[part 1 of 3: packages /MICROSAR/Dem_swc/DataTypes to /MICROSAR/Dem_swc/ComponentTypes]
AUTOSAR XML (schema 00050)
package /MICROSAR/Dem_swc/DataTypes
  28 x impl type:
    Dem_EventIdType: range raw 1..65535, implementation-data-type=uint16
    Dem_RatioIdType: range raw 1..65535, implementation-data-type=uint16
    Dem_DTCStatusMaskType: range raw 0..255, implementation-data-type=uint8
    Dem_OperationCycleIdType: range raw 0..255, implementation-data-type=uint8
    Dem_DTCGroupType: range raw 0..16777215, implementation-data-type=uint32
    Dem_EventStatusType:
      compu {0=DEM_EVENT_STATUS_PASSED, 1=DEM_EVENT_STATUS_FAILED, 2=DEM_EVENT_STATUS_PREPASSED, 3=DEM_EVENT_STATUS_PREFAILED, 4=DEM_EVENT_STATUS_FDC_THRESHOLD_REACHED, 5=DEM_EVENT_STATUS_PASSED_CONDITIONS_NOT_FULFILLED, 6=DEM_EVENT_STATUS_FAILED_CONDITIONS_NOT_FULFILLED, 7=DEM_EVENT_STATUS_PREPASSED_CONDITIONS_NOT_FULFILLED, 8=DEM_EVENT_STATUS_PREFAILED_CONDITIONS_NOT_FULFILLED}
      range raw 0..255
      implementation-data-type=uint8
    Dem_InitMonitorReasonType: compu {1=DEM_INIT_MONITOR_CLEAR, 2=DEM_INIT_MONITOR_RESTART, 3=DEM_INIT_MONITOR_REENABLED, 4=DEM_INIT_MONITOR_STORAGE_REENABLED}, range raw 1..4, implementation-data-type=uint8
    Dem_DTCOriginType: compu {1=DEM_DTC_ORIGIN_PRIMARY_MEMORY, 2=DEM_DTC_ORIGIN_MIRROR_MEMORY, 3=DEM_DTC_ORIGIN_PERMANENT_MEMORY, 4=DEM_DTC_ORIGIN_OBD_RELEVANT_MEMORY, 256=DEM_DTC_ORIGIN_SECONDARY_MEMORY}, range raw 1..511, implementation-data-type=uint16
    Dem_DTCFormatType: compu {0=DEM_DTC_FORMAT_OBD, 1=DEM_DTC_FORMAT_UDS, 2=DEM_DTC_FORMAT_J1939}, range raw 0..2, implementation-data-type=uint8
    Dem_OperationCycleStateType: compu {0=DEM_CYCLE_STATE_START, 1=DEM_CYCLE_STATE_END}, range raw 0..1, implementation-data-type=uint8
    Dem_IndicatorStatusType: compu {0=DEM_INDICATOR_OFF, 1=DEM_INDICATOR_CONTINUOUS, 2=DEM_INDICATOR_BLINKING, 3=DEM_INDICATOR_BLINK_CONT, 4=DEM_INDICATOR_SLOW_FLASH, 5=DEM_INDICATOR_FAST_FLASH, 6=DEM_INDICATOR_ON_DEMAND, 7=DEM_INDICATOR_SHORT}, range raw 0..7, implementation-data-type=uint8
    Dem_DTCKindType: compu {1=DEM_DTC_KIND_ALL_DTCS, 2=DEM_DTC_KIND_EMISSION_REL_DTCS}, range raw 0..255, implementation-data-type=uint8
    Dem_IumprDenomCondIdType: compu {1=DEM_IUMPR_GENERAL_DENOMINATOR, 2=DEM_IUMPR_DEN_COND_COLDSTART, 3=DEM_IUMPR_DEN_COND_EVAP, 4=DEM_IUMPR_DEN_COND_500MI, 5=DEM_IUMPR_GENERAL_INDIVIDUAL_DENOMINATOR, 6=DEM_IUMPR_GENERAL_OBDCOND, 7=DEM_IUMPR_DEN_COND_INDEPENDENT}, range raw 0..255, implementation-data-type=uint8
    Dem_IumprDenomCondStatusType: compu {0=DEM_IUMPR_DEN_STATUS_NOT_REACHED, 1=DEM_IUMPR_DEN_STATUS_REACHED, 2=DEM_IUMPR_DEN_STATUS_INHIBITED}, range raw 0..255, implementation-data-type=uint8
    Dem_DebounceResetStatusType: compu {0=DEM_DEBOUNCE_STATUS_FREEZE, 1=DEM_DEBOUNCE_STATUS_RESET}, range raw 0..255, implementation-data-type=uint8
    Dem_IumprReadinessGroupType:
      compu {0=DEM_IUMPR_BOOSTPRS, 1=DEM_IUMPR_CAT1, 2=DEM_IUMPR_CAT2, 3=DEM_IUMPR_EGR, 4=DEM_IUMPR_EGSENSOR, 5=DEM_IUMPR_EVAP, 6=DEM_IUMPR_NMHCCAT, 7=DEM_IUMPR_NOXADSORB, 8=DEM_IUMPR_NOXCAT, 9=DEM_IUMPR_OXS1, 10=DEM_IUMPR_OXS2, 11=DEM_IUMPR_PMFILTER, 12=DEM_IUMPR_PRIVATE, 13=DEM_IUMPR_SAIR, 14=DEM_IUMPR_SECOXS1, 15=DEM_IUMPR_SECOXS2, 16=DEM_IUMPR_FLSYS, 17=DEM_IUMPR_AFRI1, 18=DEM_IUMPR_AFRI2, 19=DEM_IUMPR_PF1, 20=DEM_IUMPR_PF2, 255=DEM_IUMPR_ALLGROUPS}
      range raw 0..255
      implementation-data-type=uint8
    Dem_DTRControlType: compu {0=DEM_DTR_CTL_NORMAL, 1=DEM_DTR_CTL_NO_MAX, 2=DEM_DTR_CTL_NO_MIN, 3=DEM_DTR_CTL_RESET, 4=DEM_DTR_CTL_INVISIBLE}, range raw 0..255, implementation-data-type=uint8
    Dem_DebouncingStateType:
      compu {mask 1: 1=DEM_TEMPORARILY_DEFECTIVE (Bit 0: Temporarily Defective (corresponds to 0 < FDC < 127)), mask 2: 2=DEM_FINALLY_DEFECTIVE (Bit 1: Finally Defective (corresponds to FDC = 127)), mask 4: 4=DEM_TEMPORARILY_HEALED (Bit 2: Temporarily healed (corresponds to -128 < FDC < 0)), mask 8: 8=DEM_TEST_COMPLETE (Bit 3: Test complete (corresponds to FDC = -128 or FDC = 127)), mask 16: 16=DEM_DTR_UPDATE (Bit 4: DTR Update (= Test complete && Debouncing complete && enable conditions / storage conditions fulfilled))}
      range raw 0..255
      implementation-data-type=uint8
    Dem_DTCSeverityType:
      compu {mask 255: 0=DEM_SEVERITY_NO_SEVERITY (DTC_NO_SEVERITY) (No severity information available), mask 31: 1=DEM_SEVERITY_WWHOBD_CLASS_NO_CLASS (DTC_CLASS) (No class information), mask 31: 2=DEM_SEVERITY_WWHOBD_CLASS_A (DTC_CLASS) (WWH-OBD Class A), mask 31: 4=DEM_SEVERITY_WWHOBD_CLASS_B1 (DTC_CLASS) (WWH-OBD Class B1), mask 31: 8=DEM_SEVERITY_WWHOBD_CLASS_B2 (DTC_CLASS) (WWH-OBD Class B2), mask 31: 16=DEM_SEVERITY_WWHOBD_CLASS_C (DTC_CLASS) (WWH-OBD Class C), mask 224: 32=DEM_SEVERITY_MAINTENANCE_ONLY (DTC_SEVERITY) (Maintenance required), mask 224: 64=DEM_SEVERITY_CHECK_AT_NEXT_HALT (DTC_SEVERITY) (Check at next halt), mask 224: 128=DEM_SEVERITY_CHECK_IMMEDIATELY (DTC_SEVERITY) (Check immediately)}
      range raw 0..255
      implementation-data-type=uint8
    Dem_UdsStatusByteType:
      compu {mask 1: 1=DEM_UDS_STATUS_TF (bit 0: TestFailed), mask 2: 2=DEM_UDS_STATUS_TFTOC (bit 1: TestFailedThisOperationCycle), mask 4: 4=DEM_UDS_STATUS_PDTC (bit 2: PendingDTC), mask 8: 8=DEM_UDS_STATUS_CDTC (bit 3: ConfirmedDTC), mask 16: 16=DEM_UDS_STATUS_TNCSLC (bit 4: TestNotCompletedSinceLastClear), mask 32: 32=DEM_UDS_STATUS_TFSLC (bit 5: TestFailedSinceLastClear), mask 64: 64=DEM_UDS_STATUS_TNCTOC (bit 6: TestNotCompletedThisOperationCycle), mask 128: 128=DEM_UDS_STATUS_WIR (bit 7: WarningIndicatorRequested)}
      range raw 0..255
      implementation-data-type=uint8
    Dem_MonitorStatusType: compu {mask 1: 1=DEM_MONITOR_STATUS_TF (bit 0: TestFailed), mask 2: 2=DEM_MONITOR_STATUS_TNCTOC (bit 1: TestNotCompletedThisOperationCycle)}, range raw 0..255, implementation-data-type=uint8
    DataArrayType_uint8_1: category=ARRAY, sw-calibration-access=READ-ONLY
      element DataArrayType_uint8_1Element: array-size=1, array-size-semantics=FIXED-SIZE, implementation-data-type=uint8
    DataArrayType_uint8_3: category=ARRAY, sw-calibration-access=READ-ONLY
      element DataArrayType_uint8_3Element: array-size=3, array-size-semantics=FIXED-SIZE, implementation-data-type=uint8
    DataArrayType_uint8_2: category=ARRAY, sw-calibration-access=READ-ONLY
      element DataArrayType_uint8_2Element: array-size=2, array-size-semantics=FIXED-SIZE, implementation-data-type=uint8
    DataPrimitiveType_uint16: implementation-data-type=uint16
    DataArrayType_uint8_9: category=ARRAY, sw-calibration-access=READ-ONLY
      element DataArrayType_uint8_9Element: array-size=9, array-size-semantics=FIXED-SIZE, implementation-data-type=uint8
    DataPrimitiveType_uint8: implementation-data-type=uint8
    Dem_MaxDataValueType: category=ARRAY, sw-calibration-access=READ-ONLY
      element Dem_MaxDataValueTypeElement: array-size=51, array-size-semantics=FIXED-SIZE, implementation-data-type=uint8
package /MICROSAR/Dem_swc/Interfaces
  46 x client server interface, all with is-service=true, service-kind=DIAGNOSTIC-EVENT-MANAGER:
    DemServices
      operation GetPostRunRequested: possible-error=DemServices/E_NOT_OK
        arg IsRequested: type=boolean, direction=OUT
      operation GetDTCStatusAvailabilityMask: possible-error=DemServices/E_NOT_OK
        arg ClientId: type=uint8, direction=IN
        arg DTCStatusMask: type=uint8, direction=OUT
      error E_NOT_OK: error-code=1
    ClearDTC
      operation ClearDTC: possible-error=[ClearDTC/E_NOT_OK, DEM_CLEAR_FAILED, DEM_PENDING, DEM_CLEAR_BUSY, DEM_CLEAR_MEMORY_ERROR, DEM_WRONG_DTC, DEM_WRONG_DTCORIGIN]
      operation SelectDTC: possible-error=[ClearDTC/E_OK, ClearDTC/E_NOT_OK]
        arg DTC: type=uint32, direction=IN
        arg DTCFormat: type=Dem_DTCFormatType, direction=IN
        arg DTCOrigin: type=Dem_DTCOriginType, direction=IN
      8 x error:
        E_OK: error-code=0
        E_NOT_OK: error-code=1
        DEM_CLEAR_FAILED: error-code=7
        DEM_PENDING: error-code=4
        DEM_CLEAR_BUSY: error-code=5
        DEM_CLEAR_MEMORY_ERROR: error-code=6
        DEM_WRONG_DTC: error-code=8
        DEM_WRONG_DTCORIGIN: error-code=9
    EnableCondition
      operation SetEnableCondition: possible-error=EnableCondition/E_NOT_OK
        arg ConditionFulfilled: type=boolean, direction=IN
      error E_NOT_OK: error-code=1
    EvMemOverflowIndication
      operation GetEventMemoryOverflow: possible-error=EvMemOverflowIndication/E_NOT_OK
        arg OverflowIndication: type=boolean, direction=OUT
      operation GetNumberOfEventMemoryEntries: possible-error=EvMemOverflowIndication/E_NOT_OK
        arg NumberOfEventMemoryEntries: type=uint8, direction=OUT
      error E_NOT_OK: error-code=1
    GeneralDiagnosticInfo
      11 x operation:
        GetEventUdsStatus: possible-error=GeneralDiagnosticInfo/E_NOT_OK
          arg EventId: type=Dem_EventIdType, direction=IN
          arg UDSStatusByte: type=Dem_UdsStatusByteType, direction=OUT
        GetEventStatus: possible-error=GeneralDiagnosticInfo/E_NOT_OK
          arg EventId: type=Dem_EventIdType, direction=IN
          arg UDSStatusByte: type=Dem_UdsStatusByteType, direction=OUT
        GetEventFailed: possible-error=GeneralDiagnosticInfo/E_NOT_OK
          arg EventId: type=Dem_EventIdType, direction=IN
          arg EventFailed: type=boolean, direction=OUT
        GetEventTested: possible-error=GeneralDiagnosticInfo/E_NOT_OK
          arg EventId: type=Dem_EventIdType, direction=IN
          arg EventTested: type=boolean, direction=OUT
        GetDTCOfEvent: possible-error=[GeneralDiagnosticInfo/E_NOT_OK, GeneralDiagnosticInfo/DEM_E_NO_DTC_AVAILABLE]
          arg EventId: type=Dem_EventIdType, direction=IN
          arg DTCFormat: type=Dem_DTCFormatType, direction=IN
          arg DTCOfEvent: type=uint32, direction=OUT
        GetFaultDetectionCounter: possible-error=[GeneralDiagnosticInfo/E_NOT_OK, GeneralDiagnosticInfo/DEM_E_NO_FDC_AVAILABLE]
          arg EventId: type=Dem_EventIdType, direction=IN
          arg FaultDetectionCounter: type=sint8, direction=OUT
        GetEventFreezeFrameDataEx: possible-error=[GeneralDiagnosticInfo/E_NOT_OK, GeneralDiagnosticInfo/DEM_BUFFER_TOO_SMALL, GeneralDiagnosticInfo/DEM_NO_SUCH_ELEMENT]
          5 x arg:
            EventId: type=Dem_EventIdType, direction=IN
            RecordNumber: type=uint8, direction=IN
            DataId: type=uint16, direction=IN
            DestBuffer: type=Dem_MaxDataValueType, direction=OUT
            BufSize: type=uint16, direction=INOUT
        GetEventExtendedDataRecordEx: possible-error=[GeneralDiagnosticInfo/E_NOT_OK, GeneralDiagnosticInfo/DEM_BUFFER_TOO_SMALL, GeneralDiagnosticInfo/DEM_NO_SUCH_ELEMENT]
          4 x arg:
            EventId: type=Dem_EventIdType, direction=IN
            RecordNumber: type=uint8, direction=IN
            DestBuffer: type=Dem_MaxDataValueType, direction=OUT
            BufSize: type=uint16, direction=INOUT
        GetEventEnableCondition: possible-error=GeneralDiagnosticInfo/E_NOT_OK
          arg EventId: type=Dem_EventIdType, direction=IN
          arg ConditionFullfilled: type=boolean, direction=OUT
        GetDebouncingOfEvent: possible-error=GeneralDiagnosticInfo/E_NOT_OK
          arg EventId: type=Dem_EventIdType, direction=IN
          arg DebouncingState: type=Dem_DebouncingStateType, direction=OUT
        GetMonitorStatus: possible-error=GeneralDiagnosticInfo/E_NOT_OK
          arg EventId: type=Dem_EventIdType, direction=IN
          arg MonitorStatus: type=Dem_MonitorStatusType, direction=OUT
      5 x error:
        E_NOT_OK: error-code=1
        DEM_E_NO_DTC_AVAILABLE: error-code=10
        DEM_E_NO_FDC_AVAILABLE: error-code=14
        DEM_BUFFER_TOO_SMALL: error-code=21
        DEM_NO_SUCH_ELEMENT: error-code=48
    OperationCycle
      operation GetOperationCycleState: possible-error=[OperationCycle/E_OK, OperationCycle/E_NOT_OK]
        arg CycleState: type=Dem_OperationCycleStateType, direction=OUT
      operation SetOperationCycleState: possible-error=[OperationCycle/E_OK, OperationCycle/E_NOT_OK]
        arg CycleState: type=Dem_OperationCycleStateType, direction=IN
      error E_OK: error-code=0
      error E_NOT_OK: error-code=1
    CSDataServices_Data_DID_0x1004_Battery_Voltage_24
      operation ReadData: possible-error=CSDataServices_Data_DID_0x1004_Battery_Voltage_24/E_NOT_OK
        arg Data: type=DataArrayType_uint8_1, direction=OUT
      error E_NOT_OK: error-code=1
    CSDataServices_Data_DID_0x1008_ECU_Life_Time_24
      operation ReadData: possible-error=CSDataServices_Data_DID_0x1008_ECU_Life_Time_24/E_NOT_OK
        arg Data: type=DataArrayType_uint8_3, direction=OUT
      error E_NOT_OK: error-code=1
    CSDataServices_Data_DID_0x1009_ECU_Time_Since_Ignition_ON
      operation ReadData: possible-error=CSDataServices_Data_DID_0x1009_ECU_Time_Since_Ignition_ON/E_NOT_OK
        arg Data: type=DataArrayType_uint8_2, direction=OUT
      error E_NOT_OK: error-code=1
    CSDataServices_Data_OccurrenceCounter_Aging_Counter_ID
      operation ReadData: possible-error=CSDataServices_Data_OccurrenceCounter_Aging_Counter_ID/E_NOT_OK
        arg Data: type=DataPrimitiveType_uint16, direction=OUT
      error E_NOT_OK: error-code=1
    CSDataServices_Data_OccurrenceCounter_Frequency_Counter_ID
      operation ReadData: possible-error=CSDataServices_Data_OccurrenceCounter_Frequency_Counter_ID/E_NOT_OK
        arg Data: type=DataPrimitiveType_uint16, direction=OUT
      error E_NOT_OK: error-code=1
    CSDataServices_Data_DID_0x200a_Ignition_ON_Counter_24
      operation ReadData: possible-error=CSDataServices_Data_DID_0x200a_Ignition_ON_Counter_24/E_NOT_OK
        arg Data: type=DataArrayType_uint8_2, direction=OUT
      error E_NOT_OK: error-code=1
    CSDataServices_Data_DID_0x1002_Vehicle_Speed_24
      operation ReadData: possible-error=CSDataServices_Data_DID_0x1002_Vehicle_Speed_24/E_NOT_OK
        arg Data: type=DataArrayType_uint8_2, direction=OUT
      error E_NOT_OK: error-code=1
    CSDataServices_Data_DID_0x2001_Odometer_24
      operation ReadData: possible-error=CSDataServices_Data_DID_0x2001_Odometer_24/E_NOT_OK
        arg Data: type=DataArrayType_uint8_2, direction=OUT
      error E_NOT_OK: error-code=1
    CSDataServices_Data_OccurrenceCounter_Touch_Screen_Y_Coordinate
      operation ReadData: possible-error=CSDataServices_Data_OccurrenceCounter_Touch_Screen_Y_Coordinate/E_NOT_OK
        arg Data: type=DataPrimitiveType_uint16, direction=OUT
      error E_NOT_OK: error-code=1
    CSDataServices_Data_OccurrenceCounter_Odometer_Value
      operation ReadData: possible-error=CSDataServices_Data_OccurrenceCounter_Odometer_Value/E_NOT_OK
        arg Data: type=DataArrayType_uint8_3, direction=OUT
      error E_NOT_OK: error-code=1
    CSDataServices_Data_OccurrenceCounter_Camera_Occlusion
      operation ReadData: possible-error=CSDataServices_Data_OccurrenceCounter_Camera_Occlusion/E_NOT_OK
        arg Data: type=DataPrimitiveType_uint8, direction=OUT
      error E_NOT_OK: error-code=1
    CSDataServices_Data_OccurrenceCounter_THA_state
      operation ReadData: possible-error=CSDataServices_Data_OccurrenceCounter_THA_state/E_NOT_OK
        arg Data: type=DataPrimitiveType_uint8, direction=OUT
      error E_NOT_OK: error-code=1
    CSDataServices_Data_OccurrenceCounter_Supplier_Internal_Code
      operation ReadData: possible-error=CSDataServices_Data_OccurrenceCounter_Supplier_Internal_Code/E_NOT_OK
        arg EventId: type=Dem_EventIdType, direction=IN
        arg Data: type=DataArrayType_uint8_9, direction=OUT
      error E_NOT_OK: error-code=1
    CSDataServices_Data_OccurrenceCounter_Current_Gear
      operation ReadData: possible-error=CSDataServices_Data_OccurrenceCounter_Current_Gear/E_NOT_OK
        arg Data: type=DataPrimitiveType_uint8, direction=OUT
      error E_NOT_OK: error-code=1
    CSDataServices_Data_OccurrenceCounter_Vehicle_Speed
      operation ReadData: possible-error=CSDataServices_Data_OccurrenceCounter_Vehicle_Speed/E_NOT_OK
        arg Data: type=DataPrimitiveType_uint16, direction=OUT
      error E_NOT_OK: error-code=1
    CSDataServices_Data_OccurrenceCounter_DisplayStatus
      operation ReadData: possible-error=CSDataServices_Data_OccurrenceCounter_DisplayStatus/E_NOT_OK
        arg Data: type=DataPrimitiveType_uint8, direction=OUT
      error E_NOT_OK: error-code=1
    CSDataServices_Data_OccurrenceCounter_TRSC_Stat
      operation ReadData: possible-error=CSDataServices_Data_OccurrenceCounter_TRSC_Stat/E_NOT_OK
        arg Data: type=DataPrimitiveType_uint8, direction=OUT
      error E_NOT_OK: error-code=1
    CSDataServices_Data_OccurrenceCounter_ECU_Voltage
      operation ReadData: possible-error=CSDataServices_Data_OccurrenceCounter_ECU_Voltage/E_NOT_OK
        arg Data: type=DataPrimitiveType_uint8, direction=OUT
      error E_NOT_OK: error-code=1
    CSDataServices_Data_OccurrenceCounter_Touch_Screen_X_Coordinate
      operation ReadData: possible-error=CSDataServices_Data_OccurrenceCounter_Touch_Screen_X_Coordinate/E_NOT_OK
        arg Data: type=DataPrimitiveType_uint16, direction=OUT
      error E_NOT_OK: error-code=1
    CSDataServices_Data_OccurrenceCounter_Touch_Screen_Status
      operation ReadData: possible-error=CSDataServices_Data_OccurrenceCounter_Touch_Screen_Status/E_NOT_OK
        arg Data: type=DataPrimitiveType_uint8, direction=OUT
      error E_NOT_OK: error-code=1
    CSDataServices_Data_OccurrenceCounter_External_Temperature
      operation ReadData: possible-error=CSDataServices_Data_OccurrenceCounter_External_Temperature/E_NOT_OK
        arg Data: type=DataPrimitiveType_uint16, direction=OUT
      error E_NOT_OK: error-code=1
    CSDataServices_Data_OccurrenceCounter_TireLines
      operation ReadData: possible-error=CSDataServices_Data_OccurrenceCounter_TireLines/E_NOT_OK
        arg Data: type=DataPrimitiveType_uint8, direction=OUT
      error E_NOT_OK: error-code=1
    CSDataServices_Data_OccurrenceCounter_Door_Status
      operation ReadData: possible-error=CSDataServices_Data_OccurrenceCounter_Door_Status/E_NOT_OK
        arg Data: type=DataPrimitiveType_uint8, direction=OUT
      error E_NOT_OK: error-code=1
    CSDataServices_Data_OccurrenceCounter_Radio_Display_Status
      operation ReadData: possible-error=CSDataServices_Data_OccurrenceCounter_Radio_Display_Status/E_NOT_OK
        arg Data: type=DataPrimitiveType_uint8, direction=OUT
      error E_NOT_OK: error-code=1
    CSDataServices_Data_OccurrenceCounter_TRSKM_and_USS_status
      operation ReadData: possible-error=CSDataServices_Data_OccurrenceCounter_TRSKM_and_USS_status/E_NOT_OK
        arg Data: type=DataPrimitiveType_uint8, direction=OUT
      error E_NOT_OK: error-code=1
    CSDataServices_Data_OccurrenceCounter_LiftgateAjar
      operation ReadData: possible-error=CSDataServices_Data_OccurrenceCounter_LiftgateAjar/E_NOT_OK
        arg Data: type=DataPrimitiveType_uint8, direction=OUT
      error E_NOT_OK: error-code=1
    CSDataServices_Data_OccurrenceCounter_Cycles_to_Switch_off_the_Warning_Indication_ID
      operation ReadData: possible-error=CSDataServices_Data_OccurrenceCounter_Cycles_to_Switch_off_the_Warning_Indication_ID/E_NOT_OK
        arg Data: type=DataPrimitiveType_uint16, direction=OUT
      error E_NOT_OK: error-code=1
    CSDataServices_Data_OccurrenceCounter_Steering_Wheel_Angle
      operation ReadData: possible-error=CSDataServices_Data_OccurrenceCounter_Steering_Wheel_Angle/E_NOT_OK
        arg Data: type=DataPrimitiveType_uint16, direction=OUT
      error E_NOT_OK: error-code=1
    CSDataServices_Data_OccurrenceCounter_Reserved
      operation ReadData: possible-error=CSDataServices_Data_OccurrenceCounter_Reserved/E_NOT_OK
        arg Data: type=DataPrimitiveType_uint8, direction=OUT
      error E_NOT_OK: error-code=1
    CSDataServices_Data_OccurrenceCounter_Reserved_1
      operation ReadData: possible-error=CSDataServices_Data_OccurrenceCounter_Reserved_1/E_NOT_OK
        arg Data: type=DataPrimitiveType_uint8, direction=OUT
      error E_NOT_OK: error-code=1
    CSDataServices_Data_OccurrenceCounter_Calibration_Aborted_Failed
      operation ReadData: possible-error=CSDataServices_Data_OccurrenceCounter_Calibration_Aborted_Failed/E_NOT_OK
        arg Data: type=DataPrimitiveType_uint8, direction=OUT
      error E_NOT_OK: error-code=1
    CSDataServices_Data_OccurrenceCounter_Calibration_Pending
      operation ReadData: possible-error=CSDataServices_Data_OccurrenceCounter_Calibration_Pending/E_NOT_OK
        arg Data: type=DataPrimitiveType_uint8, direction=OUT
      error E_NOT_OK: error-code=1
    CSDataServices_Data_OccurrenceCounter_Calibration_Running
      operation ReadData: possible-error=CSDataServices_Data_OccurrenceCounter_Calibration_Running/E_NOT_OK
        arg Data: type=DataPrimitiveType_uint8, direction=OUT
      error E_NOT_OK: error-code=1
    CSDataServices_Data_OccurrenceCounter_New_Bit_Field
      operation ReadData: possible-error=CSDataServices_Data_OccurrenceCounter_New_Bit_Field/E_NOT_OK
        arg Data: type=DataPrimitiveType_uint8, direction=OUT
      error E_NOT_OK: error-code=1
    CSDataServices_Data_OccurrenceCounter_Calibration_Not_Started
      operation ReadData: possible-error=CSDataServices_Data_OccurrenceCounter_Calibration_Not_Started/E_NOT_OK
        arg Data: type=DataPrimitiveType_uint8, direction=OUT
      error E_NOT_OK: error-code=1
    CSDataServices_Data_OccurrenceCounter_Calibrated_Successfully
      operation ReadData: possible-error=CSDataServices_Data_OccurrenceCounter_Calibrated_Successfully/E_NOT_OK
        arg Data: type=DataPrimitiveType_uint8, direction=OUT
      error E_NOT_OK: error-code=1
    CSDataServices_Data_OccurrenceCounter_Reserved_2
      operation ReadData: possible-error=CSDataServices_Data_OccurrenceCounter_Reserved_2/E_NOT_OK
        arg Data: type=DataPrimitiveType_uint8, direction=OUT
      error E_NOT_OK: error-code=1
    DiagnosticInfo
      11 x operation:
        GetEventUdsStatus: possible-error=DiagnosticInfo/E_NOT_OK
          arg UDSStatusByte: type=Dem_UdsStatusByteType, direction=OUT
        GetEventStatus: possible-error=DiagnosticInfo/E_NOT_OK
          arg UDSStatusByte: type=Dem_UdsStatusByteType, direction=OUT
        GetEventFailed: possible-error=DiagnosticInfo/E_NOT_OK
          arg EventFailed: type=boolean, direction=OUT
        GetEventTested: possible-error=DiagnosticInfo/E_NOT_OK
          arg EventTested: type=boolean, direction=OUT
        GetDTCOfEvent: possible-error=[DiagnosticInfo/E_NOT_OK, DiagnosticInfo/DEM_E_NO_DTC_AVAILABLE]
          arg DTCFormat: type=Dem_DTCFormatType, direction=IN
          arg DTCOfEvent: type=uint32, direction=OUT
        GetFaultDetectionCounter: possible-error=[DiagnosticInfo/E_NOT_OK, DiagnosticInfo/DEM_E_NO_FDC_AVAILABLE]
          arg FaultDetectionCounter: type=sint8, direction=OUT
        GetEventFreezeFrameDataEx: possible-error=[DiagnosticInfo/E_NOT_OK, DiagnosticInfo/DEM_BUFFER_TOO_SMALL, DiagnosticInfo/DEM_NO_SUCH_ELEMENT]
          4 x arg:
            RecordNumber: type=uint8, direction=IN
            DataId: type=uint16, direction=IN
            DestBuffer: type=Dem_MaxDataValueType, direction=OUT
            BufSize: type=uint16, direction=INOUT
        GetEventExtendedDataRecordEx: possible-error=[DiagnosticInfo/E_NOT_OK, DiagnosticInfo/DEM_BUFFER_TOO_SMALL, DiagnosticInfo/DEM_NO_SUCH_ELEMENT]
          arg RecordNumber: type=uint8, direction=IN
          arg DestBuffer: type=Dem_MaxDataValueType, direction=OUT
          arg BufSize: type=uint16, direction=INOUT
        GetEventEnableCondition: possible-error=DiagnosticInfo/E_NOT_OK
          arg ConditionFullfilled: type=boolean, direction=OUT
        GetDebouncingOfEvent: possible-error=DiagnosticInfo/E_NOT_OK
          arg DebouncingState: type=Dem_DebouncingStateType, direction=OUT
        GetMonitorStatus: possible-error=DiagnosticInfo/E_NOT_OK
          arg MonitorStatus: type=Dem_MonitorStatusType, direction=OUT
      5 x error:
        E_NOT_OK: error-code=1
        DEM_E_NO_DTC_AVAILABLE: error-code=10
        DEM_E_NO_FDC_AVAILABLE: error-code=14
        DEM_BUFFER_TOO_SMALL: error-code=21
        DEM_NO_SUCH_ELEMENT: error-code=48
    DiagnosticMonitor
      11 x operation:
        SetEventStatus: possible-error=DiagnosticMonitor/E_NOT_OK
          arg EventStatus: type=Dem_EventStatusType, direction=IN
        ResetEventStatus: possible-error=DiagnosticMonitor/E_NOT_OK
        ResetEventDebounceStatus: possible-error=DiagnosticMonitor/E_NOT_OK
          arg DebounceResetStatus: type=Dem_DebounceResetStatusType, direction=IN
        GetEventUdsStatus: possible-error=DiagnosticMonitor/E_NOT_OK
          arg UDSStatusByte: type=Dem_UdsStatusByteType, direction=OUT
        GetEventStatus: possible-error=DiagnosticMonitor/E_NOT_OK
          arg UDSStatusByte: type=Dem_UdsStatusByteType, direction=OUT
        GetEventFailed: possible-error=DiagnosticMonitor/E_NOT_OK
          arg EventFailed: type=boolean, direction=OUT
        GetEventTested: possible-error=DiagnosticMonitor/E_NOT_OK
          arg EventTested: type=boolean, direction=OUT
        GetDTCOfEvent: possible-error=[DiagnosticMonitor/E_NOT_OK, DiagnosticMonitor/DEM_E_NO_DTC_AVAILABLE]
          arg DTCFormat: type=Dem_DTCFormatType, direction=IN
          arg DTCOfEvent: type=uint32, direction=OUT
        GetFaultDetectionCounter: possible-error=[DiagnosticMonitor/E_NOT_OK, DiagnosticMonitor/DEM_E_NO_FDC_AVAILABLE]
          arg FaultDetectionCounter: type=sint8, direction=OUT
        GetEventFreezeFrameDataEx: possible-error=[DiagnosticMonitor/E_NOT_OK, DiagnosticMonitor/DEM_BUFFER_TOO_SMALL, DiagnosticMonitor/DEM_NO_SUCH_ELEMENT]
          4 x arg:
            RecordNumber: type=uint8, direction=IN
            DataId: type=uint16, direction=IN
            DestBuffer: type=Dem_MaxDataValueType, direction=OUT
            BufSize: type=uint16, direction=INOUT
        GetEventExtendedDataRecordEx: possible-error=[DiagnosticMonitor/E_NOT_OK, DiagnosticMonitor/DEM_BUFFER_TOO_SMALL, DiagnosticMonitor/DEM_NO_SUCH_ELEMENT]
          arg RecordNumber: type=uint8, direction=IN
          arg DestBuffer: type=Dem_MaxDataValueType, direction=OUT
          arg BufSize: type=uint16, direction=INOUT
      5 x error:
        E_NOT_OK: error-code=1
        DEM_E_NO_DTC_AVAILABLE: error-code=10
        DEM_E_NO_FDC_AVAILABLE: error-code=14
        DEM_BUFFER_TOO_SMALL: error-code=21
        DEM_NO_SUCH_ELEMENT: error-code=48
    CSDataServices_Data_DID_0x1921_CombinedSignal
      operation ReadData: possible-error=CSDataServices_Data_DID_0x1921_CombinedSignal/E_NOT_OK
        arg Data: type=DataArrayType_uint8_9, direction=OUT
      error E_NOT_OK: error-code=1
package /MICROSAR/Dem_swc/ComponentTypes
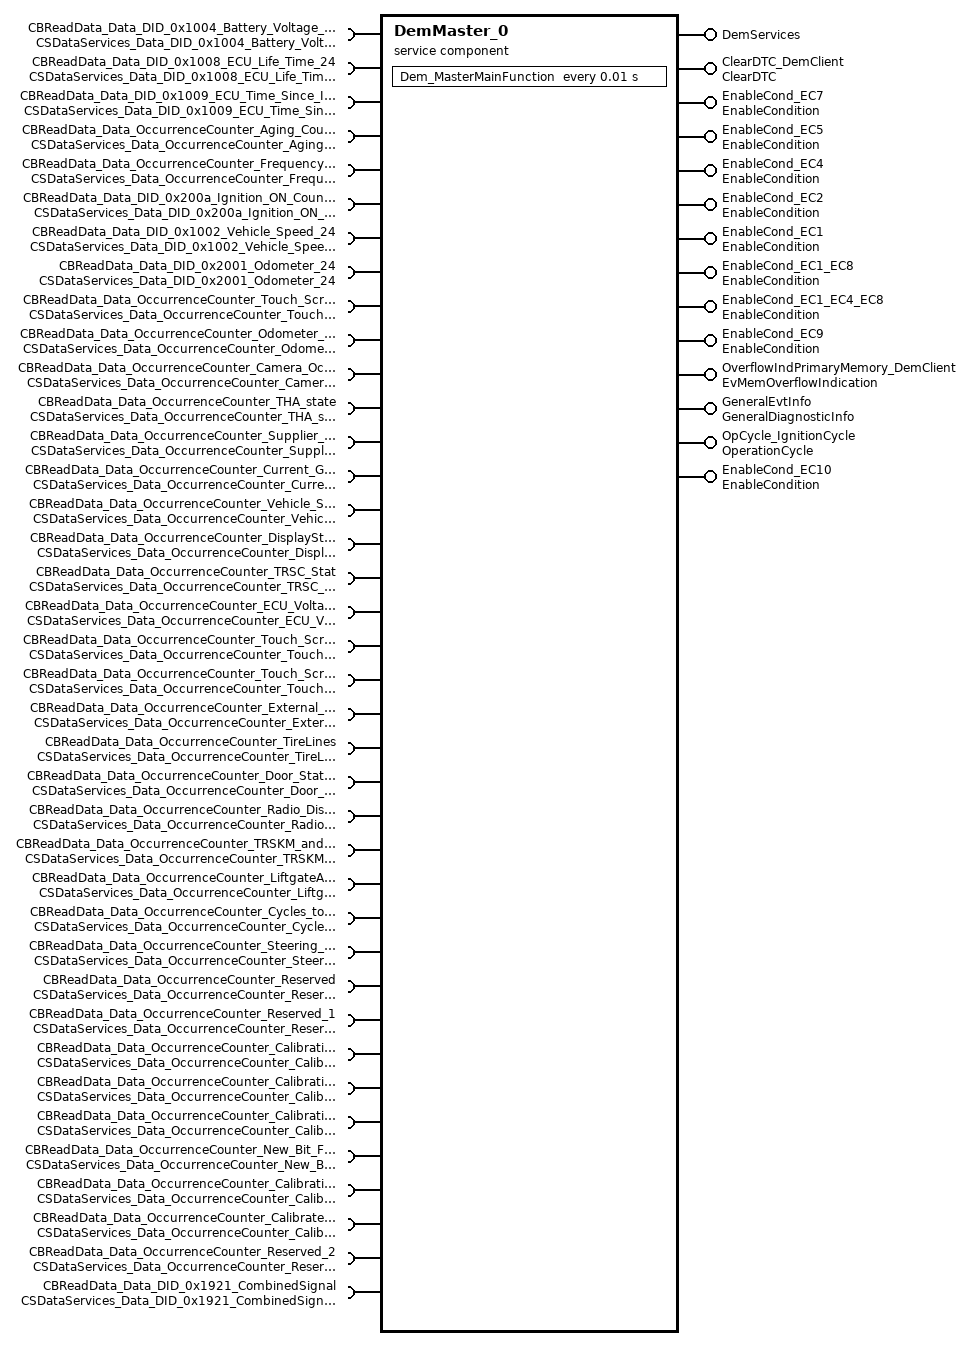
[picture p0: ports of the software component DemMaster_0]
  service sw component type DemMaster_0: category=SERVICE_COMPONENT
    13 x provide port:
      DemServices: provided-interface=DemServices
      ClearDTC_DemClient: provided-interface=ClearDTC
      EnableCond_EC7: provided-interface=EnableCondition
      EnableCond_EC5: provided-interface=EnableCondition
      EnableCond_EC4: provided-interface=EnableCondition
      EnableCond_EC2: provided-interface=EnableCondition
      EnableCond_EC1: provided-interface=EnableCondition
      EnableCond_EC1_EC8: provided-interface=EnableCondition
      EnableCond_EC1_EC4_EC8: provided-interface=EnableCondition
      EnableCond_EC9: provided-interface=EnableCondition
      OverflowIndPrimaryMemory_DemClient: provided-interface=EvMemOverflowIndication
      GeneralEvtInfo: provided-interface=GeneralDiagnosticInfo
      OpCycle_IgnitionCycle: provided-interface=OperationCycle
    38 x require port:
      CBReadData_Data_DID_0x1004_Battery_Voltage_24: required-interface=CSDataServices_Data_DID_0x1004_Battery_Voltage_24
      CBReadData_Data_DID_0x1008_ECU_Life_Time_24: required-interface=CSDataServices_Data_DID_0x1008_ECU_Life_Time_24
      CBReadData_Data_DID_0x1009_ECU_Time_Since_Ignition_ON: required-interface=CSDataServices_Data_DID_0x1009_ECU_Time_Since_Ignition_ON
      CBReadData_Data_OccurrenceCounter_Aging_Counter_ID: required-interface=CSDataServices_Data_OccurrenceCounter_Aging_Counter_ID
      CBReadData_Data_OccurrenceCounter_Frequency_Counter_ID: required-interface=CSDataServices_Data_OccurrenceCounter_Frequency_Counter_ID
      CBReadData_Data_DID_0x200a_Ignition_ON_Counter_24: required-interface=CSDataServices_Data_DID_0x200a_Ignition_ON_Counter_24
      CBReadData_Data_DID_0x1002_Vehicle_Speed_24: required-interface=CSDataServices_Data_DID_0x1002_Vehicle_Speed_24
      CBReadData_Data_DID_0x2001_Odometer_24: required-interface=CSDataServices_Data_DID_0x2001_Odometer_24
      CBReadData_Data_OccurrenceCounter_Touch_Screen_Y_Coordinate: required-interface=CSDataServices_Data_OccurrenceCounter_Touch_Screen_Y_Coordinate
      CBReadData_Data_OccurrenceCounter_Odometer_Value: required-interface=CSDataServices_Data_OccurrenceCounter_Odometer_Value
      CBReadData_Data_OccurrenceCounter_Camera_Occlusion: required-interface=CSDataServices_Data_OccurrenceCounter_Camera_Occlusion
      CBReadData_Data_OccurrenceCounter_THA_state: required-interface=CSDataServices_Data_OccurrenceCounter_THA_state
      CBReadData_Data_OccurrenceCounter_Supplier_Internal_Code: required-interface=CSDataServices_Data_OccurrenceCounter_Supplier_Internal_Code
      CBReadData_Data_OccurrenceCounter_Current_Gear: required-interface=CSDataServices_Data_OccurrenceCounter_Current_Gear
      CBReadData_Data_OccurrenceCounter_Vehicle_Speed: required-interface=CSDataServices_Data_OccurrenceCounter_Vehicle_Speed
      CBReadData_Data_OccurrenceCounter_DisplayStatus: required-interface=CSDataServices_Data_OccurrenceCounter_DisplayStatus
      CBReadData_Data_OccurrenceCounter_TRSC_Stat: required-interface=CSDataServices_Data_OccurrenceCounter_TRSC_Stat
      CBReadData_Data_OccurrenceCounter_ECU_Voltage: required-interface=CSDataServices_Data_OccurrenceCounter_ECU_Voltage
      CBReadData_Data_OccurrenceCounter_Touch_Screen_X_Coordinate: required-interface=CSDataServices_Data_OccurrenceCounter_Touch_Screen_X_Coordinate
      CBReadData_Data_OccurrenceCounter_Touch_Screen_Status: required-interface=CSDataServices_Data_OccurrenceCounter_Touch_Screen_Status
      CBReadData_Data_OccurrenceCounter_External_Temperature: required-interface=CSDataServices_Data_OccurrenceCounter_External_Temperature
      CBReadData_Data_OccurrenceCounter_TireLines: required-interface=CSDataServices_Data_OccurrenceCounter_TireLines
      CBReadData_Data_OccurrenceCounter_Door_Status: required-interface=CSDataServices_Data_OccurrenceCounter_Door_Status
      CBReadData_Data_OccurrenceCounter_Radio_Display_Status: required-interface=CSDataServices_Data_OccurrenceCounter_Radio_Display_Status
      CBReadData_Data_OccurrenceCounter_TRSKM_and_USS_status: required-interface=CSDataServices_Data_OccurrenceCounter_TRSKM_and_USS_status
      CBReadData_Data_OccurrenceCounter_LiftgateAjar: required-interface=CSDataServices_Data_OccurrenceCounter_LiftgateAjar
      CBReadData_Data_OccurrenceCounter_Cycles_to_Switch_off_the_Warning_Indication_ID: required-interface=CSDataServices_Data_OccurrenceCounter_Cycles_to_Switch_off_the_Warning_Indication_ID
      CBReadData_Data_OccurrenceCounter_Steering_Wheel_Angle: required-interface=CSDataServices_Data_OccurrenceCounter_Steering_Wheel_Angle
      CBReadData_Data_OccurrenceCounter_Reserved: required-interface=CSDataServices_Data_OccurrenceCounter_Reserved
      CBReadData_Data_OccurrenceCounter_Reserved_1: required-interface=CSDataServices_Data_OccurrenceCounter_Reserved_1
      CBReadData_Data_OccurrenceCounter_Calibration_Aborted_Failed: required-interface=CSDataServices_Data_OccurrenceCounter_Calibration_Aborted_Failed
      CBReadData_Data_OccurrenceCounter_Calibration_Pending: required-interface=CSDataServices_Data_OccurrenceCounter_Calibration_Pending
      CBReadData_Data_OccurrenceCounter_Calibration_Running: required-interface=CSDataServices_Data_OccurrenceCounter_Calibration_Running
      CBReadData_Data_OccurrenceCounter_New_Bit_Field: required-interface=CSDataServices_Data_OccurrenceCounter_New_Bit_Field
      CBReadData_Data_OccurrenceCounter_Calibration_Not_Started: required-interface=CSDataServices_Data_OccurrenceCounter_Calibration_Not_Started
      CBReadData_Data_OccurrenceCounter_Calibrated_Successfully: required-interface=CSDataServices_Data_OccurrenceCounter_Calibrated_Successfully
      CBReadData_Data_OccurrenceCounter_Reserved_2: required-interface=CSDataServices_Data_OccurrenceCounter_Reserved_2
      CBReadData_Data_DID_0x1921_CombinedSignal: required-interface=CSDataServices_Data_DID_0x1921_CombinedSignal
    provide port EnableCond_EC10: provided-interface=EnableCondition
    behavior DemMaster_0InternalBehavior: handle-termination-and-restart=NO-SUPPORT, included-data-type-set=data-type=[Dem_EventIdType, Dem_RatioIdType, Dem_EventStatusType, Dem_UdsStatusByteType, Dem_DTCFormatType, Dem_InitMonitorReasonType, Dem_OperationCycleStateType, Dem_DTCStatusMaskType, Dem_IndicatorStatusType, Dem_MaxDataValueType, Dem_DTCKindType, Dem_DTCGroupType, Dem_IumprDenomCondIdType, Dem_IumprDenomCondStatusType, Dem_DebounceResetStatusType, Dem_DebouncingStateType, Dem_IumprReadinessGroupType, Dem_DTRControlType, Dem_DTCSeverityType, Dem_MonitorStatusType]
      timing event Timer_Dem_MasterMainFunction: start-on-event=Dem_MasterMainFunction, period=0.01
      28 x operation invoked event:
        OpEventPostRunRequested_GetPostRunRequested_DemServices: start-on-event=PostRunRequested, operation=DemServices.GetPostRunRequested
        OpEventGetDTCStatusAvailabilityMask_GetDTCStatusAvailabilityMask_DemServices: start-on-event=GetDTCStatusAvailabilityMask, operation=DemServices.GetDTCStatusAvailabilityMask
        OpEventClearDTC_ClearDTC_ClearDTC_DemClient: start-on-event=ClearDTC, operation=ClearDTC_DemClient.ClearDTC
        OpEventSelectDTC_SelectDTC_ClearDTC_DemClient: start-on-event=SelectDTC, operation=ClearDTC_DemClient.SelectDTC
        OpEventSetEnableCondition_SetEnableCondition_EnableCond_EC7: start-on-event=SetEnableCondition, operation=EnableCond_EC7.SetEnableCondition
        OpEventSetEnableCondition_SetEnableCondition_EnableCond_EC5: start-on-event=SetEnableCondition, operation=EnableCond_EC5.SetEnableCondition
        OpEventSetEnableCondition_SetEnableCondition_EnableCond_EC4: start-on-event=SetEnableCondition, operation=EnableCond_EC4.SetEnableCondition
        OpEventSetEnableCondition_SetEnableCondition_EnableCond_EC2: start-on-event=SetEnableCondition, operation=EnableCond_EC2.SetEnableCondition
        OpEventSetEnableCondition_SetEnableCondition_EnableCond_EC1: start-on-event=SetEnableCondition, operation=EnableCond_EC1.SetEnableCondition
        OpEventSetEnableCondition_SetEnableCondition_EnableCond_EC1_EC8: start-on-event=SetEnableCondition, operation=EnableCond_EC1_EC8.SetEnableCondition
        OpEventSetEnableCondition_SetEnableCondition_EnableCond_EC1_EC4_EC8: start-on-event=SetEnableCondition, operation=EnableCond_EC1_EC4_EC8.SetEnableCondition
        OpEventSetEnableCondition_SetEnableCondition_EnableCond_EC9: start-on-event=SetEnableCondition, operation=EnableCond_EC9.SetEnableCondition
        OpEventGetEventMemoryOverflow_GetEventMemoryOverflow_OverflowIndPrimaryMemory_DemClient: start-on-event=GetEventMemoryOverflow, operation=OverflowIndPrimaryMemory_DemClient.GetEventMemoryOverflow
        OpEventGetNumberOfEventMemoryEntries_GetNumberOfEventMemoryEntries_OverflowIndPrimaryMemory_DemClient: start-on-event=GetNumberOfEventMemoryEntries, operation=OverflowIndPrimaryMemory_DemClient.GetNumberOfEventMemoryEntries
        OpEventGetEventUdsStatus_GetEventUdsStatus_GeneralEvtInfo: start-on-event=DemMaster_0InternalBehavior/GetEventUdsStatus, operation=GeneralEvtInfo.GetEventUdsStatus
        OpEventGetEventStatus_GetEventStatus_GeneralEvtInfo: start-on-event=DemMaster_0InternalBehavior/GetEventStatus, operation=GeneralEvtInfo.GetEventStatus
        OpEventGetEventFailed_GetEventFailed_GeneralEvtInfo: start-on-event=DemMaster_0InternalBehavior/GetEventFailed, operation=GeneralEvtInfo.GetEventFailed
        OpEventGetEventTested_GetEventTested_GeneralEvtInfo: start-on-event=DemMaster_0InternalBehavior/GetEventTested, operation=GeneralEvtInfo.GetEventTested
        OpEventGetDTCOfEvent_GetDTCOfEvent_GeneralEvtInfo: start-on-event=DemMaster_0InternalBehavior/GetDTCOfEvent, operation=GeneralEvtInfo.GetDTCOfEvent
        OpEventGetFaultDetectionCounter_GetFaultDetectionCounter_GeneralEvtInfo: start-on-event=DemMaster_0InternalBehavior/GetFaultDetectionCounter, operation=GeneralEvtInfo.GetFaultDetectionCounter
        OpEventGetEventFreezeFrameDataEx_GetEventFreezeFrameDataEx_GeneralEvtInfo: start-on-event=DemMaster_0InternalBehavior/GetEventFreezeFrameDataEx, operation=GeneralEvtInfo.GetEventFreezeFrameDataEx
        OpEventGetEventExtendedDataRecordEx_GetEventExtendedDataRecordEx_GeneralEvtInfo: start-on-event=DemMaster_0InternalBehavior/GetEventExtendedDataRecordEx, operation=GeneralEvtInfo.GetEventExtendedDataRecordEx
        OpEventGetEventEnableCondition_GetEventEnableCondition_GeneralEvtInfo: start-on-event=DemMaster_0InternalBehavior/GetEventEnableCondition, operation=GeneralEvtInfo.GetEventEnableCondition
        OpEventGetDebouncingOfEvent_GetDebouncingOfEvent_GeneralEvtInfo: start-on-event=DemMaster_0InternalBehavior/GetDebouncingOfEvent, operation=GeneralEvtInfo.GetDebouncingOfEvent
        OpEventGetMonitorStatus_GetMonitorStatus_GeneralEvtInfo: start-on-event=DemMaster_0InternalBehavior/GetMonitorStatus, operation=GeneralEvtInfo.GetMonitorStatus
        OpEventGetOperationCycleState_GetOperationCycleState_OpCycle_IgnitionCycle: start-on-event=GetOperationCycleState, operation=OpCycle_IgnitionCycle.GetOperationCycleState
        OpEventSetOperationCycleState_SetOperationCycleState_OpCycle_IgnitionCycle: start-on-event=SetOperationCycleState, operation=OpCycle_IgnitionCycle.SetOperationCycleState
        OpEventSetEnableCondition_SetEnableCondition_EnableCond_EC10: start-on-event=SetEnableCondition, operation=EnableCond_EC10.SetEnableCondition
      port-api-options:
        enable-take-address=true, indirect-api=false, port=DemServices
        {enable-take-address=true, indirect-api=false, port-defined-argument-value{value=0, value-type=uint8}, port=ClearDTC_DemClient}
        {enable-take-address=true, indirect-api=false, port-defined-argument-value{value=7, value-type=uint8}, port=EnableCond_EC7}
        {enable-take-address=true, indirect-api=false, port-defined-argument-value{value=6, value-type=uint8}, port=EnableCond_EC5}
        {enable-take-address=true, indirect-api=false, port-defined-argument-value{value=5, value-type=uint8}, port=EnableCond_EC4}
        {enable-take-address=true, indirect-api=false, port-defined-argument-value{value=4, value-type=uint8}, port=EnableCond_EC2}
        {enable-take-address=true, indirect-api=false, port-defined-argument-value{value=1, value-type=uint8}, port=EnableCond_EC1}
        {enable-take-address=true, indirect-api=false, port-defined-argument-value{value=3, value-type=uint8}, port=EnableCond_EC1_EC8}
        {enable-take-address=true, indirect-api=false, port-defined-argument-value{value=2, value-type=uint8}, port=EnableCond_EC1_EC4_EC8}
        {enable-take-address=true, indirect-api=false, port-arg-values=[{value=0, value-type=uint8}, {value=1, value-type=Dem_DTCOriginType}], port=OverflowIndPrimaryMemory_DemClient}
        enable-take-address=true, indirect-api=false, port=DemMaster_0/GeneralEvtInfo
        {enable-take-address=true, indirect-api=false, port-defined-argument-value{value=0, value-type=uint8}, port=OpCycle_IgnitionCycle}
        enable-take-address=true, indirect-api=false, port=DemMaster_0/CBReadData_Data_DID_0x1004_Battery_Voltage_24
        enable-take-address=true, indirect-api=false, port=DemMaster_0/CBReadData_Data_DID_0x1008_ECU_Life_Time_24
        enable-take-address=true, indirect-api=false, port=DemMaster_0/CBReadData_Data_DID_0x1009_ECU_Time_Since_Ignition_ON
        enable-take-address=true, indirect-api=false, port=DemMaster_0/CBReadData_Data_OccurrenceCounter_Aging_Counter_ID
        enable-take-address=true, indirect-api=false, port=DemMaster_0/CBReadData_Data_OccurrenceCounter_Frequency_Counter_ID
        enable-take-address=true, indirect-api=false, port=DemMaster_0/CBReadData_Data_DID_0x200a_Ignition_ON_Counter_24
        enable-take-address=true, indirect-api=false, port=DemMaster_0/CBReadData_Data_DID_0x1002_Vehicle_Speed_24
        enable-take-address=true, indirect-api=false, port=DemMaster_0/CBReadData_Data_DID_0x2001_Odometer_24
        enable-take-address=true, indirect-api=false, port=DemMaster_0/CBReadData_Data_OccurrenceCounter_Touch_Screen_Y_Coordinate
        enable-take-address=true, indirect-api=false, port=DemMaster_0/CBReadData_Data_OccurrenceCounter_Odometer_Value
        enable-take-address=true, indirect-api=false, port=DemMaster_0/CBReadData_Data_OccurrenceCounter_Camera_Occlusion
        enable-take-address=true, indirect-api=false, port=DemMaster_0/CBReadData_Data_OccurrenceCounter_THA_state
        enable-take-address=true, indirect-api=false, port=DemMaster_0/CBReadData_Data_OccurrenceCounter_Supplier_Internal_Code
        enable-take-address=true, indirect-api=false, port=DemMaster_0/CBReadData_Data_OccurrenceCounter_Current_Gear
        enable-take-address=true, indirect-api=false, port=DemMaster_0/CBReadData_Data_OccurrenceCounter_Vehicle_Speed
        enable-take-address=true, indirect-api=false, port=DemMaster_0/CBReadData_Data_OccurrenceCounter_DisplayStatus
        enable-take-address=true, indirect-api=false, port=DemMaster_0/CBReadData_Data_OccurrenceCounter_TRSC_Stat
        enable-take-address=true, indirect-api=false, port=DemMaster_0/CBReadData_Data_OccurrenceCounter_ECU_Voltage
        enable-take-address=true, indirect-api=false, port=DemMaster_0/CBReadData_Data_OccurrenceCounter_Touch_Screen_X_Coordinate
        enable-take-address=true, indirect-api=false, port=DemMaster_0/CBReadData_Data_OccurrenceCounter_Touch_Screen_Status
        enable-take-address=true, indirect-api=false, port=DemMaster_0/CBReadData_Data_OccurrenceCounter_External_Temperature
        enable-take-address=true, indirect-api=false, port=DemMaster_0/CBReadData_Data_OccurrenceCounter_TireLines
        enable-take-address=true, indirect-api=false, port=DemMaster_0/CBReadData_Data_OccurrenceCounter_Door_Status
        enable-take-address=true, indirect-api=false, port=DemMaster_0/CBReadData_Data_OccurrenceCounter_Radio_Display_Status
        enable-take-address=true, indirect-api=false, port=DemMaster_0/CBReadData_Data_OccurrenceCounter_TRSKM_and_USS_status
        enable-take-address=true, indirect-api=false, port=DemMaster_0/CBReadData_Data_OccurrenceCounter_LiftgateAjar
        enable-take-address=true, indirect-api=false, port=DemMaster_0/CBReadData_Data_OccurrenceCounter_Cycles_to_Switch_off_the_Warning_Indication_ID
        enable-take-address=true, indirect-api=false, port=DemMaster_0/CBReadData_Data_OccurrenceCounter_Steering_Wheel_Angle
        enable-take-address=true, indirect-api=false, port=DemMaster_0/CBReadData_Data_OccurrenceCounter_Reserved
        enable-take-address=true, indirect-api=false, port=DemMaster_0/CBReadData_Data_OccurrenceCounter_Reserved_1
        enable-take-address=true, indirect-api=false, port=DemMaster_0/CBReadData_Data_OccurrenceCounter_Calibration_Aborted_Failed
        enable-take-address=true, indirect-api=false, port=DemMaster_0/CBReadData_Data_OccurrenceCounter_Calibration_Pending
        enable-take-address=true, indirect-api=false, port=DemMaster_0/CBReadData_Data_OccurrenceCounter_Calibration_Running
        enable-take-address=true, indirect-api=false, port=DemMaster_0/CBReadData_Data_OccurrenceCounter_New_Bit_Field
        enable-take-address=true, indirect-api=false, port=DemMaster_0/CBReadData_Data_OccurrenceCounter_Calibration_Not_Started
        enable-take-address=true, indirect-api=false, port=DemMaster_0/CBReadData_Data_OccurrenceCounter_Calibrated_Successfully
        enable-take-address=true, indirect-api=false, port=DemMaster_0/CBReadData_Data_OccurrenceCounter_Reserved_2
        enable-take-address=true, indirect-api=false, port=DemMaster_0/CBReadData_Data_DID_0x1921_CombinedSignal
        {enable-take-address=true, indirect-api=false, port-defined-argument-value{value=8, value-type=uint8}, port=EnableCond_EC9}
        {enable-take-address=true, indirect-api=false, port-defined-argument-value{value=9, value-type=uint8}, port=EnableCond_EC10}
      21 x runnable:
        Dem_MasterMainFunction
          38 x sync call, all with timeout=0:
            OpServerCallDem_MasterMainFunction_ReadData_CBReadData_Data_DID_0x1004_Battery_Voltage_24: operation=CBReadData_Data_DID_0x1004_Battery_Voltage_24.ReadData
            OpServerCallDem_MasterMainFunction_ReadData_CBReadData_Data_DID_0x1008_ECU_Life_Time_24: operation=CBReadData_Data_DID_0x1008_ECU_Life_Time_24.ReadData
            OpServerCallDem_MasterMainFunction_ReadData_CBReadData_Data_DID_0x1009_ECU_Time_Since_Ignition_ON: operation=CBReadData_Data_DID_0x1009_ECU_Time_Since_Ignition_ON.ReadData
            OpServerCallDem_MasterMainFunction_ReadData_CBReadData_Data_OccurrenceCounter_Aging_Counter_ID: operation=CBReadData_Data_OccurrenceCounter_Aging_Counter_ID.ReadData
            OpServerCallDem_MasterMainFunction_ReadData_CBReadData_Data_OccurrenceCounter_Frequency_Counter_ID: operation=CBReadData_Data_OccurrenceCounter_Frequency_Counter_ID.ReadData
            OpServerCallDem_MasterMainFunction_ReadData_CBReadData_Data_DID_0x200a_Ignition_ON_Counter_24: operation=CBReadData_Data_DID_0x200a_Ignition_ON_Counter_24.ReadData
            OpServerCallDem_MasterMainFunction_ReadData_CBReadData_Data_DID_0x1002_Vehicle_Speed_24: operation=CBReadData_Data_DID_0x1002_Vehicle_Speed_24.ReadData
            OpServerCallDem_MasterMainFunction_ReadData_CBReadData_Data_DID_0x2001_Odometer_24: operation=CBReadData_Data_DID_0x2001_Odometer_24.ReadData
            OpServerCallDem_MasterMainFunction_ReadData_CBReadData_Data_OccurrenceCounter_Touch_Screen_Y_Coordinate: operation=CBReadData_Data_OccurrenceCounter_Touch_Screen_Y_Coordinate.ReadData
            OpServerCallDem_MasterMainFunction_ReadData_CBReadData_Data_OccurrenceCounter_Odometer_Value: operation=CBReadData_Data_OccurrenceCounter_Odometer_Value.ReadData
            OpServerCallDem_MasterMainFunction_ReadData_CBReadData_Data_OccurrenceCounter_Camera_Occlusion: operation=CBReadData_Data_OccurrenceCounter_Camera_Occlusion.ReadData
            OpServerCallDem_MasterMainFunction_ReadData_CBReadData_Data_OccurrenceCounter_THA_state: operation=CBReadData_Data_OccurrenceCounter_THA_state.ReadData
            OpServerCallDem_MasterMainFunction_ReadData_CBReadData_Data_OccurrenceCounter_Supplier_Internal_Code: operation=CBReadData_Data_OccurrenceCounter_Supplier_Internal_Code.ReadData
            OpServerCallDem_MasterMainFunction_ReadData_CBReadData_Data_OccurrenceCounter_Current_Gear: operation=CBReadData_Data_OccurrenceCounter_Current_Gear.ReadData
            OpServerCallDem_MasterMainFunction_ReadData_CBReadData_Data_OccurrenceCounter_Vehicle_Speed: operation=CBReadData_Data_OccurrenceCounter_Vehicle_Speed.ReadData
            OpServerCallDem_MasterMainFunction_ReadData_CBReadData_Data_OccurrenceCounter_DisplayStatus: operation=CBReadData_Data_OccurrenceCounter_DisplayStatus.ReadData
            OpServerCallDem_MasterMainFunction_ReadData_CBReadData_Data_OccurrenceCounter_TRSC_Stat: operation=CBReadData_Data_OccurrenceCounter_TRSC_Stat.ReadData
            OpServerCallDem_MasterMainFunction_ReadData_CBReadData_Data_OccurrenceCounter_ECU_Voltage: operation=CBReadData_Data_OccurrenceCounter_ECU_Voltage.ReadData
            OpServerCallDem_MasterMainFunction_ReadData_CBReadData_Data_OccurrenceCounter_Touch_Screen_X_Coordinate: operation=CBReadData_Data_OccurrenceCounter_Touch_Screen_X_Coordinate.ReadData
            OpServerCallDem_MasterMainFunction_ReadData_CBReadData_Data_OccurrenceCounter_Touch_Screen_Status: operation=CBReadData_Data_OccurrenceCounter_Touch_Screen_Status.ReadData
            OpServerCallDem_MasterMainFunction_ReadData_CBReadData_Data_OccurrenceCounter_External_Temperature: operation=CBReadData_Data_OccurrenceCounter_External_Temperature.ReadData
            OpServerCallDem_MasterMainFunction_ReadData_CBReadData_Data_OccurrenceCounter_TireLines: operation=CBReadData_Data_OccurrenceCounter_TireLines.ReadData
            OpServerCallDem_MasterMainFunction_ReadData_CBReadData_Data_OccurrenceCounter_Door_Status: operation=CBReadData_Data_OccurrenceCounter_Door_Status.ReadData
            OpServerCallDem_MasterMainFunction_ReadData_CBReadData_Data_OccurrenceCounter_Radio_Display_Status: operation=CBReadData_Data_OccurrenceCounter_Radio_Display_Status.ReadData
            OpServerCallDem_MasterMainFunction_ReadData_CBReadData_Data_OccurrenceCounter_TRSKM_and_USS_status: operation=CBReadData_Data_OccurrenceCounter_TRSKM_and_USS_status.ReadData
            OpServerCallDem_MasterMainFunction_ReadData_CBReadData_Data_OccurrenceCounter_LiftgateAjar: operation=CBReadData_Data_OccurrenceCounter_LiftgateAjar.ReadData
            OpServerCallDem_MasterMainFunction_ReadData_CBReadData_Data_OccurrenceCounter_Cycles_to_Switch_off_the_Warning_Indication_ID: operation=CBReadData_Data_OccurrenceCounter_Cycles_to_Switch_off_the_Warning_Indication_ID.ReadData
            OpServerCallDem_MasterMainFunction_ReadData_CBReadData_Data_OccurrenceCounter_Steering_Wheel_Angle: operation=CBReadData_Data_OccurrenceCounter_Steering_Wheel_Angle.ReadData
            OpServerCallDem_MasterMainFunction_ReadData_CBReadData_Data_OccurrenceCounter_Reserved: operation=CBReadData_Data_OccurrenceCounter_Reserved.ReadData
            OpServerCallDem_MasterMainFunction_ReadData_CBReadData_Data_OccurrenceCounter_Reserved_1: operation=CBReadData_Data_OccurrenceCounter_Reserved_1.ReadData
            OpServerCallDem_MasterMainFunction_ReadData_CBReadData_Data_OccurrenceCounter_Calibration_Aborted_Failed: operation=CBReadData_Data_OccurrenceCounter_Calibration_Aborted_Failed.ReadData
            OpServerCallDem_MasterMainFunction_ReadData_CBReadData_Data_OccurrenceCounter_Calibration_Pending: operation=CBReadData_Data_OccurrenceCounter_Calibration_Pending.ReadData
            OpServerCallDem_MasterMainFunction_ReadData_CBReadData_Data_OccurrenceCounter_Calibration_Running: operation=CBReadData_Data_OccurrenceCounter_Calibration_Running.ReadData
            OpServerCallDem_MasterMainFunction_ReadData_CBReadData_Data_OccurrenceCounter_New_Bit_Field: operation=CBReadData_Data_OccurrenceCounter_New_Bit_Field.ReadData
            OpServerCallDem_MasterMainFunction_ReadData_CBReadData_Data_OccurrenceCounter_Calibration_Not_Started: operation=CBReadData_Data_OccurrenceCounter_Calibration_Not_Started.ReadData
            OpServerCallDem_MasterMainFunction_ReadData_CBReadData_Data_OccurrenceCounter_Calibrated_Successfully: operation=CBReadData_Data_OccurrenceCounter_Calibrated_Successfully.ReadData
            OpServerCallDem_MasterMainFunction_ReadData_CBReadData_Data_OccurrenceCounter_Reserved_2: operation=CBReadData_Data_OccurrenceCounter_Reserved_2.ReadData
            OpServerCallDem_MasterMainFunction_ReadData_CBReadData_Data_DID_0x1921_CombinedSignal: operation=CBReadData_Data_DID_0x1921_CombinedSignal.ReadData
        PostRunRequested: can-be-invoked-concurrently=true, symbol=Dem_PostRunRequested
        GetDTCStatusAvailabilityMask: can-be-invoked-concurrently=true, symbol=Dem_GetDTCStatusAvailabilityMask
        ClearDTC: can-be-invoked-concurrently=true, symbol=Dem_ClearDTC
        SelectDTC: can-be-invoked-concurrently=true, symbol=Dem_SelectDTC
        SetEnableCondition: can-be-invoked-concurrently=true, symbol=Dem_SetEnableCondition
        GetEventMemoryOverflow: can-be-invoked-concurrently=true, symbol=Dem_GetEventMemoryOverflow
        GetNumberOfEventMemoryEntries: can-be-invoked-concurrently=true, symbol=Dem_GetNumberOfEventMemoryEntries
        GetEventUdsStatus: can-be-invoked-concurrently=true, symbol=Dem_GetEventUdsStatus
        GetEventStatus: can-be-invoked-concurrently=true, symbol=Dem_GetEventUdsStatus
        GetEventFailed: can-be-invoked-concurrently=true, symbol=Dem_GetEventFailed
        GetEventTested: can-be-invoked-concurrently=true, symbol=Dem_GetEventTested
        GetDTCOfEvent: can-be-invoked-concurrently=true, symbol=Dem_GetDTCOfEvent
        GetFaultDetectionCounter: can-be-invoked-concurrently=true, symbol=Dem_GetFaultDetectionCounter
        GetEventFreezeFrameDataEx: can-be-invoked-concurrently=true, symbol=Dem_GetEventFreezeFrameDataEx
        GetEventExtendedDataRecordEx: can-be-invoked-concurrently=true, symbol=Dem_GetEventExtendedDataRecordEx
        GetEventEnableCondition: can-be-invoked-concurrently=true, symbol=Dem_GetEventEnableCondition
        GetDebouncingOfEvent: can-be-invoked-concurrently=true, symbol=Dem_GetDebouncingOfEvent
        GetMonitorStatus: can-be-invoked-concurrently=true, symbol=Dem_GetMonitorStatus
        GetOperationCycleState: can-be-invoked-concurrently=true, symbol=Dem_GetOperationCycleState
        SetOperationCycleState: can-be-invoked-concurrently=true, symbol=Dem_SetOperationCycleState
  swc implementation DemMaster_0Implementation: programming-language=C, behavior=DemMaster_0InternalBehavior
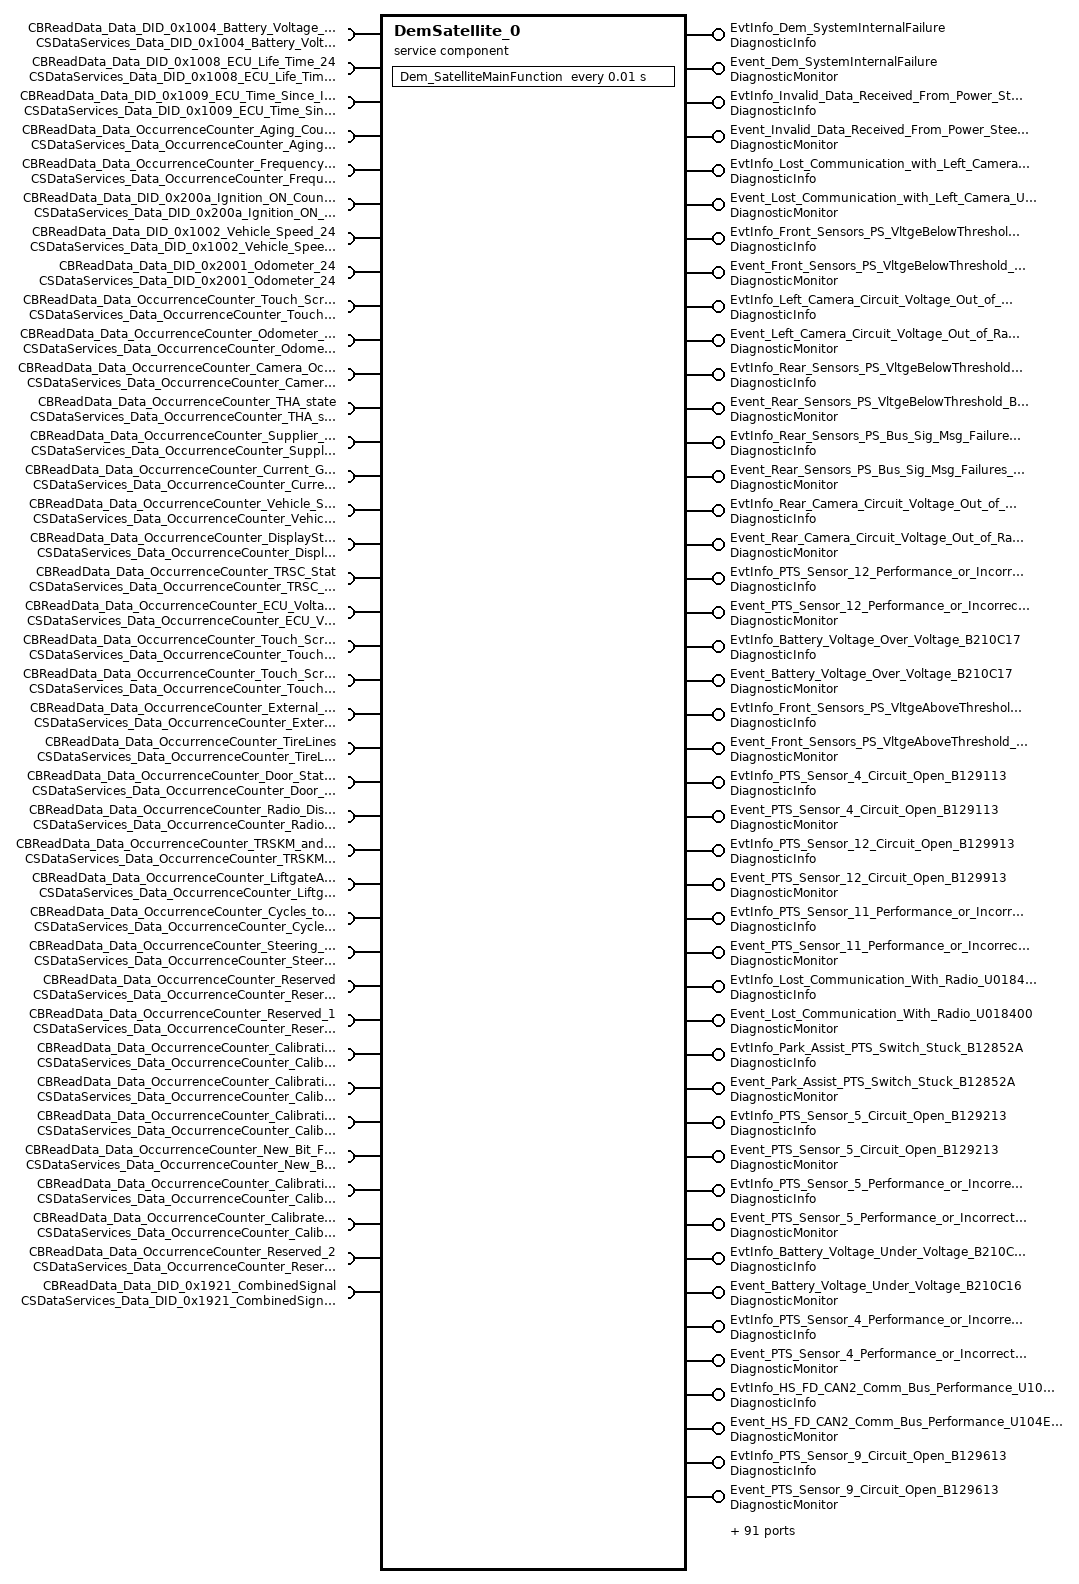
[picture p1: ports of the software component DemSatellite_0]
  service sw component type DemSatellite_0: category=SERVICE_COMPONENT
    135 x provide port:
      EvtInfo_Dem_SystemInternalFailure: provided-interface=DiagnosticInfo
      Event_Dem_SystemInternalFailure: provided-interface=DiagnosticMonitor
      EvtInfo_Invalid_Data_Received_From_Power_Steering_Control_Module_U042000: provided-interface=DiagnosticInfo
      Event_Invalid_Data_Received_From_Power_Steering_Control_Module_U042000: provided-interface=DiagnosticMonitor
      EvtInfo_Lost_Communication_with_Left_Camera_U026600: provided-interface=DiagnosticInfo
      Event_Lost_Communication_with_Left_Camera_U026600: provided-interface=DiagnosticMonitor
      EvtInfo_Front_Sensors_PS_VltgeBelowThreshold_B212A16: provided-interface=DiagnosticInfo
      Event_Front_Sensors_PS_VltgeBelowThreshold_B212A16: provided-interface=DiagnosticMonitor
      EvtInfo_Left_Camera_Circuit_Voltage_Out_of_Range_B23C61C: provided-interface=DiagnosticInfo
      Event_Left_Camera_Circuit_Voltage_Out_of_Range_B23C61C: provided-interface=DiagnosticMonitor
      EvtInfo_Rear_Sensors_PS_VltgeBelowThreshold_B212B16: provided-interface=DiagnosticInfo
      Event_Rear_Sensors_PS_VltgeBelowThreshold_B212B16: provided-interface=DiagnosticMonitor
      EvtInfo_Rear_Sensors_PS_Bus_Sig_Msg_Failures_B212B08: provided-interface=DiagnosticInfo
      Event_Rear_Sensors_PS_Bus_Sig_Msg_Failures_B212B08: provided-interface=DiagnosticMonitor
      EvtInfo_Rear_Camera_Circuit_Voltage_Out_of_Range_B217A1C: provided-interface=DiagnosticInfo
      Event_Rear_Camera_Circuit_Voltage_Out_of_Range_B217A1C: provided-interface=DiagnosticMonitor
      EvtInfo_PTS_Sensor_12_Performance_or_Incorrect_Operation_B129992: provided-interface=DiagnosticInfo
      Event_PTS_Sensor_12_Performance_or_Incorrect_Operation_B129992: provided-interface=DiagnosticMonitor
      EvtInfo_Battery_Voltage_Over_Voltage_B210C17: provided-interface=DiagnosticInfo
      Event_Battery_Voltage_Over_Voltage_B210C17: provided-interface=DiagnosticMonitor
      EvtInfo_Front_Sensors_PS_VltgeAboveThreshold_B212A17: provided-interface=DiagnosticInfo
      Event_Front_Sensors_PS_VltgeAboveThreshold_B212A17: provided-interface=DiagnosticMonitor
      EvtInfo_PTS_Sensor_4_Circuit_Open_B129113: provided-interface=DiagnosticInfo
      Event_PTS_Sensor_4_Circuit_Open_B129113: provided-interface=DiagnosticMonitor
      EvtInfo_PTS_Sensor_12_Circuit_Open_B129913: provided-interface=DiagnosticInfo
      Event_PTS_Sensor_12_Circuit_Open_B129913: provided-interface=DiagnosticMonitor
      EvtInfo_PTS_Sensor_11_Performance_or_Incorrect_Operation_B129892: provided-interface=DiagnosticInfo
      Event_PTS_Sensor_11_Performance_or_Incorrect_Operation_B129892: provided-interface=DiagnosticMonitor
      EvtInfo_Lost_Communication_With_Radio_U018400: provided-interface=DiagnosticInfo
      Event_Lost_Communication_With_Radio_U018400: provided-interface=DiagnosticMonitor
      EvtInfo_Park_Assist_PTS_Switch_Stuck_B12852A: provided-interface=DiagnosticInfo
      Event_Park_Assist_PTS_Switch_Stuck_B12852A: provided-interface=DiagnosticMonitor
      EvtInfo_PTS_Sensor_5_Circuit_Open_B129213: provided-interface=DiagnosticInfo
      Event_PTS_Sensor_5_Circuit_Open_B129213: provided-interface=DiagnosticMonitor
      EvtInfo_PTS_Sensor_5_Performance_or_Incorrect_Operation_B129292: provided-interface=DiagnosticInfo
      Event_PTS_Sensor_5_Performance_or_Incorrect_Operation_B129292: provided-interface=DiagnosticMonitor
      EvtInfo_Battery_Voltage_Under_Voltage_B210C16: provided-interface=DiagnosticInfo
      Event_Battery_Voltage_Under_Voltage_B210C16: provided-interface=DiagnosticMonitor
      EvtInfo_PTS_Sensor_4_Performance_or_Incorrect_Operation_B129192: provided-interface=DiagnosticInfo
      Event_PTS_Sensor_4_Performance_or_Incorrect_Operation_B129192: provided-interface=DiagnosticMonitor
      EvtInfo_HS_FD_CAN2_Comm_Bus_Performance_U104E00: provided-interface=DiagnosticInfo
      Event_HS_FD_CAN2_Comm_Bus_Performance_U104E00: provided-interface=DiagnosticMonitor
      EvtInfo_PTS_Sensor_9_Circuit_Open_B129613: provided-interface=DiagnosticInfo
      Event_PTS_Sensor_9_Circuit_Open_B129613: provided-interface=DiagnosticMonitor
      EvtInfo_Loss_of_Comm_With_Engine_Control_Module_U010000: provided-interface=DiagnosticInfo
      Event_Loss_of_Comm_With_Engine_Control_Module_U010000: provided-interface=DiagnosticMonitor
      EvtInfo_Lost_Communication_with_Right_Camera_U026700: provided-interface=DiagnosticInfo
      Event_Lost_Communication_with_Right_Camera_U026700: provided-interface=DiagnosticMonitor
      EvtInfo_PTS_Sensor_1_Performance_or_Incorrect_Operation_B128E92: provided-interface=DiagnosticInfo
      Event_PTS_Sensor_1_Performance_or_Incorrect_Operation_B128E92: provided-interface=DiagnosticMonitor
      EvtInfo_Rear_Camera_Performance_or_Incorrect_Operation_B217A92: provided-interface=DiagnosticInfo
      Event_Rear_Camera_Performance_or_Incorrect_Operation_B217A92: provided-interface=DiagnosticMonitor
      EvtInfo_PTS_Sensor_2_Performance_or_Incorrect_Operation_B128F92: provided-interface=DiagnosticInfo
      Event_PTS_Sensor_2_Performance_or_Incorrect_Operation_B128F92: provided-interface=DiagnosticMonitor
      EvtInfo_Right_Camera_Circuit_Voltage_Out_of_Range_B23C71C: provided-interface=DiagnosticInfo
      Event_Right_Camera_Circuit_Voltage_Out_of_Range_B23C71C: provided-interface=DiagnosticMonitor
      EvtInfo_PTS_Sensor_8_Circuit_Open_B129513: provided-interface=DiagnosticInfo
      Event_PTS_Sensor_8_Circuit_Open_B129513: provided-interface=DiagnosticMonitor
      EvtInfo_Implausible_Data_Received_from_Radio_U048500: provided-interface=DiagnosticInfo
      Event_Implausible_Data_Received_from_Radio_U048500: provided-interface=DiagnosticMonitor
      EvtInfo_Implausible_Data_received_from_TRSKM_module_U14A000: provided-interface=DiagnosticInfo
      Event_Implausible_Data_received_from_TRSKM_module_U14A000: provided-interface=DiagnosticMonitor
      EvtInfo_Front_Camera_Performance_or_Incorrect_Operation_B23C592: provided-interface=DiagnosticInfo
      Event_Front_Camera_Performance_or_Incorrect_Operation_B23C592: provided-interface=DiagnosticMonitor
      EvtInfo_Loss_Communication_with_TRS_Knob_Module_U12B900: provided-interface=DiagnosticInfo
      Event_Loss_Communication_with_TRS_Knob_Module_U12B900: provided-interface=DiagnosticMonitor
      EvtInfo_PTS_Sensor_7_Circuit_Open_B129413: provided-interface=DiagnosticInfo
      Event_PTS_Sensor_7_Circuit_Open_B129413: provided-interface=DiagnosticMonitor
      EvtInfo_Front_Sensors_PS_Bus_Sig_Msg_Failures_B212A08: provided-interface=DiagnosticInfo
      Event_Front_Sensors_PS_Bus_Sig_Msg_Failures_B212A08: provided-interface=DiagnosticMonitor
      EvtInfo_Lost_Communication_With_PSC_Module_A_U013100: provided-interface=DiagnosticInfo
      Event_Lost_Communication_With_PSC_Module_A_U013100: provided-interface=DiagnosticMonitor
      EvtInfo_Lost_Communication_with_Front_Camera_U026500: provided-interface=DiagnosticInfo
      Event_Lost_Communication_with_Front_Camera_U026500: provided-interface=DiagnosticMonitor
      EvtInfo_PTS_Sensor_3_Performance_or_Incorrect_Operation_B129092: provided-interface=DiagnosticInfo
      Event_PTS_Sensor_3_Performance_or_Incorrect_Operation_B129092: provided-interface=DiagnosticMonitor
      EvtInfo_PTS_Sensor_8_Performance_or_Incorrect_Operation_B129592: provided-interface=DiagnosticInfo
      Event_PTS_Sensor_8_Performance_or_Incorrect_Operation_B129592: provided-interface=DiagnosticMonitor
      EvtInfo_PPP_Assist_Switch_Stuck_B12B22A: provided-interface=DiagnosticInfo
      Event_PPP_Assist_Switch_Stuck_B12B22A: provided-interface=DiagnosticMonitor
      EvtInfo_Implausible_data_received_from_ECM_U040100: provided-interface=DiagnosticInfo
      Event_Implausible_data_received_from_ECM_U040100: provided-interface=DiagnosticMonitor
      EvtInfo_PTS_Sensor_10_Circuit_Open_B129713: provided-interface=DiagnosticInfo
      Event_PTS_Sensor_10_Circuit_Open_B129713: provided-interface=DiagnosticMonitor
      EvtInfo_Lost_Communication_With_BSC_module_1_U012900: provided-interface=DiagnosticInfo
      Event_Lost_Communication_With_BSC_module_1_U012900: provided-interface=DiagnosticMonitor
      EvtInfo_PTS_Sensor_7_Performance_or_Incorrect_Operation_B129492: provided-interface=DiagnosticInfo
      Event_PTS_Sensor_7_Performance_or_Incorrect_Operation_B129492: provided-interface=DiagnosticMonitor
      EvtInfo_Left_Camera_Performance_or_Incorrect_Operation_B23C692: provided-interface=DiagnosticInfo
      Event_Left_Camera_Performance_or_Incorrect_Operation_B23C692: provided-interface=DiagnosticMonitor
      EvtInfo_Vehicle_Configuration_Mismatch_B223B00: provided-interface=DiagnosticInfo
      Event_Vehicle_Configuration_Mismatch_B223B00: provided-interface=DiagnosticMonitor
      EvtInfo_PTS_Sensor_6_Circuit_Open_B129313: provided-interface=DiagnosticInfo
      Event_PTS_Sensor_6_Circuit_Open_B129313: provided-interface=DiagnosticMonitor
      EvtInfo_Front_Camera_Circuit_Voltage_Out_of_Range_B23C51C: provided-interface=DiagnosticInfo
      Event_Front_Camera_Circuit_Voltage_Out_of_Range_B23C51C: provided-interface=DiagnosticMonitor
      EvtInfo_Implausible_Data_From_BSC_Module_1_U041800: provided-interface=DiagnosticInfo
      Event_Implausible_Data_From_BSC_Module_1_U041800: provided-interface=DiagnosticMonitor
      EvtInfo_PTS_Sensor_10_Performance_or_Incorrect_Operation_B129792: provided-interface=DiagnosticInfo
      Event_PTS_Sensor_10_Performance_or_Incorrect_Operation_B129792: provided-interface=DiagnosticMonitor
      EvtInfo_PTS_Sensor_11_Circuit_Open_B129813: provided-interface=DiagnosticInfo
      Event_PTS_Sensor_11_Circuit_Open_B129813: provided-interface=DiagnosticMonitor
      EvtInfo_ECU_Internal_Performance_B22A900: provided-interface=DiagnosticInfo
      Event_ECU_Internal_Performance_B22A900: provided-interface=DiagnosticMonitor
      EvtInfo_PTS_Sensor_9_Performance_or_Incorrect_Operation_B129692: provided-interface=DiagnosticInfo
      Event_PTS_Sensor_9_Performance_or_Incorrect_Operation_B129692: provided-interface=DiagnosticMonitor
      EvtInfo_Calibration_Not_Learned_Lost_Calibration_B228600: provided-interface=DiagnosticInfo
      Event_Calibration_Not_Learned_Lost_Calibration_B228600: provided-interface=DiagnosticMonitor
      EvtInfo_Lost_Communication_with_ORC_U015100: provided-interface=DiagnosticInfo
      Event_Lost_Communication_with_ORC_U015100: provided-interface=DiagnosticMonitor
      EvtInfo_PTS_Sensor_1_Circuit_Open_B128E13: provided-interface=DiagnosticInfo
      Event_PTS_Sensor_1_Circuit_Open_B128E13: provided-interface=DiagnosticMonitor
      EvtInfo_Lost_Communication_with_Rear_Camera_U026400: provided-interface=DiagnosticInfo
      Event_Lost_Communication_with_Rear_Camera_U026400: provided-interface=DiagnosticMonitor
      EvtInfo_HS_FD_CANR_Comm_Bus_Performance_U100B00: provided-interface=DiagnosticInfo
      Event_HS_FD_CANR_Comm_Bus_Performance_U100B00: provided-interface=DiagnosticMonitor
      EvtInfo_Implausible_Data_Received_From_Body_Control_Module_U042200: provided-interface=DiagnosticInfo
      Event_Implausible_Data_Received_From_Body_Control_Module_U042200: provided-interface=DiagnosticMonitor
      EvtInfo_Lost_Communication_With_BCM_U014000: provided-interface=DiagnosticInfo
      Event_Lost_Communication_With_BCM_U014000: provided-interface=DiagnosticMonitor
      EvtInfo_PTS_Sensor_2_Circuit_Open_B128F13: provided-interface=DiagnosticInfo
      Event_PTS_Sensor_2_Circuit_Open_B128F13: provided-interface=DiagnosticMonitor
      EvtInfo_PTS_Sensor_3_Circuit_Open_B129013: provided-interface=DiagnosticInfo
      Event_PTS_Sensor_3_Circuit_Open_B129013: provided-interface=DiagnosticMonitor
      EvtInfo_ECU_In_Plant_Mode_C221200: provided-interface=DiagnosticInfo
      Event_ECU_In_Plant_Mode_C221200: provided-interface=DiagnosticMonitor
      EvtInfo_Implausible_Data_from_ORC_module_U045500: provided-interface=DiagnosticInfo
      Event_Implausible_Data_from_ORC_module_U045500: provided-interface=DiagnosticMonitor
      EvtInfo_Right_Camera_Performance_or_Incorrect_Operation_B23C792: provided-interface=DiagnosticInfo
      Event_Right_Camera_Performance_or_Incorrect_Operation_B23C792: provided-interface=DiagnosticMonitor
      EvtInfo_Rear_Sensors_PS_VltgeAboveThreshold_B212B17: provided-interface=DiagnosticInfo
      Event_Rear_Sensors_PS_VltgeAboveThreshold_B212B17: provided-interface=DiagnosticMonitor
      EvtInfo_PTS_Sensor_6_Performance_or_Incorrect_Operation_B129392: provided-interface=DiagnosticInfo
      Event_PTS_Sensor_6_Performance_or_Incorrect_Operation_B129392: provided-interface=DiagnosticMonitor
      GeneralEvtInfo: provided-interface=GeneralDiagnosticInfo
    38 x require port:
      CBReadData_Data_DID_0x1004_Battery_Voltage_24: required-interface=CSDataServices_Data_DID_0x1004_Battery_Voltage_24
      CBReadData_Data_DID_0x1008_ECU_Life_Time_24: required-interface=CSDataServices_Data_DID_0x1008_ECU_Life_Time_24
      CBReadData_Data_DID_0x1009_ECU_Time_Since_Ignition_ON: required-interface=CSDataServices_Data_DID_0x1009_ECU_Time_Since_Ignition_ON
      CBReadData_Data_OccurrenceCounter_Aging_Counter_ID: required-interface=CSDataServices_Data_OccurrenceCounter_Aging_Counter_ID
      CBReadData_Data_OccurrenceCounter_Frequency_Counter_ID: required-interface=CSDataServices_Data_OccurrenceCounter_Frequency_Counter_ID
      CBReadData_Data_DID_0x200a_Ignition_ON_Counter_24: required-interface=CSDataServices_Data_DID_0x200a_Ignition_ON_Counter_24
      CBReadData_Data_DID_0x1002_Vehicle_Speed_24: required-interface=CSDataServices_Data_DID_0x1002_Vehicle_Speed_24
      CBReadData_Data_DID_0x2001_Odometer_24: required-interface=CSDataServices_Data_DID_0x2001_Odometer_24
      CBReadData_Data_OccurrenceCounter_Touch_Screen_Y_Coordinate: required-interface=CSDataServices_Data_OccurrenceCounter_Touch_Screen_Y_Coordinate
      CBReadData_Data_OccurrenceCounter_Odometer_Value: required-interface=CSDataServices_Data_OccurrenceCounter_Odometer_Value
      CBReadData_Data_OccurrenceCounter_Camera_Occlusion: required-interface=CSDataServices_Data_OccurrenceCounter_Camera_Occlusion
      CBReadData_Data_OccurrenceCounter_THA_state: required-interface=CSDataServices_Data_OccurrenceCounter_THA_state
      CBReadData_Data_OccurrenceCounter_Supplier_Internal_Code: required-interface=CSDataServices_Data_OccurrenceCounter_Supplier_Internal_Code
      CBReadData_Data_OccurrenceCounter_Current_Gear: required-interface=CSDataServices_Data_OccurrenceCounter_Current_Gear
      CBReadData_Data_OccurrenceCounter_Vehicle_Speed: required-interface=CSDataServices_Data_OccurrenceCounter_Vehicle_Speed
      CBReadData_Data_OccurrenceCounter_DisplayStatus: required-interface=CSDataServices_Data_OccurrenceCounter_DisplayStatus
      CBReadData_Data_OccurrenceCounter_TRSC_Stat: required-interface=CSDataServices_Data_OccurrenceCounter_TRSC_Stat
      CBReadData_Data_OccurrenceCounter_ECU_Voltage: required-interface=CSDataServices_Data_OccurrenceCounter_ECU_Voltage
      CBReadData_Data_OccurrenceCounter_Touch_Screen_X_Coordinate: required-interface=CSDataServices_Data_OccurrenceCounter_Touch_Screen_X_Coordinate
      CBReadData_Data_OccurrenceCounter_Touch_Screen_Status: required-interface=CSDataServices_Data_OccurrenceCounter_Touch_Screen_Status
      CBReadData_Data_OccurrenceCounter_External_Temperature: required-interface=CSDataServices_Data_OccurrenceCounter_External_Temperature
      CBReadData_Data_OccurrenceCounter_TireLines: required-interface=CSDataServices_Data_OccurrenceCounter_TireLines
      CBReadData_Data_OccurrenceCounter_Door_Status: required-interface=CSDataServices_Data_OccurrenceCounter_Door_Status
      CBReadData_Data_OccurrenceCounter_Radio_Display_Status: required-interface=CSDataServices_Data_OccurrenceCounter_Radio_Display_Status
      CBReadData_Data_OccurrenceCounter_TRSKM_and_USS_status: required-interface=CSDataServices_Data_OccurrenceCounter_TRSKM_and_USS_status
      CBReadData_Data_OccurrenceCounter_LiftgateAjar: required-interface=CSDataServices_Data_OccurrenceCounter_LiftgateAjar
      CBReadData_Data_OccurrenceCounter_Cycles_to_Switch_off_the_Warning_Indication_ID: required-interface=CSDataServices_Data_OccurrenceCounter_Cycles_to_Switch_off_the_Warning_Indication_ID
      CBReadData_Data_OccurrenceCounter_Steering_Wheel_Angle: required-interface=CSDataServices_Data_OccurrenceCounter_Steering_Wheel_Angle
      CBReadData_Data_OccurrenceCounter_Reserved: required-interface=CSDataServices_Data_OccurrenceCounter_Reserved
      CBReadData_Data_OccurrenceCounter_Reserved_1: required-interface=CSDataServices_Data_OccurrenceCounter_Reserved_1
      CBReadData_Data_OccurrenceCounter_Calibration_Aborted_Failed: required-interface=CSDataServices_Data_OccurrenceCounter_Calibration_Aborted_Failed
      CBReadData_Data_OccurrenceCounter_Calibration_Pending: required-interface=CSDataServices_Data_OccurrenceCounter_Calibration_Pending
      CBReadData_Data_OccurrenceCounter_Calibration_Running: required-interface=CSDataServices_Data_OccurrenceCounter_Calibration_Running
      CBReadData_Data_OccurrenceCounter_New_Bit_Field: required-interface=CSDataServices_Data_OccurrenceCounter_New_Bit_Field
      CBReadData_Data_OccurrenceCounter_Calibration_Not_Started: required-interface=CSDataServices_Data_OccurrenceCounter_Calibration_Not_Started
      CBReadData_Data_OccurrenceCounter_Calibrated_Successfully: required-interface=CSDataServices_Data_OccurrenceCounter_Calibrated_Successfully
      CBReadData_Data_OccurrenceCounter_Reserved_2: required-interface=CSDataServices_Data_OccurrenceCounter_Reserved_2
      CBReadData_Data_DID_0x1921_CombinedSignal: required-interface=CSDataServices_Data_DID_0x1921_CombinedSignal
    behavior DemSatellite_0InternalBehavior: handle-termination-and-restart=NO-SUPPORT, included-data-type-set=data-type=[Dem_EventIdType, Dem_RatioIdType, Dem_EventStatusType, Dem_UdsStatusByteType, Dem_DTCFormatType, Dem_InitMonitorReasonType, Dem_OperationCycleStateType, Dem_DTCStatusMaskType, Dem_IndicatorStatusType, Dem_MaxDataValueType, Dem_DTCKindType, Dem_DTCGroupType, Dem_IumprDenomCondIdType, Dem_IumprDenomCondStatusType, Dem_DebounceResetStatusType, Dem_DebouncingStateType, Dem_IumprReadinessGroupType, Dem_DTRControlType, Dem_DTCSeverityType, Dem_MonitorStatusType]
      timing event Timer_Dem_SatelliteMainFunction: start-on-event=Dem_SatelliteMainFunction, period=0.01
      1485 x operation invoked event:
        OpEventGetEventUdsStatus_GetEventUdsStatus_EvtInfo_Dem_SystemInternalFailure: start-on-event=DemSatellite_0InternalBehavior/GetEventUdsStatus, operation=EvtInfo_Dem_SystemInternalFailure.GetEventUdsStatus
        OpEventGetEventUdsStatus_GetEventUdsStatus_Event_Dem_SystemInternalFailure: start-on-event=DemSatellite_0InternalBehavior/GetEventUdsStatus, operation=Event_Dem_SystemInternalFailure.GetEventUdsStatus
        OpEventGetEventUdsStatus_GetEventUdsStatus_EvtInfo_Invalid_Data_Received_From_Power_Steering_Control_Module_U042000: start-on-event=DemSatellite_0InternalBehavior/GetEventUdsStatus, operation=EvtInfo_Invalid_Data_Received_From_Power_Steering_Control_Module_U042000.GetEventUdsStatus
        OpEventGetEventUdsStatus_GetEventUdsStatus_Event_Invalid_Data_Received_From_Power_Steering_Control_Module_U042000: start-on-event=DemSatellite_0InternalBehavior/GetEventUdsStatus, operation=Event_Invalid_Data_Received_From_Power_Steering_Control_Module_U042000.GetEventUdsStatus
        OpEventGetEventUdsStatus_GetEventUdsStatus_EvtInfo_Lost_Communication_with_Left_Camera_U026600: start-on-event=DemSatellite_0InternalBehavior/GetEventUdsStatus, operation=EvtInfo_Lost_Communication_with_Left_Camera_U026600.GetEventUdsStatus
        OpEventGetEventUdsStatus_GetEventUdsStatus_Event_Lost_Communication_with_Left_Camera_U026600: start-on-event=DemSatellite_0InternalBehavior/GetEventUdsStatus, operation=Event_Lost_Communication_with_Left_Camera_U026600.GetEventUdsStatus
        OpEventGetEventUdsStatus_GetEventUdsStatus_EvtInfo_Front_Sensors_PS_VltgeBelowThreshold_B212A16: start-on-event=DemSatellite_0InternalBehavior/GetEventUdsStatus, operation=EvtInfo_Front_Sensors_PS_VltgeBelowThreshold_B212A16.GetEventUdsStatus
        OpEventGetEventUdsStatus_GetEventUdsStatus_Event_Front_Sensors_PS_VltgeBelowThreshold_B212A16: start-on-event=DemSatellite_0InternalBehavior/GetEventUdsStatus, operation=Event_Front_Sensors_PS_VltgeBelowThreshold_B212A16.GetEventUdsStatus
        OpEventGetEventUdsStatus_GetEventUdsStatus_EvtInfo_Left_Camera_Circuit_Voltage_Out_of_Range_B23C61C: start-on-event=DemSatellite_0InternalBehavior/GetEventUdsStatus, operation=EvtInfo_Left_Camera_Circuit_Voltage_Out_of_Range_B23C61C.GetEventUdsStatus
        OpEventGetEventUdsStatus_GetEventUdsStatus_Event_Left_Camera_Circuit_Voltage_Out_of_Range_B23C61C: start-on-event=DemSatellite_0InternalBehavior/GetEventUdsStatus, operation=Event_Left_Camera_Circuit_Voltage_Out_of_Range_B23C61C.GetEventUdsStatus
        OpEventGetEventUdsStatus_GetEventUdsStatus_EvtInfo_Rear_Sensors_PS_VltgeBelowThreshold_B212B16: start-on-event=DemSatellite_0InternalBehavior/GetEventUdsStatus, operation=EvtInfo_Rear_Sensors_PS_VltgeBelowThreshold_B212B16.GetEventUdsStatus
        OpEventGetEventUdsStatus_GetEventUdsStatus_Event_Rear_Sensors_PS_VltgeBelowThreshold_B212B16: start-on-event=DemSatellite_0InternalBehavior/GetEventUdsStatus, operation=Event_Rear_Sensors_PS_VltgeBelowThreshold_B212B16.GetEventUdsStatus
        OpEventGetEventUdsStatus_GetEventUdsStatus_EvtInfo_Rear_Sensors_PS_Bus_Sig_Msg_Failures_B212B08: start-on-event=DemSatellite_0InternalBehavior/GetEventUdsStatus, operation=EvtInfo_Rear_Sensors_PS_Bus_Sig_Msg_Failures_B212B08.GetEventUdsStatus
        OpEventGetEventUdsStatus_GetEventUdsStatus_Event_Rear_Sensors_PS_Bus_Sig_Msg_Failures_B212B08: start-on-event=DemSatellite_0InternalBehavior/GetEventUdsStatus, operation=Event_Rear_Sensors_PS_Bus_Sig_Msg_Failures_B212B08.GetEventUdsStatus
        OpEventGetEventUdsStatus_GetEventUdsStatus_EvtInfo_Rear_Camera_Circuit_Voltage_Out_of_Range_B217A1C: start-on-event=DemSatellite_0InternalBehavior/GetEventUdsStatus, operation=EvtInfo_Rear_Camera_Circuit_Voltage_Out_of_Range_B217A1C.GetEventUdsStatus
        OpEventGetEventUdsStatus_GetEventUdsStatus_Event_Rear_Camera_Circuit_Voltage_Out_of_Range_B217A1C: start-on-event=DemSatellite_0InternalBehavior/GetEventUdsStatus, operation=Event_Rear_Camera_Circuit_Voltage_Out_of_Range_B217A1C.GetEventUdsStatus
        OpEventGetEventUdsStatus_GetEventUdsStatus_EvtInfo_PTS_Sensor_12_Performance_or_Incorrect_Operation_B129992: start-on-event=DemSatellite_0InternalBehavior/GetEventUdsStatus, operation=EvtInfo_PTS_Sensor_12_Performance_or_Incorrect_Operation_B129992.GetEventUdsStatus
        OpEventGetEventUdsStatus_GetEventUdsStatus_Event_PTS_Sensor_12_Performance_or_Incorrect_Operation_B129992: start-on-event=DemSatellite_0InternalBehavior/GetEventUdsStatus, operation=Event_PTS_Sensor_12_Performance_or_Incorrect_Operation_B129992.GetEventUdsStatus
        OpEventGetEventUdsStatus_GetEventUdsStatus_EvtInfo_Battery_Voltage_Over_Voltage_B210C17: start-on-event=DemSatellite_0InternalBehavior/GetEventUdsStatus, operation=EvtInfo_Battery_Voltage_Over_Voltage_B210C17.GetEventUdsStatus
        OpEventGetEventUdsStatus_GetEventUdsStatus_Event_Battery_Voltage_Over_Voltage_B210C17: start-on-event=DemSatellite_0InternalBehavior/GetEventUdsStatus, operation=Event_Battery_Voltage_Over_Voltage_B210C17.GetEventUdsStatus
        OpEventGetEventUdsStatus_GetEventUdsStatus_EvtInfo_Front_Sensors_PS_VltgeAboveThreshold_B212A17: start-on-event=DemSatellite_0InternalBehavior/GetEventUdsStatus, operation=EvtInfo_Front_Sensors_PS_VltgeAboveThreshold_B212A17.GetEventUdsStatus
        OpEventGetEventUdsStatus_GetEventUdsStatus_Event_Front_Sensors_PS_VltgeAboveThreshold_B212A17: start-on-event=DemSatellite_0InternalBehavior/GetEventUdsStatus, operation=Event_Front_Sensors_PS_VltgeAboveThreshold_B212A17.GetEventUdsStatus
        OpEventGetEventUdsStatus_GetEventUdsStatus_EvtInfo_PTS_Sensor_4_Circuit_Open_B129113: start-on-event=DemSatellite_0InternalBehavior/GetEventUdsStatus, operation=EvtInfo_PTS_Sensor_4_Circuit_Open_B129113.GetEventUdsStatus
        OpEventGetEventUdsStatus_GetEventUdsStatus_Event_PTS_Sensor_4_Circuit_Open_B129113: start-on-event=DemSatellite_0InternalBehavior/GetEventUdsStatus, operation=Event_PTS_Sensor_4_Circuit_Open_B129113.GetEventUdsStatus
        OpEventGetEventUdsStatus_GetEventUdsStatus_EvtInfo_PTS_Sensor_12_Circuit_Open_B129913: start-on-event=DemSatellite_0InternalBehavior/GetEventUdsStatus, operation=EvtInfo_PTS_Sensor_12_Circuit_Open_B129913.GetEventUdsStatus
        OpEventGetEventUdsStatus_GetEventUdsStatus_Event_PTS_Sensor_12_Circuit_Open_B129913: start-on-event=DemSatellite_0InternalBehavior/GetEventUdsStatus, operation=Event_PTS_Sensor_12_Circuit_Open_B129913.GetEventUdsStatus
        OpEventGetEventUdsStatus_GetEventUdsStatus_EvtInfo_PTS_Sensor_11_Performance_or_Incorrect_Operation_B129892: start-on-event=DemSatellite_0InternalBehavior/GetEventUdsStatus, operation=EvtInfo_PTS_Sensor_11_Performance_or_Incorrect_Operation_B129892.GetEventUdsStatus
        OpEventGetEventUdsStatus_GetEventUdsStatus_Event_PTS_Sensor_11_Performance_or_Incorrect_Operation_B129892: start-on-event=DemSatellite_0InternalBehavior/GetEventUdsStatus, operation=Event_PTS_Sensor_11_Performance_or_Incorrect_Operation_B129892.GetEventUdsStatus
        OpEventGetEventUdsStatus_GetEventUdsStatus_EvtInfo_Lost_Communication_With_Radio_U018400: start-on-event=DemSatellite_0InternalBehavior/GetEventUdsStatus, operation=EvtInfo_Lost_Communication_With_Radio_U018400.GetEventUdsStatus
        OpEventGetEventUdsStatus_GetEventUdsStatus_Event_Lost_Communication_With_Radio_U018400: start-on-event=DemSatellite_0InternalBehavior/GetEventUdsStatus, operation=Event_Lost_Communication_With_Radio_U018400.GetEventUdsStatus
        OpEventGetEventUdsStatus_GetEventUdsStatus_EvtInfo_Park_Assist_PTS_Switch_Stuck_B12852A: start-on-event=DemSatellite_0InternalBehavior/GetEventUdsStatus, operation=EvtInfo_Park_Assist_PTS_Switch_Stuck_B12852A.GetEventUdsStatus
        OpEventGetEventUdsStatus_GetEventUdsStatus_Event_Park_Assist_PTS_Switch_Stuck_B12852A: start-on-event=DemSatellite_0InternalBehavior/GetEventUdsStatus, operation=Event_Park_Assist_PTS_Switch_Stuck_B12852A.GetEventUdsStatus
        OpEventGetEventUdsStatus_GetEventUdsStatus_EvtInfo_PTS_Sensor_5_Circuit_Open_B129213: start-on-event=DemSatellite_0InternalBehavior/GetEventUdsStatus, operation=EvtInfo_PTS_Sensor_5_Circuit_Open_B129213.GetEventUdsStatus
        OpEventGetEventUdsStatus_GetEventUdsStatus_Event_PTS_Sensor_5_Circuit_Open_B129213: start-on-event=DemSatellite_0InternalBehavior/GetEventUdsStatus, operation=Event_PTS_Sensor_5_Circuit_Open_B129213.GetEventUdsStatus
        OpEventGetEventUdsStatus_GetEventUdsStatus_EvtInfo_PTS_Sensor_5_Performance_or_Incorrect_Operation_B129292: start-on-event=DemSatellite_0InternalBehavior/GetEventUdsStatus, operation=EvtInfo_PTS_Sensor_5_Performance_or_Incorrect_Operation_B129292.GetEventUdsStatus
        OpEventGetEventUdsStatus_GetEventUdsStatus_Event_PTS_Sensor_5_Performance_or_Incorrect_Operation_B129292: start-on-event=DemSatellite_0InternalBehavior/GetEventUdsStatus, operation=Event_PTS_Sensor_5_Performance_or_Incorrect_Operation_B129292.GetEventUdsStatus
        OpEventGetEventUdsStatus_GetEventUdsStatus_EvtInfo_Battery_Voltage_Under_Voltage_B210C16: start-on-event=DemSatellite_0InternalBehavior/GetEventUdsStatus, operation=EvtInfo_Battery_Voltage_Under_Voltage_B210C16.GetEventUdsStatus
        OpEventGetEventUdsStatus_GetEventUdsStatus_Event_Battery_Voltage_Under_Voltage_B210C16: start-on-event=DemSatellite_0InternalBehavior/GetEventUdsStatus, operation=Event_Battery_Voltage_Under_Voltage_B210C16.GetEventUdsStatus
        OpEventGetEventUdsStatus_GetEventUdsStatus_EvtInfo_PTS_Sensor_4_Performance_or_Incorrect_Operation_B129192: start-on-event=DemSatellite_0InternalBehavior/GetEventUdsStatus, operation=EvtInfo_PTS_Sensor_4_Performance_or_Incorrect_Operation_B129192.GetEventUdsStatus
        OpEventGetEventUdsStatus_GetEventUdsStatus_Event_PTS_Sensor_4_Performance_or_Incorrect_Operation_B129192: start-on-event=DemSatellite_0InternalBehavior/GetEventUdsStatus, operation=Event_PTS_Sensor_4_Performance_or_Incorrect_Operation_B129192.GetEventUdsStatus
        OpEventGetEventUdsStatus_GetEventUdsStatus_EvtInfo_HS_FD_CAN2_Comm_Bus_Performance_U104E00: start-on-event=DemSatellite_0InternalBehavior/GetEventUdsStatus, operation=EvtInfo_HS_FD_CAN2_Comm_Bus_Performance_U104E00.GetEventUdsStatus
        OpEventGetEventUdsStatus_GetEventUdsStatus_Event_HS_FD_CAN2_Comm_Bus_Performance_U104E00: start-on-event=DemSatellite_0InternalBehavior/GetEventUdsStatus, operation=Event_HS_FD_CAN2_Comm_Bus_Performance_U104E00.GetEventUdsStatus
        OpEventGetEventUdsStatus_GetEventUdsStatus_EvtInfo_PTS_Sensor_9_Circuit_Open_B129613: start-on-event=DemSatellite_0InternalBehavior/GetEventUdsStatus, operation=EvtInfo_PTS_Sensor_9_Circuit_Open_B129613.GetEventUdsStatus
        OpEventGetEventUdsStatus_GetEventUdsStatus_Event_PTS_Sensor_9_Circuit_Open_B129613: start-on-event=DemSatellite_0InternalBehavior/GetEventUdsStatus, operation=Event_PTS_Sensor_9_Circuit_Open_B129613.GetEventUdsStatus
        OpEventGetEventUdsStatus_GetEventUdsStatus_EvtInfo_Loss_of_Comm_With_Engine_Control_Module_U010000: start-on-event=DemSatellite_0InternalBehavior/GetEventUdsStatus, operation=EvtInfo_Loss_of_Comm_With_Engine_Control_Module_U010000.GetEventUdsStatus
        OpEventGetEventUdsStatus_GetEventUdsStatus_Event_Loss_of_Comm_With_Engine_Control_Module_U010000: start-on-event=DemSatellite_0InternalBehavior/GetEventUdsStatus, operation=Event_Loss_of_Comm_With_Engine_Control_Module_U010000.GetEventUdsStatus
        OpEventGetEventUdsStatus_GetEventUdsStatus_EvtInfo_Lost_Communication_with_Right_Camera_U026700: start-on-event=DemSatellite_0InternalBehavior/GetEventUdsStatus, operation=EvtInfo_Lost_Communication_with_Right_Camera_U026700.GetEventUdsStatus
        OpEventGetEventUdsStatus_GetEventUdsStatus_Event_Lost_Communication_with_Right_Camera_U026700: start-on-event=DemSatellite_0InternalBehavior/GetEventUdsStatus, operation=Event_Lost_Communication_with_Right_Camera_U026700.GetEventUdsStatus
        OpEventGetEventUdsStatus_GetEventUdsStatus_EvtInfo_PTS_Sensor_1_Performance_or_Incorrect_Operation_B128E92: start-on-event=DemSatellite_0InternalBehavior/GetEventUdsStatus, operation=EvtInfo_PTS_Sensor_1_Performance_or_Incorrect_Operation_B128E92.GetEventUdsStatus
        OpEventGetEventUdsStatus_GetEventUdsStatus_Event_PTS_Sensor_1_Performance_or_Incorrect_Operation_B128E92: start-on-event=DemSatellite_0InternalBehavior/GetEventUdsStatus, operation=Event_PTS_Sensor_1_Performance_or_Incorrect_Operation_B128E92.GetEventUdsStatus
        OpEventGetEventUdsStatus_GetEventUdsStatus_EvtInfo_Rear_Camera_Performance_or_Incorrect_Operation_B217A92: start-on-event=DemSatellite_0InternalBehavior/GetEventUdsStatus, operation=EvtInfo_Rear_Camera_Performance_or_Incorrect_Operation_B217A92.GetEventUdsStatus
        OpEventGetEventUdsStatus_GetEventUdsStatus_Event_Rear_Camera_Performance_or_Incorrect_Operation_B217A92: start-on-event=DemSatellite_0InternalBehavior/GetEventUdsStatus, operation=Event_Rear_Camera_Performance_or_Incorrect_Operation_B217A92.GetEventUdsStatus
        OpEventGetEventUdsStatus_GetEventUdsStatus_EvtInfo_PTS_Sensor_2_Performance_or_Incorrect_Operation_B128F92: start-on-event=DemSatellite_0InternalBehavior/GetEventUdsStatus, operation=EvtInfo_PTS_Sensor_2_Performance_or_Incorrect_Operation_B128F92.GetEventUdsStatus
        OpEventGetEventUdsStatus_GetEventUdsStatus_Event_PTS_Sensor_2_Performance_or_Incorrect_Operation_B128F92: start-on-event=DemSatellite_0InternalBehavior/GetEventUdsStatus, operation=Event_PTS_Sensor_2_Performance_or_Incorrect_Operation_B128F92.GetEventUdsStatus
        OpEventGetEventUdsStatus_GetEventUdsStatus_EvtInfo_Right_Camera_Circuit_Voltage_Out_of_Range_B23C71C: start-on-event=DemSatellite_0InternalBehavior/GetEventUdsStatus, operation=EvtInfo_Right_Camera_Circuit_Voltage_Out_of_Range_B23C71C.GetEventUdsStatus
        OpEventGetEventUdsStatus_GetEventUdsStatus_Event_Right_Camera_Circuit_Voltage_Out_of_Range_B23C71C: start-on-event=DemSatellite_0InternalBehavior/GetEventUdsStatus, operation=Event_Right_Camera_Circuit_Voltage_Out_of_Range_B23C71C.GetEventUdsStatus
        OpEventGetEventUdsStatus_GetEventUdsStatus_EvtInfo_PTS_Sensor_8_Circuit_Open_B129513: start-on-event=DemSatellite_0InternalBehavior/GetEventUdsStatus, operation=EvtInfo_PTS_Sensor_8_Circuit_Open_B129513.GetEventUdsStatus
        OpEventGetEventUdsStatus_GetEventUdsStatus_Event_PTS_Sensor_8_Circuit_Open_B129513: start-on-event=DemSatellite_0InternalBehavior/GetEventUdsStatus, operation=Event_PTS_Sensor_8_Circuit_Open_B129513.GetEventUdsStatus
        OpEventGetEventUdsStatus_GetEventUdsStatus_EvtInfo_Implausible_Data_Received_from_Radio_U048500: start-on-event=DemSatellite_0InternalBehavior/GetEventUdsStatus, operation=EvtInfo_Implausible_Data_Received_from_Radio_U048500.GetEventUdsStatus
        OpEventGetEventUdsStatus_GetEventUdsStatus_Event_Implausible_Data_Received_from_Radio_U048500: start-on-event=DemSatellite_0InternalBehavior/GetEventUdsStatus, operation=Event_Implausible_Data_Received_from_Radio_U048500.GetEventUdsStatus
        OpEventGetEventUdsStatus_GetEventUdsStatus_EvtInfo_Implausible_Data_received_from_TRSKM_module_U14A000: start-on-event=DemSatellite_0InternalBehavior/GetEventUdsStatus, operation=EvtInfo_Implausible_Data_received_from_TRSKM_module_U14A000.GetEventUdsStatus
        OpEventGetEventUdsStatus_GetEventUdsStatus_Event_Implausible_Data_received_from_TRSKM_module_U14A000: start-on-event=DemSatellite_0InternalBehavior/GetEventUdsStatus, operation=Event_Implausible_Data_received_from_TRSKM_module_U14A000.GetEventUdsStatus
        OpEventGetEventUdsStatus_GetEventUdsStatus_EvtInfo_Front_Camera_Performance_or_Incorrect_Operation_B23C592: start-on-event=DemSatellite_0InternalBehavior/GetEventUdsStatus, operation=EvtInfo_Front_Camera_Performance_or_Incorrect_Operation_B23C592.GetEventUdsStatus
        OpEventGetEventUdsStatus_GetEventUdsStatus_Event_Front_Camera_Performance_or_Incorrect_Operation_B23C592: start-on-event=DemSatellite_0InternalBehavior/GetEventUdsStatus, operation=Event_Front_Camera_Performance_or_Incorrect_Operation_B23C592.GetEventUdsStatus
        OpEventGetEventUdsStatus_GetEventUdsStatus_EvtInfo_Loss_Communication_with_TRS_Knob_Module_U12B900: start-on-event=DemSatellite_0InternalBehavior/GetEventUdsStatus, operation=EvtInfo_Loss_Communication_with_TRS_Knob_Module_U12B900.GetEventUdsStatus
        OpEventGetEventUdsStatus_GetEventUdsStatus_Event_Loss_Communication_with_TRS_Knob_Module_U12B900: start-on-event=DemSatellite_0InternalBehavior/GetEventUdsStatus, operation=Event_Loss_Communication_with_TRS_Knob_Module_U12B900.GetEventUdsStatus
        OpEventGetEventUdsStatus_GetEventUdsStatus_EvtInfo_PTS_Sensor_7_Circuit_Open_B129413: start-on-event=DemSatellite_0InternalBehavior/GetEventUdsStatus, operation=EvtInfo_PTS_Sensor_7_Circuit_Open_B129413.GetEventUdsStatus
        OpEventGetEventUdsStatus_GetEventUdsStatus_Event_PTS_Sensor_7_Circuit_Open_B129413: start-on-event=DemSatellite_0InternalBehavior/GetEventUdsStatus, operation=Event_PTS_Sensor_7_Circuit_Open_B129413.GetEventUdsStatus
        OpEventGetEventUdsStatus_GetEventUdsStatus_EvtInfo_Front_Sensors_PS_Bus_Sig_Msg_Failures_B212A08: start-on-event=DemSatellite_0InternalBehavior/GetEventUdsStatus, operation=EvtInfo_Front_Sensors_PS_Bus_Sig_Msg_Failures_B212A08.GetEventUdsStatus
        OpEventGetEventUdsStatus_GetEventUdsStatus_Event_Front_Sensors_PS_Bus_Sig_Msg_Failures_B212A08: start-on-event=DemSatellite_0InternalBehavior/GetEventUdsStatus, operation=Event_Front_Sensors_PS_Bus_Sig_Msg_Failures_B212A08.GetEventUdsStatus
        OpEventGetEventUdsStatus_GetEventUdsStatus_EvtInfo_Lost_Communication_With_PSC_Module_A_U013100: start-on-event=DemSatellite_0InternalBehavior/GetEventUdsStatus, operation=EvtInfo_Lost_Communication_With_PSC_Module_A_U013100.GetEventUdsStatus
        OpEventGetEventUdsStatus_GetEventUdsStatus_Event_Lost_Communication_With_PSC_Module_A_U013100: start-on-event=DemSatellite_0InternalBehavior/GetEventUdsStatus, operation=Event_Lost_Communication_With_PSC_Module_A_U013100.GetEventUdsStatus
        OpEventGetEventUdsStatus_GetEventUdsStatus_EvtInfo_Lost_Communication_with_Front_Camera_U026500: start-on-event=DemSatellite_0InternalBehavior/GetEventUdsStatus, operation=EvtInfo_Lost_Communication_with_Front_Camera_U026500.GetEventUdsStatus
        OpEventGetEventUdsStatus_GetEventUdsStatus_Event_Lost_Communication_with_Front_Camera_U026500: start-on-event=DemSatellite_0InternalBehavior/GetEventUdsStatus, operation=Event_Lost_Communication_with_Front_Camera_U026500.GetEventUdsStatus
        OpEventGetEventUdsStatus_GetEventUdsStatus_EvtInfo_PTS_Sensor_3_Performance_or_Incorrect_Operation_B129092: start-on-event=DemSatellite_0InternalBehavior/GetEventUdsStatus, operation=EvtInfo_PTS_Sensor_3_Performance_or_Incorrect_Operation_B129092.GetEventUdsStatus
        OpEventGetEventUdsStatus_GetEventUdsStatus_Event_PTS_Sensor_3_Performance_or_Incorrect_Operation_B129092: start-on-event=DemSatellite_0InternalBehavior/GetEventUdsStatus, operation=Event_PTS_Sensor_3_Performance_or_Incorrect_Operation_B129092.GetEventUdsStatus
        OpEventGetEventUdsStatus_GetEventUdsStatus_EvtInfo_PTS_Sensor_8_Performance_or_Incorrect_Operation_B129592: start-on-event=DemSatellite_0InternalBehavior/GetEventUdsStatus, operation=EvtInfo_PTS_Sensor_8_Performance_or_Incorrect_Operation_B129592.GetEventUdsStatus
        OpEventGetEventUdsStatus_GetEventUdsStatus_Event_PTS_Sensor_8_Performance_or_Incorrect_Operation_B129592: start-on-event=DemSatellite_0InternalBehavior/GetEventUdsStatus, operation=Event_PTS_Sensor_8_Performance_or_Incorrect_Operation_B129592.GetEventUdsStatus
        OpEventGetEventUdsStatus_GetEventUdsStatus_EvtInfo_PPP_Assist_Switch_Stuck_B12B22A: start-on-event=DemSatellite_0InternalBehavior/GetEventUdsStatus, operation=EvtInfo_PPP_Assist_Switch_Stuck_B12B22A.GetEventUdsStatus
        OpEventGetEventUdsStatus_GetEventUdsStatus_Event_PPP_Assist_Switch_Stuck_B12B22A: start-on-event=DemSatellite_0InternalBehavior/GetEventUdsStatus, operation=Event_PPP_Assist_Switch_Stuck_B12B22A.GetEventUdsStatus
        OpEventGetEventUdsStatus_GetEventUdsStatus_EvtInfo_Implausible_data_received_from_ECM_U040100: start-on-event=DemSatellite_0InternalBehavior/GetEventUdsStatus, operation=EvtInfo_Implausible_data_received_from_ECM_U040100.GetEventUdsStatus
        OpEventGetEventUdsStatus_GetEventUdsStatus_Event_Implausible_data_received_from_ECM_U040100: start-on-event=DemSatellite_0InternalBehavior/GetEventUdsStatus, operation=Event_Implausible_data_received_from_ECM_U040100.GetEventUdsStatus
        OpEventGetEventUdsStatus_GetEventUdsStatus_EvtInfo_PTS_Sensor_10_Circuit_Open_B129713: start-on-event=DemSatellite_0InternalBehavior/GetEventUdsStatus, operation=EvtInfo_PTS_Sensor_10_Circuit_Open_B129713.GetEventUdsStatus
        OpEventGetEventUdsStatus_GetEventUdsStatus_Event_PTS_Sensor_10_Circuit_Open_B129713: start-on-event=DemSatellite_0InternalBehavior/GetEventUdsStatus, operation=Event_PTS_Sensor_10_Circuit_Open_B129713.GetEventUdsStatus
        OpEventGetEventUdsStatus_GetEventUdsStatus_EvtInfo_Lost_Communication_With_BSC_module_1_U012900: start-on-event=DemSatellite_0InternalBehavior/GetEventUdsStatus, operation=EvtInfo_Lost_Communication_With_BSC_module_1_U012900.GetEventUdsStatus
        OpEventGetEventUdsStatus_GetEventUdsStatus_Event_Lost_Communication_With_BSC_module_1_U012900: start-on-event=DemSatellite_0InternalBehavior/GetEventUdsStatus, operation=Event_Lost_Communication_With_BSC_module_1_U012900.GetEventUdsStatus
        OpEventGetEventUdsStatus_GetEventUdsStatus_EvtInfo_PTS_Sensor_7_Performance_or_Incorrect_Operation_B129492: start-on-event=DemSatellite_0InternalBehavior/GetEventUdsStatus, operation=EvtInfo_PTS_Sensor_7_Performance_or_Incorrect_Operation_B129492.GetEventUdsStatus
        OpEventGetEventUdsStatus_GetEventUdsStatus_Event_PTS_Sensor_7_Performance_or_Incorrect_Operation_B129492: start-on-event=DemSatellite_0InternalBehavior/GetEventUdsStatus, operation=Event_PTS_Sensor_7_Performance_or_Incorrect_Operation_B129492.GetEventUdsStatus
        OpEventGetEventUdsStatus_GetEventUdsStatus_EvtInfo_Left_Camera_Performance_or_Incorrect_Operation_B23C692: start-on-event=DemSatellite_0InternalBehavior/GetEventUdsStatus, operation=EvtInfo_Left_Camera_Performance_or_Incorrect_Operation_B23C692.GetEventUdsStatus
        OpEventGetEventUdsStatus_GetEventUdsStatus_Event_Left_Camera_Performance_or_Incorrect_Operation_B23C692: start-on-event=DemSatellite_0InternalBehavior/GetEventUdsStatus, operation=Event_Left_Camera_Performance_or_Incorrect_Operation_B23C692.GetEventUdsStatus
        OpEventGetEventUdsStatus_GetEventUdsStatus_EvtInfo_Vehicle_Configuration_Mismatch_B223B00: start-on-event=DemSatellite_0InternalBehavior/GetEventUdsStatus, operation=EvtInfo_Vehicle_Configuration_Mismatch_B223B00.GetEventUdsStatus
        OpEventGetEventUdsStatus_GetEventUdsStatus_Event_Vehicle_Configuration_Mismatch_B223B00: start-on-event=DemSatellite_0InternalBehavior/GetEventUdsStatus, operation=Event_Vehicle_Configuration_Mismatch_B223B00.GetEventUdsStatus
        OpEventGetEventUdsStatus_GetEventUdsStatus_EvtInfo_PTS_Sensor_6_Circuit_Open_B129313: start-on-event=DemSatellite_0InternalBehavior/GetEventUdsStatus, operation=EvtInfo_PTS_Sensor_6_Circuit_Open_B129313.GetEventUdsStatus
        OpEventGetEventUdsStatus_GetEventUdsStatus_Event_PTS_Sensor_6_Circuit_Open_B129313: start-on-event=DemSatellite_0InternalBehavior/GetEventUdsStatus, operation=Event_PTS_Sensor_6_Circuit_Open_B129313.GetEventUdsStatus
        OpEventGetEventUdsStatus_GetEventUdsStatus_EvtInfo_Front_Camera_Circuit_Voltage_Out_of_Range_B23C51C: start-on-event=DemSatellite_0InternalBehavior/GetEventUdsStatus, operation=EvtInfo_Front_Camera_Circuit_Voltage_Out_of_Range_B23C51C.GetEventUdsStatus
        OpEventGetEventUdsStatus_GetEventUdsStatus_Event_Front_Camera_Circuit_Voltage_Out_of_Range_B23C51C: start-on-event=DemSatellite_0InternalBehavior/GetEventUdsStatus, operation=Event_Front_Camera_Circuit_Voltage_Out_of_Range_B23C51C.GetEventUdsStatus
        OpEventGetEventUdsStatus_GetEventUdsStatus_EvtInfo_Implausible_Data_From_BSC_Module_1_U041800: start-on-event=DemSatellite_0InternalBehavior/GetEventUdsStatus, operation=EvtInfo_Implausible_Data_From_BSC_Module_1_U041800.GetEventUdsStatus
        OpEventGetEventUdsStatus_GetEventUdsStatus_Event_Implausible_Data_From_BSC_Module_1_U041800: start-on-event=DemSatellite_0InternalBehavior/GetEventUdsStatus, operation=Event_Implausible_Data_From_BSC_Module_1_U041800.GetEventUdsStatus
        OpEventGetEventUdsStatus_GetEventUdsStatus_EvtInfo_PTS_Sensor_10_Performance_or_Incorrect_Operation_B129792: start-on-event=DemSatellite_0InternalBehavior/GetEventUdsStatus, operation=EvtInfo_PTS_Sensor_10_Performance_or_Incorrect_Operation_B129792.GetEventUdsStatus
        OpEventGetEventUdsStatus_GetEventUdsStatus_Event_PTS_Sensor_10_Performance_or_Incorrect_Operation_B129792: start-on-event=DemSatellite_0InternalBehavior/GetEventUdsStatus, operation=Event_PTS_Sensor_10_Performance_or_Incorrect_Operation_B129792.GetEventUdsStatus
        OpEventGetEventUdsStatus_GetEventUdsStatus_EvtInfo_PTS_Sensor_11_Circuit_Open_B129813: start-on-event=DemSatellite_0InternalBehavior/GetEventUdsStatus, operation=EvtInfo_PTS_Sensor_11_Circuit_Open_B129813.GetEventUdsStatus
        OpEventGetEventUdsStatus_GetEventUdsStatus_Event_PTS_Sensor_11_Circuit_Open_B129813: start-on-event=DemSatellite_0InternalBehavior/GetEventUdsStatus, operation=Event_PTS_Sensor_11_Circuit_Open_B129813.GetEventUdsStatus
        OpEventGetEventUdsStatus_GetEventUdsStatus_EvtInfo_ECU_Internal_Performance_B22A900: start-on-event=DemSatellite_0InternalBehavior/GetEventUdsStatus, operation=EvtInfo_ECU_Internal_Performance_B22A900.GetEventUdsStatus
        OpEventGetEventUdsStatus_GetEventUdsStatus_Event_ECU_Internal_Performance_B22A900: start-on-event=DemSatellite_0InternalBehavior/GetEventUdsStatus, operation=Event_ECU_Internal_Performance_B22A900.GetEventUdsStatus
        OpEventGetEventUdsStatus_GetEventUdsStatus_EvtInfo_PTS_Sensor_9_Performance_or_Incorrect_Operation_B129692: start-on-event=DemSatellite_0InternalBehavior/GetEventUdsStatus, operation=EvtInfo_PTS_Sensor_9_Performance_or_Incorrect_Operation_B129692.GetEventUdsStatus
        OpEventGetEventUdsStatus_GetEventUdsStatus_Event_PTS_Sensor_9_Performance_or_Incorrect_Operation_B129692: start-on-event=DemSatellite_0InternalBehavior/GetEventUdsStatus, operation=Event_PTS_Sensor_9_Performance_or_Incorrect_Operation_B129692.GetEventUdsStatus
        OpEventGetEventUdsStatus_GetEventUdsStatus_EvtInfo_Calibration_Not_Learned_Lost_Calibration_B228600: start-on-event=DemSatellite_0InternalBehavior/GetEventUdsStatus, operation=EvtInfo_Calibration_Not_Learned_Lost_Calibration_B228600.GetEventUdsStatus
        OpEventGetEventUdsStatus_GetEventUdsStatus_Event_Calibration_Not_Learned_Lost_Calibration_B228600: start-on-event=DemSatellite_0InternalBehavior/GetEventUdsStatus, operation=Event_Calibration_Not_Learned_Lost_Calibration_B228600.GetEventUdsStatus
        OpEventGetEventUdsStatus_GetEventUdsStatus_EvtInfo_Lost_Communication_with_ORC_U015100: start-on-event=DemSatellite_0InternalBehavior/GetEventUdsStatus, operation=EvtInfo_Lost_Communication_with_ORC_U015100.GetEventUdsStatus
        OpEventGetEventUdsStatus_GetEventUdsStatus_Event_Lost_Communication_with_ORC_U015100: start-on-event=DemSatellite_0InternalBehavior/GetEventUdsStatus, operation=Event_Lost_Communication_with_ORC_U015100.GetEventUdsStatus
        OpEventGetEventUdsStatus_GetEventUdsStatus_EvtInfo_PTS_Sensor_1_Circuit_Open_B128E13: start-on-event=DemSatellite_0InternalBehavior/GetEventUdsStatus, operation=EvtInfo_PTS_Sensor_1_Circuit_Open_B128E13.GetEventUdsStatus
        OpEventGetEventUdsStatus_GetEventUdsStatus_Event_PTS_Sensor_1_Circuit_Open_B128E13: start-on-event=DemSatellite_0InternalBehavior/GetEventUdsStatus, operation=Event_PTS_Sensor_1_Circuit_Open_B128E13.GetEventUdsStatus
        OpEventGetEventUdsStatus_GetEventUdsStatus_EvtInfo_Lost_Communication_with_Rear_Camera_U026400: start-on-event=DemSatellite_0InternalBehavior/GetEventUdsStatus, operation=EvtInfo_Lost_Communication_with_Rear_Camera_U026400.GetEventUdsStatus
        OpEventGetEventUdsStatus_GetEventUdsStatus_Event_Lost_Communication_with_Rear_Camera_U026400: start-on-event=DemSatellite_0InternalBehavior/GetEventUdsStatus, operation=Event_Lost_Communication_with_Rear_Camera_U026400.GetEventUdsStatus
        OpEventGetEventUdsStatus_GetEventUdsStatus_EvtInfo_HS_FD_CANR_Comm_Bus_Performance_U100B00: start-on-event=DemSatellite_0InternalBehavior/GetEventUdsStatus, operation=EvtInfo_HS_FD_CANR_Comm_Bus_Performance_U100B00.GetEventUdsStatus
        OpEventGetEventUdsStatus_GetEventUdsStatus_Event_HS_FD_CANR_Comm_Bus_Performance_U100B00: start-on-event=DemSatellite_0InternalBehavior/GetEventUdsStatus, operation=Event_HS_FD_CANR_Comm_Bus_Performance_U100B00.GetEventUdsStatus
        OpEventGetEventUdsStatus_GetEventUdsStatus_EvtInfo_Implausible_Data_Received_From_Body_Control_Module_U042200: start-on-event=DemSatellite_0InternalBehavior/GetEventUdsStatus, operation=EvtInfo_Implausible_Data_Received_From_Body_Control_Module_U042200.GetEventUdsStatus
        OpEventGetEventUdsStatus_GetEventUdsStatus_Event_Implausible_Data_Received_From_Body_Control_Module_U042200: start-on-event=DemSatellite_0InternalBehavior/GetEventUdsStatus, operation=Event_Implausible_Data_Received_From_Body_Control_Module_U042200.GetEventUdsStatus
        OpEventGetEventUdsStatus_GetEventUdsStatus_EvtInfo_Lost_Communication_With_BCM_U014000: start-on-event=DemSatellite_0InternalBehavior/GetEventUdsStatus, operation=EvtInfo_Lost_Communication_With_BCM_U014000.GetEventUdsStatus
        OpEventGetEventUdsStatus_GetEventUdsStatus_Event_Lost_Communication_With_BCM_U014000: start-on-event=DemSatellite_0InternalBehavior/GetEventUdsStatus, operation=Event_Lost_Communication_With_BCM_U014000.GetEventUdsStatus
        OpEventGetEventUdsStatus_GetEventUdsStatus_EvtInfo_PTS_Sensor_2_Circuit_Open_B128F13: start-on-event=DemSatellite_0InternalBehavior/GetEventUdsStatus, operation=EvtInfo_PTS_Sensor_2_Circuit_Open_B128F13.GetEventUdsStatus
        OpEventGetEventUdsStatus_GetEventUdsStatus_Event_PTS_Sensor_2_Circuit_Open_B128F13: start-on-event=DemSatellite_0InternalBehavior/GetEventUdsStatus, operation=Event_PTS_Sensor_2_Circuit_Open_B128F13.GetEventUdsStatus
        OpEventGetEventUdsStatus_GetEventUdsStatus_EvtInfo_PTS_Sensor_3_Circuit_Open_B129013: start-on-event=DemSatellite_0InternalBehavior/GetEventUdsStatus, operation=EvtInfo_PTS_Sensor_3_Circuit_Open_B129013.GetEventUdsStatus
        OpEventGetEventUdsStatus_GetEventUdsStatus_Event_PTS_Sensor_3_Circuit_Open_B129013: start-on-event=DemSatellite_0InternalBehavior/GetEventUdsStatus, operation=Event_PTS_Sensor_3_Circuit_Open_B129013.GetEventUdsStatus
        OpEventGetEventUdsStatus_GetEventUdsStatus_EvtInfo_ECU_In_Plant_Mode_C221200: start-on-event=DemSatellite_0InternalBehavior/GetEventUdsStatus, operation=EvtInfo_ECU_In_Plant_Mode_C221200.GetEventUdsStatus
        OpEventGetEventUdsStatus_GetEventUdsStatus_Event_ECU_In_Plant_Mode_C221200: start-on-event=DemSatellite_0InternalBehavior/GetEventUdsStatus, operation=Event_ECU_In_Plant_Mode_C221200.GetEventUdsStatus
        OpEventGetEventUdsStatus_GetEventUdsStatus_EvtInfo_Implausible_Data_from_ORC_module_U045500: start-on-event=DemSatellite_0InternalBehavior/GetEventUdsStatus, operation=EvtInfo_Implausible_Data_from_ORC_module_U045500.GetEventUdsStatus
        OpEventGetEventUdsStatus_GetEventUdsStatus_Event_Implausible_Data_from_ORC_module_U045500: start-on-event=DemSatellite_0InternalBehavior/GetEventUdsStatus, operation=Event_Implausible_Data_from_ORC_module_U045500.GetEventUdsStatus
        OpEventGetEventUdsStatus_GetEventUdsStatus_EvtInfo_Right_Camera_Performance_or_Incorrect_Operation_B23C792: start-on-event=DemSatellite_0InternalBehavior/GetEventUdsStatus, operation=EvtInfo_Right_Camera_Performance_or_Incorrect_Operation_B23C792.GetEventUdsStatus
        OpEventGetEventUdsStatus_GetEventUdsStatus_Event_Right_Camera_Performance_or_Incorrect_Operation_B23C792: start-on-event=DemSatellite_0InternalBehavior/GetEventUdsStatus, operation=Event_Right_Camera_Performance_or_Incorrect_Operation_B23C792.GetEventUdsStatus
        OpEventGetEventUdsStatus_GetEventUdsStatus_EvtInfo_Rear_Sensors_PS_VltgeAboveThreshold_B212B17: start-on-event=DemSatellite_0InternalBehavior/GetEventUdsStatus, operation=EvtInfo_Rear_Sensors_PS_VltgeAboveThreshold_B212B17.GetEventUdsStatus
        OpEventGetEventUdsStatus_GetEventUdsStatus_Event_Rear_Sensors_PS_VltgeAboveThreshold_B212B17: start-on-event=DemSatellite_0InternalBehavior/GetEventUdsStatus, operation=Event_Rear_Sensors_PS_VltgeAboveThreshold_B212B17.GetEventUdsStatus
        OpEventGetEventUdsStatus_GetEventUdsStatus_EvtInfo_PTS_Sensor_6_Performance_or_Incorrect_Operation_B129392: start-on-event=DemSatellite_0InternalBehavior/GetEventUdsStatus, operation=EvtInfo_PTS_Sensor_6_Performance_or_Incorrect_Operation_B129392.GetEventUdsStatus
        OpEventGetEventUdsStatus_GetEventUdsStatus_Event_PTS_Sensor_6_Performance_or_Incorrect_Operation_B129392: start-on-event=DemSatellite_0InternalBehavior/GetEventUdsStatus, operation=Event_PTS_Sensor_6_Performance_or_Incorrect_Operation_B129392.GetEventUdsStatus
        OpEventGetEventUdsStatus_GetEventUdsStatus_GeneralEvtInfo: start-on-event=DemSatellite_0InternalBehavior/GetEventUdsStatus, operation=GeneralEvtInfo.GetEventUdsStatus
        OpEventGetEventStatus_GetEventStatus_EvtInfo_Dem_SystemInternalFailure: start-on-event=DemSatellite_0InternalBehavior/GetEventStatus, operation=EvtInfo_Dem_SystemInternalFailure.GetEventStatus
        OpEventGetEventStatus_GetEventStatus_Event_Dem_SystemInternalFailure: start-on-event=DemSatellite_0InternalBehavior/GetEventStatus, operation=Event_Dem_SystemInternalFailure.GetEventStatus
        OpEventGetEventStatus_GetEventStatus_EvtInfo_Invalid_Data_Received_From_Power_Steering_Control_Module_U042000: start-on-event=DemSatellite_0InternalBehavior/GetEventStatus, operation=EvtInfo_Invalid_Data_Received_From_Power_Steering_Control_Module_U042000.GetEventStatus
        OpEventGetEventStatus_GetEventStatus_Event_Invalid_Data_Received_From_Power_Steering_Control_Module_U042000: start-on-event=DemSatellite_0InternalBehavior/GetEventStatus, operation=Event_Invalid_Data_Received_From_Power_Steering_Control_Module_U042000.GetEventStatus
        OpEventGetEventStatus_GetEventStatus_EvtInfo_Lost_Communication_with_Left_Camera_U026600: start-on-event=DemSatellite_0InternalBehavior/GetEventStatus, operation=EvtInfo_Lost_Communication_with_Left_Camera_U026600.GetEventStatus
        OpEventGetEventStatus_GetEventStatus_Event_Lost_Communication_with_Left_Camera_U026600: start-on-event=DemSatellite_0InternalBehavior/GetEventStatus, operation=Event_Lost_Communication_with_Left_Camera_U026600.GetEventStatus
        OpEventGetEventStatus_GetEventStatus_EvtInfo_Front_Sensors_PS_VltgeBelowThreshold_B212A16: start-on-event=DemSatellite_0InternalBehavior/GetEventStatus, operation=EvtInfo_Front_Sensors_PS_VltgeBelowThreshold_B212A16.GetEventStatus
        OpEventGetEventStatus_GetEventStatus_Event_Front_Sensors_PS_VltgeBelowThreshold_B212A16: start-on-event=DemSatellite_0InternalBehavior/GetEventStatus, operation=Event_Front_Sensors_PS_VltgeBelowThreshold_B212A16.GetEventStatus
        OpEventGetEventStatus_GetEventStatus_EvtInfo_Left_Camera_Circuit_Voltage_Out_of_Range_B23C61C: start-on-event=DemSatellite_0InternalBehavior/GetEventStatus, operation=EvtInfo_Left_Camera_Circuit_Voltage_Out_of_Range_B23C61C.GetEventStatus
        OpEventGetEventStatus_GetEventStatus_Event_Left_Camera_Circuit_Voltage_Out_of_Range_B23C61C: start-on-event=DemSatellite_0InternalBehavior/GetEventStatus, operation=Event_Left_Camera_Circuit_Voltage_Out_of_Range_B23C61C.GetEventStatus
        OpEventGetEventStatus_GetEventStatus_EvtInfo_Rear_Sensors_PS_VltgeBelowThreshold_B212B16: start-on-event=DemSatellite_0InternalBehavior/GetEventStatus, operation=EvtInfo_Rear_Sensors_PS_VltgeBelowThreshold_B212B16.GetEventStatus
        OpEventGetEventStatus_GetEventStatus_Event_Rear_Sensors_PS_VltgeBelowThreshold_B212B16: start-on-event=DemSatellite_0InternalBehavior/GetEventStatus, operation=Event_Rear_Sensors_PS_VltgeBelowThreshold_B212B16.GetEventStatus
        OpEventGetEventStatus_GetEventStatus_EvtInfo_Rear_Sensors_PS_Bus_Sig_Msg_Failures_B212B08: start-on-event=DemSatellite_0InternalBehavior/GetEventStatus, operation=EvtInfo_Rear_Sensors_PS_Bus_Sig_Msg_Failures_B212B08.GetEventStatus
        OpEventGetEventStatus_GetEventStatus_Event_Rear_Sensors_PS_Bus_Sig_Msg_Failures_B212B08: start-on-event=DemSatellite_0InternalBehavior/GetEventStatus, operation=Event_Rear_Sensors_PS_Bus_Sig_Msg_Failures_B212B08.GetEventStatus
        OpEventGetEventStatus_GetEventStatus_EvtInfo_Rear_Camera_Circuit_Voltage_Out_of_Range_B217A1C: start-on-event=DemSatellite_0InternalBehavior/GetEventStatus, operation=EvtInfo_Rear_Camera_Circuit_Voltage_Out_of_Range_B217A1C.GetEventStatus
        OpEventGetEventStatus_GetEventStatus_Event_Rear_Camera_Circuit_Voltage_Out_of_Range_B217A1C: start-on-event=DemSatellite_0InternalBehavior/GetEventStatus, operation=Event_Rear_Camera_Circuit_Voltage_Out_of_Range_B217A1C.GetEventStatus
        OpEventGetEventStatus_GetEventStatus_EvtInfo_PTS_Sensor_12_Performance_or_Incorrect_Operation_B129992: start-on-event=DemSatellite_0InternalBehavior/GetEventStatus, operation=EvtInfo_PTS_Sensor_12_Performance_or_Incorrect_Operation_B129992.GetEventStatus
        OpEventGetEventStatus_GetEventStatus_Event_PTS_Sensor_12_Performance_or_Incorrect_Operation_B129992: start-on-event=DemSatellite_0InternalBehavior/GetEventStatus, operation=Event_PTS_Sensor_12_Performance_or_Incorrect_Operation_B129992.GetEventStatus
        OpEventGetEventStatus_GetEventStatus_EvtInfo_Battery_Voltage_Over_Voltage_B210C17: start-on-event=DemSatellite_0InternalBehavior/GetEventStatus, operation=EvtInfo_Battery_Voltage_Over_Voltage_B210C17.GetEventStatus
        OpEventGetEventStatus_GetEventStatus_Event_Battery_Voltage_Over_Voltage_B210C17: start-on-event=DemSatellite_0InternalBehavior/GetEventStatus, operation=Event_Battery_Voltage_Over_Voltage_B210C17.GetEventStatus
        OpEventGetEventStatus_GetEventStatus_EvtInfo_Front_Sensors_PS_VltgeAboveThreshold_B212A17: start-on-event=DemSatellite_0InternalBehavior/GetEventStatus, operation=EvtInfo_Front_Sensors_PS_VltgeAboveThreshold_B212A17.GetEventStatus
        OpEventGetEventStatus_GetEventStatus_Event_Front_Sensors_PS_VltgeAboveThreshold_B212A17: start-on-event=DemSatellite_0InternalBehavior/GetEventStatus, operation=Event_Front_Sensors_PS_VltgeAboveThreshold_B212A17.GetEventStatus
        OpEventGetEventStatus_GetEventStatus_EvtInfo_PTS_Sensor_4_Circuit_Open_B129113: start-on-event=DemSatellite_0InternalBehavior/GetEventStatus, operation=EvtInfo_PTS_Sensor_4_Circuit_Open_B129113.GetEventStatus
        OpEventGetEventStatus_GetEventStatus_Event_PTS_Sensor_4_Circuit_Open_B129113: start-on-event=DemSatellite_0InternalBehavior/GetEventStatus, operation=Event_PTS_Sensor_4_Circuit_Open_B129113.GetEventStatus
        OpEventGetEventStatus_GetEventStatus_EvtInfo_PTS_Sensor_12_Circuit_Open_B129913: start-on-event=DemSatellite_0InternalBehavior/GetEventStatus, operation=EvtInfo_PTS_Sensor_12_Circuit_Open_B129913.GetEventStatus
        OpEventGetEventStatus_GetEventStatus_Event_PTS_Sensor_12_Circuit_Open_B129913: start-on-event=DemSatellite_0InternalBehavior/GetEventStatus, operation=Event_PTS_Sensor_12_Circuit_Open_B129913.GetEventStatus
        OpEventGetEventStatus_GetEventStatus_EvtInfo_PTS_Sensor_11_Performance_or_Incorrect_Operation_B129892: start-on-event=DemSatellite_0InternalBehavior/GetEventStatus, operation=EvtInfo_PTS_Sensor_11_Performance_or_Incorrect_Operation_B129892.GetEventStatus
        OpEventGetEventStatus_GetEventStatus_Event_PTS_Sensor_11_Performance_or_Incorrect_Operation_B129892: start-on-event=DemSatellite_0InternalBehavior/GetEventStatus, operation=Event_PTS_Sensor_11_Performance_or_Incorrect_Operation_B129892.GetEventStatus
        OpEventGetEventStatus_GetEventStatus_EvtInfo_Lost_Communication_With_Radio_U018400: start-on-event=DemSatellite_0InternalBehavior/GetEventStatus, operation=EvtInfo_Lost_Communication_With_Radio_U018400.GetEventStatus
        OpEventGetEventStatus_GetEventStatus_Event_Lost_Communication_With_Radio_U018400: start-on-event=DemSatellite_0InternalBehavior/GetEventStatus, operation=Event_Lost_Communication_With_Radio_U018400.GetEventStatus
        OpEventGetEventStatus_GetEventStatus_EvtInfo_Park_Assist_PTS_Switch_Stuck_B12852A: start-on-event=DemSatellite_0InternalBehavior/GetEventStatus, operation=EvtInfo_Park_Assist_PTS_Switch_Stuck_B12852A.GetEventStatus
        OpEventGetEventStatus_GetEventStatus_Event_Park_Assist_PTS_Switch_Stuck_B12852A: start-on-event=DemSatellite_0InternalBehavior/GetEventStatus, operation=Event_Park_Assist_PTS_Switch_Stuck_B12852A.GetEventStatus
        OpEventGetEventStatus_GetEventStatus_EvtInfo_PTS_Sensor_5_Circuit_Open_B129213: start-on-event=DemSatellite_0InternalBehavior/GetEventStatus, operation=EvtInfo_PTS_Sensor_5_Circuit_Open_B129213.GetEventStatus
        OpEventGetEventStatus_GetEventStatus_Event_PTS_Sensor_5_Circuit_Open_B129213: start-on-event=DemSatellite_0InternalBehavior/GetEventStatus, operation=Event_PTS_Sensor_5_Circuit_Open_B129213.GetEventStatus
        OpEventGetEventStatus_GetEventStatus_EvtInfo_PTS_Sensor_5_Performance_or_Incorrect_Operation_B129292: start-on-event=DemSatellite_0InternalBehavior/GetEventStatus, operation=EvtInfo_PTS_Sensor_5_Performance_or_Incorrect_Operation_B129292.GetEventStatus
        OpEventGetEventStatus_GetEventStatus_Event_PTS_Sensor_5_Performance_or_Incorrect_Operation_B129292: start-on-event=DemSatellite_0InternalBehavior/GetEventStatus, operation=Event_PTS_Sensor_5_Performance_or_Incorrect_Operation_B129292.GetEventStatus
        OpEventGetEventStatus_GetEventStatus_EvtInfo_Battery_Voltage_Under_Voltage_B210C16: start-on-event=DemSatellite_0InternalBehavior/GetEventStatus, operation=EvtInfo_Battery_Voltage_Under_Voltage_B210C16.GetEventStatus
        OpEventGetEventStatus_GetEventStatus_Event_Battery_Voltage_Under_Voltage_B210C16: start-on-event=DemSatellite_0InternalBehavior/GetEventStatus, operation=Event_Battery_Voltage_Under_Voltage_B210C16.GetEventStatus
        OpEventGetEventStatus_GetEventStatus_EvtInfo_PTS_Sensor_4_Performance_or_Incorrect_Operation_B129192: start-on-event=DemSatellite_0InternalBehavior/GetEventStatus, operation=EvtInfo_PTS_Sensor_4_Performance_or_Incorrect_Operation_B129192.GetEventStatus
        OpEventGetEventStatus_GetEventStatus_Event_PTS_Sensor_4_Performance_or_Incorrect_Operation_B129192: start-on-event=DemSatellite_0InternalBehavior/GetEventStatus, operation=Event_PTS_Sensor_4_Performance_or_Incorrect_Operation_B129192.GetEventStatus
        OpEventGetEventStatus_GetEventStatus_EvtInfo_HS_FD_CAN2_Comm_Bus_Performance_U104E00: start-on-event=DemSatellite_0InternalBehavior/GetEventStatus, operation=EvtInfo_HS_FD_CAN2_Comm_Bus_Performance_U104E00.GetEventStatus
        OpEventGetEventStatus_GetEventStatus_Event_HS_FD_CAN2_Comm_Bus_Performance_U104E00: start-on-event=DemSatellite_0InternalBehavior/GetEventStatus, operation=Event_HS_FD_CAN2_Comm_Bus_Performance_U104E00.GetEventStatus
        OpEventGetEventStatus_GetEventStatus_EvtInfo_PTS_Sensor_9_Circuit_Open_B129613: start-on-event=DemSatellite_0InternalBehavior/GetEventStatus, operation=EvtInfo_PTS_Sensor_9_Circuit_Open_B129613.GetEventStatus
        OpEventGetEventStatus_GetEventStatus_Event_PTS_Sensor_9_Circuit_Open_B129613: start-on-event=DemSatellite_0InternalBehavior/GetEventStatus, operation=Event_PTS_Sensor_9_Circuit_Open_B129613.GetEventStatus
        OpEventGetEventStatus_GetEventStatus_EvtInfo_Loss_of_Comm_With_Engine_Control_Module_U010000: start-on-event=DemSatellite_0InternalBehavior/GetEventStatus, operation=EvtInfo_Loss_of_Comm_With_Engine_Control_Module_U010000.GetEventStatus
        OpEventGetEventStatus_GetEventStatus_Event_Loss_of_Comm_With_Engine_Control_Module_U010000: start-on-event=DemSatellite_0InternalBehavior/GetEventStatus, operation=Event_Loss_of_Comm_With_Engine_Control_Module_U010000.GetEventStatus
        OpEventGetEventStatus_GetEventStatus_EvtInfo_Lost_Communication_with_Right_Camera_U026700: start-on-event=DemSatellite_0InternalBehavior/GetEventStatus, operation=EvtInfo_Lost_Communication_with_Right_Camera_U026700.GetEventStatus
        OpEventGetEventStatus_GetEventStatus_Event_Lost_Communication_with_Right_Camera_U026700: start-on-event=DemSatellite_0InternalBehavior/GetEventStatus, operation=Event_Lost_Communication_with_Right_Camera_U026700.GetEventStatus
        OpEventGetEventStatus_GetEventStatus_EvtInfo_PTS_Sensor_1_Performance_or_Incorrect_Operation_B128E92: start-on-event=DemSatellite_0InternalBehavior/GetEventStatus, operation=EvtInfo_PTS_Sensor_1_Performance_or_Incorrect_Operation_B128E92.GetEventStatus
        OpEventGetEventStatus_GetEventStatus_Event_PTS_Sensor_1_Performance_or_Incorrect_Operation_B128E92: start-on-event=DemSatellite_0InternalBehavior/GetEventStatus, operation=Event_PTS_Sensor_1_Performance_or_Incorrect_Operation_B128E92.GetEventStatus
        OpEventGetEventStatus_GetEventStatus_EvtInfo_Rear_Camera_Performance_or_Incorrect_Operation_B217A92: start-on-event=DemSatellite_0InternalBehavior/GetEventStatus, operation=EvtInfo_Rear_Camera_Performance_or_Incorrect_Operation_B217A92.GetEventStatus
        OpEventGetEventStatus_GetEventStatus_Event_Rear_Camera_Performance_or_Incorrect_Operation_B217A92: start-on-event=DemSatellite_0InternalBehavior/GetEventStatus, operation=Event_Rear_Camera_Performance_or_Incorrect_Operation_B217A92.GetEventStatus
        OpEventGetEventStatus_GetEventStatus_EvtInfo_PTS_Sensor_2_Performance_or_Incorrect_Operation_B128F92: start-on-event=DemSatellite_0InternalBehavior/GetEventStatus, operation=EvtInfo_PTS_Sensor_2_Performance_or_Incorrect_Operation_B128F92.GetEventStatus
        OpEventGetEventStatus_GetEventStatus_Event_PTS_Sensor_2_Performance_or_Incorrect_Operation_B128F92: start-on-event=DemSatellite_0InternalBehavior/GetEventStatus, operation=Event_PTS_Sensor_2_Performance_or_Incorrect_Operation_B128F92.GetEventStatus
        OpEventGetEventStatus_GetEventStatus_EvtInfo_Right_Camera_Circuit_Voltage_Out_of_Range_B23C71C: start-on-event=DemSatellite_0InternalBehavior/GetEventStatus, operation=EvtInfo_Right_Camera_Circuit_Voltage_Out_of_Range_B23C71C.GetEventStatus
        OpEventGetEventStatus_GetEventStatus_Event_Right_Camera_Circuit_Voltage_Out_of_Range_B23C71C: start-on-event=DemSatellite_0InternalBehavior/GetEventStatus, operation=Event_Right_Camera_Circuit_Voltage_Out_of_Range_B23C71C.GetEventStatus
        OpEventGetEventStatus_GetEventStatus_EvtInfo_PTS_Sensor_8_Circuit_Open_B129513: start-on-event=DemSatellite_0InternalBehavior/GetEventStatus, operation=EvtInfo_PTS_Sensor_8_Circuit_Open_B129513.GetEventStatus
        OpEventGetEventStatus_GetEventStatus_Event_PTS_Sensor_8_Circuit_Open_B129513: start-on-event=DemSatellite_0InternalBehavior/GetEventStatus, operation=Event_PTS_Sensor_8_Circuit_Open_B129513.GetEventStatus
        OpEventGetEventStatus_GetEventStatus_EvtInfo_Implausible_Data_Received_from_Radio_U048500: start-on-event=DemSatellite_0InternalBehavior/GetEventStatus, operation=EvtInfo_Implausible_Data_Received_from_Radio_U048500.GetEventStatus
        OpEventGetEventStatus_GetEventStatus_Event_Implausible_Data_Received_from_Radio_U048500: start-on-event=DemSatellite_0InternalBehavior/GetEventStatus, operation=Event_Implausible_Data_Received_from_Radio_U048500.GetEventStatus
        OpEventGetEventStatus_GetEventStatus_EvtInfo_Implausible_Data_received_from_TRSKM_module_U14A000: start-on-event=DemSatellite_0InternalBehavior/GetEventStatus, operation=EvtInfo_Implausible_Data_received_from_TRSKM_module_U14A000.GetEventStatus
        OpEventGetEventStatus_GetEventStatus_Event_Implausible_Data_received_from_TRSKM_module_U14A000: start-on-event=DemSatellite_0InternalBehavior/GetEventStatus, operation=Event_Implausible_Data_received_from_TRSKM_module_U14A000.GetEventStatus
        OpEventGetEventStatus_GetEventStatus_EvtInfo_Front_Camera_Performance_or_Incorrect_Operation_B23C592: start-on-event=DemSatellite_0InternalBehavior/GetEventStatus, operation=EvtInfo_Front_Camera_Performance_or_Incorrect_Operation_B23C592.GetEventStatus
        OpEventGetEventStatus_GetEventStatus_Event_Front_Camera_Performance_or_Incorrect_Operation_B23C592: start-on-event=DemSatellite_0InternalBehavior/GetEventStatus, operation=Event_Front_Camera_Performance_or_Incorrect_Operation_B23C592.GetEventStatus
        OpEventGetEventStatus_GetEventStatus_EvtInfo_Loss_Communication_with_TRS_Knob_Module_U12B900: start-on-event=DemSatellite_0InternalBehavior/GetEventStatus, operation=EvtInfo_Loss_Communication_with_TRS_Knob_Module_U12B900.GetEventStatus
        OpEventGetEventStatus_GetEventStatus_Event_Loss_Communication_with_TRS_Knob_Module_U12B900: start-on-event=DemSatellite_0InternalBehavior/GetEventStatus, operation=Event_Loss_Communication_with_TRS_Knob_Module_U12B900.GetEventStatus
        OpEventGetEventStatus_GetEventStatus_EvtInfo_PTS_Sensor_7_Circuit_Open_B129413: start-on-event=DemSatellite_0InternalBehavior/GetEventStatus, operation=EvtInfo_PTS_Sensor_7_Circuit_Open_B129413.GetEventStatus
        OpEventGetEventStatus_GetEventStatus_Event_PTS_Sensor_7_Circuit_Open_B129413: start-on-event=DemSatellite_0InternalBehavior/GetEventStatus, operation=Event_PTS_Sensor_7_Circuit_Open_B129413.GetEventStatus
        OpEventGetEventStatus_GetEventStatus_EvtInfo_Front_Sensors_PS_Bus_Sig_Msg_Failures_B212A08: start-on-event=DemSatellite_0InternalBehavior/GetEventStatus, operation=EvtInfo_Front_Sensors_PS_Bus_Sig_Msg_Failures_B212A08.GetEventStatus
        OpEventGetEventStatus_GetEventStatus_Event_Front_Sensors_PS_Bus_Sig_Msg_Failures_B212A08: start-on-event=DemSatellite_0InternalBehavior/GetEventStatus, operation=Event_Front_Sensors_PS_Bus_Sig_Msg_Failures_B212A08.GetEventStatus
        OpEventGetEventStatus_GetEventStatus_EvtInfo_Lost_Communication_With_PSC_Module_A_U013100: start-on-event=DemSatellite_0InternalBehavior/GetEventStatus, operation=EvtInfo_Lost_Communication_With_PSC_Module_A_U013100.GetEventStatus
        OpEventGetEventStatus_GetEventStatus_Event_Lost_Communication_With_PSC_Module_A_U013100: start-on-event=DemSatellite_0InternalBehavior/GetEventStatus, operation=Event_Lost_Communication_With_PSC_Module_A_U013100.GetEventStatus
        OpEventGetEventStatus_GetEventStatus_EvtInfo_Lost_Communication_with_Front_Camera_U026500: start-on-event=DemSatellite_0InternalBehavior/GetEventStatus, operation=EvtInfo_Lost_Communication_with_Front_Camera_U026500.GetEventStatus
        OpEventGetEventStatus_GetEventStatus_Event_Lost_Communication_with_Front_Camera_U026500: start-on-event=DemSatellite_0InternalBehavior/GetEventStatus, operation=Event_Lost_Communication_with_Front_Camera_U026500.GetEventStatus
        OpEventGetEventStatus_GetEventStatus_EvtInfo_PTS_Sensor_3_Performance_or_Incorrect_Operation_B129092: start-on-event=DemSatellite_0InternalBehavior/GetEventStatus, operation=EvtInfo_PTS_Sensor_3_Performance_or_Incorrect_Operation_B129092.GetEventStatus
        OpEventGetEventStatus_GetEventStatus_Event_PTS_Sensor_3_Performance_or_Incorrect_Operation_B129092: start-on-event=DemSatellite_0InternalBehavior/GetEventStatus, operation=Event_PTS_Sensor_3_Performance_or_Incorrect_Operation_B129092.GetEventStatus
        OpEventGetEventStatus_GetEventStatus_EvtInfo_PTS_Sensor_8_Performance_or_Incorrect_Operation_B129592: start-on-event=DemSatellite_0InternalBehavior/GetEventStatus, operation=EvtInfo_PTS_Sensor_8_Performance_or_Incorrect_Operation_B129592.GetEventStatus
        OpEventGetEventStatus_GetEventStatus_Event_PTS_Sensor_8_Performance_or_Incorrect_Operation_B129592: start-on-event=DemSatellite_0InternalBehavior/GetEventStatus, operation=Event_PTS_Sensor_8_Performance_or_Incorrect_Operation_B129592.GetEventStatus
        OpEventGetEventStatus_GetEventStatus_EvtInfo_PPP_Assist_Switch_Stuck_B12B22A: start-on-event=DemSatellite_0InternalBehavior/GetEventStatus, operation=EvtInfo_PPP_Assist_Switch_Stuck_B12B22A.GetEventStatus
        OpEventGetEventStatus_GetEventStatus_Event_PPP_Assist_Switch_Stuck_B12B22A: start-on-event=DemSatellite_0InternalBehavior/GetEventStatus, operation=Event_PPP_Assist_Switch_Stuck_B12B22A.GetEventStatus
        OpEventGetEventStatus_GetEventStatus_EvtInfo_Implausible_data_received_from_ECM_U040100: start-on-event=DemSatellite_0InternalBehavior/GetEventStatus, operation=EvtInfo_Implausible_data_received_from_ECM_U040100.GetEventStatus
        OpEventGetEventStatus_GetEventStatus_Event_Implausible_data_received_from_ECM_U040100: start-on-event=DemSatellite_0InternalBehavior/GetEventStatus, operation=Event_Implausible_data_received_from_ECM_U040100.GetEventStatus
        OpEventGetEventStatus_GetEventStatus_EvtInfo_PTS_Sensor_10_Circuit_Open_B129713: start-on-event=DemSatellite_0InternalBehavior/GetEventStatus, operation=EvtInfo_PTS_Sensor_10_Circuit_Open_B129713.GetEventStatus
        OpEventGetEventStatus_GetEventStatus_Event_PTS_Sensor_10_Circuit_Open_B129713: start-on-event=DemSatellite_0InternalBehavior/GetEventStatus, operation=Event_PTS_Sensor_10_Circuit_Open_B129713.GetEventStatus
        OpEventGetEventStatus_GetEventStatus_EvtInfo_Lost_Communication_With_BSC_module_1_U012900: start-on-event=DemSatellite_0InternalBehavior/GetEventStatus, operation=EvtInfo_Lost_Communication_With_BSC_module_1_U012900.GetEventStatus
        OpEventGetEventStatus_GetEventStatus_Event_Lost_Communication_With_BSC_module_1_U012900: start-on-event=DemSatellite_0InternalBehavior/GetEventStatus, operation=Event_Lost_Communication_With_BSC_module_1_U012900.GetEventStatus
        OpEventGetEventStatus_GetEventStatus_EvtInfo_PTS_Sensor_7_Performance_or_Incorrect_Operation_B129492: start-on-event=DemSatellite_0InternalBehavior/GetEventStatus, operation=EvtInfo_PTS_Sensor_7_Performance_or_Incorrect_Operation_B129492.GetEventStatus
        OpEventGetEventStatus_GetEventStatus_Event_PTS_Sensor_7_Performance_or_Incorrect_Operation_B129492: start-on-event=DemSatellite_0InternalBehavior/GetEventStatus, operation=Event_PTS_Sensor_7_Performance_or_Incorrect_Operation_B129492.GetEventStatus
        OpEventGetEventStatus_GetEventStatus_EvtInfo_Left_Camera_Performance_or_Incorrect_Operation_B23C692: start-on-event=DemSatellite_0InternalBehavior/GetEventStatus, operation=EvtInfo_Left_Camera_Performance_or_Incorrect_Operation_B23C692.GetEventStatus
        OpEventGetEventStatus_GetEventStatus_Event_Left_Camera_Performance_or_Incorrect_Operation_B23C692: start-on-event=DemSatellite_0InternalBehavior/GetEventStatus, operation=Event_Left_Camera_Performance_or_Incorrect_Operation_B23C692.GetEventStatus
        OpEventGetEventStatus_GetEventStatus_EvtInfo_Vehicle_Configuration_Mismatch_B223B00: start-on-event=DemSatellite_0InternalBehavior/GetEventStatus, operation=EvtInfo_Vehicle_Configuration_Mismatch_B223B00.GetEventStatus
        OpEventGetEventStatus_GetEventStatus_Event_Vehicle_Configuration_Mismatch_B223B00: start-on-event=DemSatellite_0InternalBehavior/GetEventStatus, operation=Event_Vehicle_Configuration_Mismatch_B223B00.GetEventStatus
        OpEventGetEventStatus_GetEventStatus_EvtInfo_PTS_Sensor_6_Circuit_Open_B129313: start-on-event=DemSatellite_0InternalBehavior/GetEventStatus, operation=EvtInfo_PTS_Sensor_6_Circuit_Open_B129313.GetEventStatus
        OpEventGetEventStatus_GetEventStatus_Event_PTS_Sensor_6_Circuit_Open_B129313: start-on-event=DemSatellite_0InternalBehavior/GetEventStatus, operation=Event_PTS_Sensor_6_Circuit_Open_B129313.GetEventStatus
        OpEventGetEventStatus_GetEventStatus_EvtInfo_Front_Camera_Circuit_Voltage_Out_of_Range_B23C51C: start-on-event=DemSatellite_0InternalBehavior/GetEventStatus, operation=EvtInfo_Front_Camera_Circuit_Voltage_Out_of_Range_B23C51C.GetEventStatus
        OpEventGetEventStatus_GetEventStatus_Event_Front_Camera_Circuit_Voltage_Out_of_Range_B23C51C: start-on-event=DemSatellite_0InternalBehavior/GetEventStatus, operation=Event_Front_Camera_Circuit_Voltage_Out_of_Range_B23C51C.GetEventStatus
        OpEventGetEventStatus_GetEventStatus_EvtInfo_Implausible_Data_From_BSC_Module_1_U041800: start-on-event=DemSatellite_0InternalBehavior/GetEventStatus, operation=EvtInfo_Implausible_Data_From_BSC_Module_1_U041800.GetEventStatus
        OpEventGetEventStatus_GetEventStatus_Event_Implausible_Data_From_BSC_Module_1_U041800: start-on-event=DemSatellite_0InternalBehavior/GetEventStatus, operation=Event_Implausible_Data_From_BSC_Module_1_U041800.GetEventStatus
        OpEventGetEventStatus_GetEventStatus_EvtInfo_PTS_Sensor_10_Performance_or_Incorrect_Operation_B129792: start-on-event=DemSatellite_0InternalBehavior/GetEventStatus, operation=EvtInfo_PTS_Sensor_10_Performance_or_Incorrect_Operation_B129792.GetEventStatus
        OpEventGetEventStatus_GetEventStatus_Event_PTS_Sensor_10_Performance_or_Incorrect_Operation_B129792: start-on-event=DemSatellite_0InternalBehavior/GetEventStatus, operation=Event_PTS_Sensor_10_Performance_or_Incorrect_Operation_B129792.GetEventStatus
        OpEventGetEventStatus_GetEventStatus_EvtInfo_PTS_Sensor_11_Circuit_Open_B129813: start-on-event=DemSatellite_0InternalBehavior/GetEventStatus, operation=EvtInfo_PTS_Sensor_11_Circuit_Open_B129813.GetEventStatus
        OpEventGetEventStatus_GetEventStatus_Event_PTS_Sensor_11_Circuit_Open_B129813: start-on-event=DemSatellite_0InternalBehavior/GetEventStatus, operation=Event_PTS_Sensor_11_Circuit_Open_B129813.GetEventStatus
        OpEventGetEventStatus_GetEventStatus_EvtInfo_ECU_Internal_Performance_B22A900: start-on-event=DemSatellite_0InternalBehavior/GetEventStatus, operation=EvtInfo_ECU_Internal_Performance_B22A900.GetEventStatus
        OpEventGetEventStatus_GetEventStatus_Event_ECU_Internal_Performance_B22A900: start-on-event=DemSatellite_0InternalBehavior/GetEventStatus, operation=Event_ECU_Internal_Performance_B22A900.GetEventStatus
        OpEventGetEventStatus_GetEventStatus_EvtInfo_PTS_Sensor_9_Performance_or_Incorrect_Operation_B129692: start-on-event=DemSatellite_0InternalBehavior/GetEventStatus, operation=EvtInfo_PTS_Sensor_9_Performance_or_Incorrect_Operation_B129692.GetEventStatus
        OpEventGetEventStatus_GetEventStatus_Event_PTS_Sensor_9_Performance_or_Incorrect_Operation_B129692: start-on-event=DemSatellite_0InternalBehavior/GetEventStatus, operation=Event_PTS_Sensor_9_Performance_or_Incorrect_Operation_B129692.GetEventStatus
        OpEventGetEventStatus_GetEventStatus_EvtInfo_Calibration_Not_Learned_Lost_Calibration_B228600: start-on-event=DemSatellite_0InternalBehavior/GetEventStatus, operation=EvtInfo_Calibration_Not_Learned_Lost_Calibration_B228600.GetEventStatus
        OpEventGetEventStatus_GetEventStatus_Event_Calibration_Not_Learned_Lost_Calibration_B228600: start-on-event=DemSatellite_0InternalBehavior/GetEventStatus, operation=Event_Calibration_Not_Learned_Lost_Calibration_B228600.GetEventStatus
        OpEventGetEventStatus_GetEventStatus_EvtInfo_Lost_Communication_with_ORC_U015100: start-on-event=DemSatellite_0InternalBehavior/GetEventStatus, operation=EvtInfo_Lost_Communication_with_ORC_U015100.GetEventStatus
        OpEventGetEventStatus_GetEventStatus_Event_Lost_Communication_with_ORC_U015100: start-on-event=DemSatellite_0InternalBehavior/GetEventStatus, operation=Event_Lost_Communication_with_ORC_U015100.GetEventStatus
        OpEventGetEventStatus_GetEventStatus_EvtInfo_PTS_Sensor_1_Circuit_Open_B128E13: start-on-event=DemSatellite_0InternalBehavior/GetEventStatus, operation=EvtInfo_PTS_Sensor_1_Circuit_Open_B128E13.GetEventStatus
        OpEventGetEventStatus_GetEventStatus_Event_PTS_Sensor_1_Circuit_Open_B128E13: start-on-event=DemSatellite_0InternalBehavior/GetEventStatus, operation=Event_PTS_Sensor_1_Circuit_Open_B128E13.GetEventStatus
        OpEventGetEventStatus_GetEventStatus_EvtInfo_Lost_Communication_with_Rear_Camera_U026400: start-on-event=DemSatellite_0InternalBehavior/GetEventStatus, operation=EvtInfo_Lost_Communication_with_Rear_Camera_U026400.GetEventStatus
        OpEventGetEventStatus_GetEventStatus_Event_Lost_Communication_with_Rear_Camera_U026400: start-on-event=DemSatellite_0InternalBehavior/GetEventStatus, operation=Event_Lost_Communication_with_Rear_Camera_U026400.GetEventStatus
        OpEventGetEventStatus_GetEventStatus_EvtInfo_HS_FD_CANR_Comm_Bus_Performance_U100B00: start-on-event=DemSatellite_0InternalBehavior/GetEventStatus, operation=EvtInfo_HS_FD_CANR_Comm_Bus_Performance_U100B00.GetEventStatus
        OpEventGetEventStatus_GetEventStatus_Event_HS_FD_CANR_Comm_Bus_Performance_U100B00: start-on-event=DemSatellite_0InternalBehavior/GetEventStatus, operation=Event_HS_FD_CANR_Comm_Bus_Performance_U100B00.GetEventStatus
        OpEventGetEventStatus_GetEventStatus_EvtInfo_Implausible_Data_Received_From_Body_Control_Module_U042200: start-on-event=DemSatellite_0InternalBehavior/GetEventStatus, operation=EvtInfo_Implausible_Data_Received_From_Body_Control_Module_U042200.GetEventStatus
        OpEventGetEventStatus_GetEventStatus_Event_Implausible_Data_Received_From_Body_Control_Module_U042200: start-on-event=DemSatellite_0InternalBehavior/GetEventStatus, operation=Event_Implausible_Data_Received_From_Body_Control_Module_U042200.GetEventStatus
        OpEventGetEventStatus_GetEventStatus_EvtInfo_Lost_Communication_With_BCM_U014000: start-on-event=DemSatellite_0InternalBehavior/GetEventStatus, operation=EvtInfo_Lost_Communication_With_BCM_U014000.GetEventStatus
        OpEventGetEventStatus_GetEventStatus_Event_Lost_Communication_With_BCM_U014000: start-on-event=DemSatellite_0InternalBehavior/GetEventStatus, operation=Event_Lost_Communication_With_BCM_U014000.GetEventStatus
        OpEventGetEventStatus_GetEventStatus_EvtInfo_PTS_Sensor_2_Circuit_Open_B128F13: start-on-event=DemSatellite_0InternalBehavior/GetEventStatus, operation=EvtInfo_PTS_Sensor_2_Circuit_Open_B128F13.GetEventStatus
        OpEventGetEventStatus_GetEventStatus_Event_PTS_Sensor_2_Circuit_Open_B128F13: start-on-event=DemSatellite_0InternalBehavior/GetEventStatus, operation=Event_PTS_Sensor_2_Circuit_Open_B128F13.GetEventStatus
        OpEventGetEventStatus_GetEventStatus_EvtInfo_PTS_Sensor_3_Circuit_Open_B129013: start-on-event=DemSatellite_0InternalBehavior/GetEventStatus, operation=EvtInfo_PTS_Sensor_3_Circuit_Open_B129013.GetEventStatus
        OpEventGetEventStatus_GetEventStatus_Event_PTS_Sensor_3_Circuit_Open_B129013: start-on-event=DemSatellite_0InternalBehavior/GetEventStatus, operation=Event_PTS_Sensor_3_Circuit_Open_B129013.GetEventStatus
        OpEventGetEventStatus_GetEventStatus_EvtInfo_ECU_In_Plant_Mode_C221200: start-on-event=DemSatellite_0InternalBehavior/GetEventStatus, operation=EvtInfo_ECU_In_Plant_Mode_C221200.GetEventStatus
        OpEventGetEventStatus_GetEventStatus_Event_ECU_In_Plant_Mode_C221200: start-on-event=DemSatellite_0InternalBehavior/GetEventStatus, operation=Event_ECU_In_Plant_Mode_C221200.GetEventStatus
        OpEventGetEventStatus_GetEventStatus_EvtInfo_Implausible_Data_from_ORC_module_U045500: start-on-event=DemSatellite_0InternalBehavior/GetEventStatus, operation=EvtInfo_Implausible_Data_from_ORC_module_U045500.GetEventStatus
        OpEventGetEventStatus_GetEventStatus_Event_Implausible_Data_from_ORC_module_U045500: start-on-event=DemSatellite_0InternalBehavior/GetEventStatus, operation=Event_Implausible_Data_from_ORC_module_U045500.GetEventStatus
        OpEventGetEventStatus_GetEventStatus_EvtInfo_Right_Camera_Performance_or_Incorrect_Operation_B23C792: start-on-event=DemSatellite_0InternalBehavior/GetEventStatus, operation=EvtInfo_Right_Camera_Performance_or_Incorrect_Operation_B23C792.GetEventStatus
        OpEventGetEventStatus_GetEventStatus_Event_Right_Camera_Performance_or_Incorrect_Operation_B23C792: start-on-event=DemSatellite_0InternalBehavior/GetEventStatus, operation=Event_Right_Camera_Performance_or_Incorrect_Operation_B23C792.GetEventStatus
        OpEventGetEventStatus_GetEventStatus_EvtInfo_Rear_Sensors_PS_VltgeAboveThreshold_B212B17: start-on-event=DemSatellite_0InternalBehavior/GetEventStatus, operation=EvtInfo_Rear_Sensors_PS_VltgeAboveThreshold_B212B17.GetEventStatus
        OpEventGetEventStatus_GetEventStatus_Event_Rear_Sensors_PS_VltgeAboveThreshold_B212B17: start-on-event=DemSatellite_0InternalBehavior/GetEventStatus, operation=Event_Rear_Sensors_PS_VltgeAboveThreshold_B212B17.GetEventStatus
        OpEventGetEventStatus_GetEventStatus_EvtInfo_PTS_Sensor_6_Performance_or_Incorrect_Operation_B129392: start-on-event=DemSatellite_0InternalBehavior/GetEventStatus, operation=EvtInfo_PTS_Sensor_6_Performance_or_Incorrect_Operation_B129392.GetEventStatus
        OpEventGetEventStatus_GetEventStatus_Event_PTS_Sensor_6_Performance_or_Incorrect_Operation_B129392: start-on-event=DemSatellite_0InternalBehavior/GetEventStatus, operation=Event_PTS_Sensor_6_Performance_or_Incorrect_Operation_B129392.GetEventStatus
        OpEventGetEventStatus_GetEventStatus_GeneralEvtInfo: start-on-event=DemSatellite_0InternalBehavior/GetEventStatus, operation=GeneralEvtInfo.GetEventStatus
        OpEventGetEventFailed_GetEventFailed_EvtInfo_Dem_SystemInternalFailure: start-on-event=DemSatellite_0InternalBehavior/GetEventFailed, operation=EvtInfo_Dem_SystemInternalFailure.GetEventFailed
        OpEventGetEventFailed_GetEventFailed_Event_Dem_SystemInternalFailure: start-on-event=DemSatellite_0InternalBehavior/GetEventFailed, operation=Event_Dem_SystemInternalFailure.GetEventFailed
        OpEventGetEventFailed_GetEventFailed_EvtInfo_Invalid_Data_Received_From_Power_Steering_Control_Module_U042000: start-on-event=DemSatellite_0InternalBehavior/GetEventFailed, operation=EvtInfo_Invalid_Data_Received_From_Power_Steering_Control_Module_U042000.GetEventFailed
        OpEventGetEventFailed_GetEventFailed_Event_Invalid_Data_Received_From_Power_Steering_Control_Module_U042000: start-on-event=DemSatellite_0InternalBehavior/GetEventFailed, operation=Event_Invalid_Data_Received_From_Power_Steering_Control_Module_U042000.GetEventFailed
        OpEventGetEventFailed_GetEventFailed_EvtInfo_Lost_Communication_with_Left_Camera_U026600: start-on-event=DemSatellite_0InternalBehavior/GetEventFailed, operation=EvtInfo_Lost_Communication_with_Left_Camera_U026600.GetEventFailed
        OpEventGetEventFailed_GetEventFailed_Event_Lost_Communication_with_Left_Camera_U026600: start-on-event=DemSatellite_0InternalBehavior/GetEventFailed, operation=Event_Lost_Communication_with_Left_Camera_U026600.GetEventFailed
        OpEventGetEventFailed_GetEventFailed_EvtInfo_Front_Sensors_PS_VltgeBelowThreshold_B212A16: start-on-event=DemSatellite_0InternalBehavior/GetEventFailed, operation=EvtInfo_Front_Sensors_PS_VltgeBelowThreshold_B212A16.GetEventFailed
        OpEventGetEventFailed_GetEventFailed_Event_Front_Sensors_PS_VltgeBelowThreshold_B212A16: start-on-event=DemSatellite_0InternalBehavior/GetEventFailed, operation=Event_Front_Sensors_PS_VltgeBelowThreshold_B212A16.GetEventFailed
        OpEventGetEventFailed_GetEventFailed_EvtInfo_Left_Camera_Circuit_Voltage_Out_of_Range_B23C61C: start-on-event=DemSatellite_0InternalBehavior/GetEventFailed, operation=EvtInfo_Left_Camera_Circuit_Voltage_Out_of_Range_B23C61C.GetEventFailed
        OpEventGetEventFailed_GetEventFailed_Event_Left_Camera_Circuit_Voltage_Out_of_Range_B23C61C: start-on-event=DemSatellite_0InternalBehavior/GetEventFailed, operation=Event_Left_Camera_Circuit_Voltage_Out_of_Range_B23C61C.GetEventFailed
        OpEventGetEventFailed_GetEventFailed_EvtInfo_Rear_Sensors_PS_VltgeBelowThreshold_B212B16: start-on-event=DemSatellite_0InternalBehavior/GetEventFailed, operation=EvtInfo_Rear_Sensors_PS_VltgeBelowThreshold_B212B16.GetEventFailed
        OpEventGetEventFailed_GetEventFailed_Event_Rear_Sensors_PS_VltgeBelowThreshold_B212B16: start-on-event=DemSatellite_0InternalBehavior/GetEventFailed, operation=Event_Rear_Sensors_PS_VltgeBelowThreshold_B212B16.GetEventFailed
        OpEventGetEventFailed_GetEventFailed_EvtInfo_Rear_Sensors_PS_Bus_Sig_Msg_Failures_B212B08: start-on-event=DemSatellite_0InternalBehavior/GetEventFailed, operation=EvtInfo_Rear_Sensors_PS_Bus_Sig_Msg_Failures_B212B08.GetEventFailed
        OpEventGetEventFailed_GetEventFailed_Event_Rear_Sensors_PS_Bus_Sig_Msg_Failures_B212B08: start-on-event=DemSatellite_0InternalBehavior/GetEventFailed, operation=Event_Rear_Sensors_PS_Bus_Sig_Msg_Failures_B212B08.GetEventFailed
        OpEventGetEventFailed_GetEventFailed_EvtInfo_Rear_Camera_Circuit_Voltage_Out_of_Range_B217A1C: start-on-event=DemSatellite_0InternalBehavior/GetEventFailed, operation=EvtInfo_Rear_Camera_Circuit_Voltage_Out_of_Range_B217A1C.GetEventFailed
        OpEventGetEventFailed_GetEventFailed_Event_Rear_Camera_Circuit_Voltage_Out_of_Range_B217A1C: start-on-event=DemSatellite_0InternalBehavior/GetEventFailed, operation=Event_Rear_Camera_Circuit_Voltage_Out_of_Range_B217A1C.GetEventFailed
        OpEventGetEventFailed_GetEventFailed_EvtInfo_PTS_Sensor_12_Performance_or_Incorrect_Operation_B129992: start-on-event=DemSatellite_0InternalBehavior/GetEventFailed, operation=EvtInfo_PTS_Sensor_12_Performance_or_Incorrect_Operation_B129992.GetEventFailed
        OpEventGetEventFailed_GetEventFailed_Event_PTS_Sensor_12_Performance_or_Incorrect_Operation_B129992: start-on-event=DemSatellite_0InternalBehavior/GetEventFailed, operation=Event_PTS_Sensor_12_Performance_or_Incorrect_Operation_B129992.GetEventFailed
        OpEventGetEventFailed_GetEventFailed_EvtInfo_Battery_Voltage_Over_Voltage_B210C17: start-on-event=DemSatellite_0InternalBehavior/GetEventFailed, operation=EvtInfo_Battery_Voltage_Over_Voltage_B210C17.GetEventFailed
        OpEventGetEventFailed_GetEventFailed_Event_Battery_Voltage_Over_Voltage_B210C17: start-on-event=DemSatellite_0InternalBehavior/GetEventFailed, operation=Event_Battery_Voltage_Over_Voltage_B210C17.GetEventFailed
        OpEventGetEventFailed_GetEventFailed_EvtInfo_Front_Sensors_PS_VltgeAboveThreshold_B212A17: start-on-event=DemSatellite_0InternalBehavior/GetEventFailed, operation=EvtInfo_Front_Sensors_PS_VltgeAboveThreshold_B212A17.GetEventFailed
        OpEventGetEventFailed_GetEventFailed_Event_Front_Sensors_PS_VltgeAboveThreshold_B212A17: start-on-event=DemSatellite_0InternalBehavior/GetEventFailed, operation=Event_Front_Sensors_PS_VltgeAboveThreshold_B212A17.GetEventFailed
        OpEventGetEventFailed_GetEventFailed_EvtInfo_PTS_Sensor_4_Circuit_Open_B129113: start-on-event=DemSatellite_0InternalBehavior/GetEventFailed, operation=EvtInfo_PTS_Sensor_4_Circuit_Open_B129113.GetEventFailed
        OpEventGetEventFailed_GetEventFailed_Event_PTS_Sensor_4_Circuit_Open_B129113: start-on-event=DemSatellite_0InternalBehavior/GetEventFailed, operation=Event_PTS_Sensor_4_Circuit_Open_B129113.GetEventFailed
        OpEventGetEventFailed_GetEventFailed_EvtInfo_PTS_Sensor_12_Circuit_Open_B129913: start-on-event=DemSatellite_0InternalBehavior/GetEventFailed, operation=EvtInfo_PTS_Sensor_12_Circuit_Open_B129913.GetEventFailed
        OpEventGetEventFailed_GetEventFailed_Event_PTS_Sensor_12_Circuit_Open_B129913: start-on-event=DemSatellite_0InternalBehavior/GetEventFailed, operation=Event_PTS_Sensor_12_Circuit_Open_B129913.GetEventFailed
        OpEventGetEventFailed_GetEventFailed_EvtInfo_PTS_Sensor_11_Performance_or_Incorrect_Operation_B129892: start-on-event=DemSatellite_0InternalBehavior/GetEventFailed, operation=EvtInfo_PTS_Sensor_11_Performance_or_Incorrect_Operation_B129892.GetEventFailed
        OpEventGetEventFailed_GetEventFailed_Event_PTS_Sensor_11_Performance_or_Incorrect_Operation_B129892: start-on-event=DemSatellite_0InternalBehavior/GetEventFailed, operation=Event_PTS_Sensor_11_Performance_or_Incorrect_Operation_B129892.GetEventFailed
        OpEventGetEventFailed_GetEventFailed_EvtInfo_Lost_Communication_With_Radio_U018400: start-on-event=DemSatellite_0InternalBehavior/GetEventFailed, operation=EvtInfo_Lost_Communication_With_Radio_U018400.GetEventFailed
        OpEventGetEventFailed_GetEventFailed_Event_Lost_Communication_With_Radio_U018400: start-on-event=DemSatellite_0InternalBehavior/GetEventFailed, operation=Event_Lost_Communication_With_Radio_U018400.GetEventFailed
        OpEventGetEventFailed_GetEventFailed_EvtInfo_Park_Assist_PTS_Switch_Stuck_B12852A: start-on-event=DemSatellite_0InternalBehavior/GetEventFailed, operation=EvtInfo_Park_Assist_PTS_Switch_Stuck_B12852A.GetEventFailed
        OpEventGetEventFailed_GetEventFailed_Event_Park_Assist_PTS_Switch_Stuck_B12852A: start-on-event=DemSatellite_0InternalBehavior/GetEventFailed, operation=Event_Park_Assist_PTS_Switch_Stuck_B12852A.GetEventFailed
        OpEventGetEventFailed_GetEventFailed_EvtInfo_PTS_Sensor_5_Circuit_Open_B129213: start-on-event=DemSatellite_0InternalBehavior/GetEventFailed, operation=EvtInfo_PTS_Sensor_5_Circuit_Open_B129213.GetEventFailed
        OpEventGetEventFailed_GetEventFailed_Event_PTS_Sensor_5_Circuit_Open_B129213: start-on-event=DemSatellite_0InternalBehavior/GetEventFailed, operation=Event_PTS_Sensor_5_Circuit_Open_B129213.GetEventFailed
        OpEventGetEventFailed_GetEventFailed_EvtInfo_PTS_Sensor_5_Performance_or_Incorrect_Operation_B129292: start-on-event=DemSatellite_0InternalBehavior/GetEventFailed, operation=EvtInfo_PTS_Sensor_5_Performance_or_Incorrect_Operation_B129292.GetEventFailed
        OpEventGetEventFailed_GetEventFailed_Event_PTS_Sensor_5_Performance_or_Incorrect_Operation_B129292: start-on-event=DemSatellite_0InternalBehavior/GetEventFailed, operation=Event_PTS_Sensor_5_Performance_or_Incorrect_Operation_B129292.GetEventFailed
        OpEventGetEventFailed_GetEventFailed_EvtInfo_Battery_Voltage_Under_Voltage_B210C16: start-on-event=DemSatellite_0InternalBehavior/GetEventFailed, operation=EvtInfo_Battery_Voltage_Under_Voltage_B210C16.GetEventFailed
        OpEventGetEventFailed_GetEventFailed_Event_Battery_Voltage_Under_Voltage_B210C16: start-on-event=DemSatellite_0InternalBehavior/GetEventFailed, operation=Event_Battery_Voltage_Under_Voltage_B210C16.GetEventFailed
        OpEventGetEventFailed_GetEventFailed_EvtInfo_PTS_Sensor_4_Performance_or_Incorrect_Operation_B129192: start-on-event=DemSatellite_0InternalBehavior/GetEventFailed, operation=EvtInfo_PTS_Sensor_4_Performance_or_Incorrect_Operation_B129192.GetEventFailed
        OpEventGetEventFailed_GetEventFailed_Event_PTS_Sensor_4_Performance_or_Incorrect_Operation_B129192: start-on-event=DemSatellite_0InternalBehavior/GetEventFailed, operation=Event_PTS_Sensor_4_Performance_or_Incorrect_Operation_B129192.GetEventFailed
        OpEventGetEventFailed_GetEventFailed_EvtInfo_HS_FD_CAN2_Comm_Bus_Performance_U104E00: start-on-event=DemSatellite_0InternalBehavior/GetEventFailed, operation=EvtInfo_HS_FD_CAN2_Comm_Bus_Performance_U104E00.GetEventFailed
        OpEventGetEventFailed_GetEventFailed_Event_HS_FD_CAN2_Comm_Bus_Performance_U104E00: start-on-event=DemSatellite_0InternalBehavior/GetEventFailed, operation=Event_HS_FD_CAN2_Comm_Bus_Performance_U104E00.GetEventFailed
        OpEventGetEventFailed_GetEventFailed_EvtInfo_PTS_Sensor_9_Circuit_Open_B129613: start-on-event=DemSatellite_0InternalBehavior/GetEventFailed, operation=EvtInfo_PTS_Sensor_9_Circuit_Open_B129613.GetEventFailed
        OpEventGetEventFailed_GetEventFailed_Event_PTS_Sensor_9_Circuit_Open_B129613: start-on-event=DemSatellite_0InternalBehavior/GetEventFailed, operation=Event_PTS_Sensor_9_Circuit_Open_B129613.GetEventFailed
        OpEventGetEventFailed_GetEventFailed_EvtInfo_Loss_of_Comm_With_Engine_Control_Module_U010000: start-on-event=DemSatellite_0InternalBehavior/GetEventFailed, operation=EvtInfo_Loss_of_Comm_With_Engine_Control_Module_U010000.GetEventFailed
        OpEventGetEventFailed_GetEventFailed_Event_Loss_of_Comm_With_Engine_Control_Module_U010000: start-on-event=DemSatellite_0InternalBehavior/GetEventFailed, operation=Event_Loss_of_Comm_With_Engine_Control_Module_U010000.GetEventFailed
        OpEventGetEventFailed_GetEventFailed_EvtInfo_Lost_Communication_with_Right_Camera_U026700: start-on-event=DemSatellite_0InternalBehavior/GetEventFailed, operation=EvtInfo_Lost_Communication_with_Right_Camera_U026700.GetEventFailed
        OpEventGetEventFailed_GetEventFailed_Event_Lost_Communication_with_Right_Camera_U026700: start-on-event=DemSatellite_0InternalBehavior/GetEventFailed, operation=Event_Lost_Communication_with_Right_Camera_U026700.GetEventFailed
        OpEventGetEventFailed_GetEventFailed_EvtInfo_PTS_Sensor_1_Performance_or_Incorrect_Operation_B128E92: start-on-event=DemSatellite_0InternalBehavior/GetEventFailed, operation=EvtInfo_PTS_Sensor_1_Performance_or_Incorrect_Operation_B128E92.GetEventFailed
        OpEventGetEventFailed_GetEventFailed_Event_PTS_Sensor_1_Performance_or_Incorrect_Operation_B128E92: start-on-event=DemSatellite_0InternalBehavior/GetEventFailed, operation=Event_PTS_Sensor_1_Performance_or_Incorrect_Operation_B128E92.GetEventFailed
        OpEventGetEventFailed_GetEventFailed_EvtInfo_Rear_Camera_Performance_or_Incorrect_Operation_B217A92: start-on-event=DemSatellite_0InternalBehavior/GetEventFailed, operation=EvtInfo_Rear_Camera_Performance_or_Incorrect_Operation_B217A92.GetEventFailed
        OpEventGetEventFailed_GetEventFailed_Event_Rear_Camera_Performance_or_Incorrect_Operation_B217A92: start-on-event=DemSatellite_0InternalBehavior/GetEventFailed, operation=Event_Rear_Camera_Performance_or_Incorrect_Operation_B217A92.GetEventFailed
        OpEventGetEventFailed_GetEventFailed_EvtInfo_PTS_Sensor_2_Performance_or_Incorrect_Operation_B128F92: start-on-event=DemSatellite_0InternalBehavior/GetEventFailed, operation=EvtInfo_PTS_Sensor_2_Performance_or_Incorrect_Operation_B128F92.GetEventFailed
        OpEventGetEventFailed_GetEventFailed_Event_PTS_Sensor_2_Performance_or_Incorrect_Operation_B128F92: start-on-event=DemSatellite_0InternalBehavior/GetEventFailed, operation=Event_PTS_Sensor_2_Performance_or_Incorrect_Operation_B128F92.GetEventFailed
        OpEventGetEventFailed_GetEventFailed_EvtInfo_Right_Camera_Circuit_Voltage_Out_of_Range_B23C71C: start-on-event=DemSatellite_0InternalBehavior/GetEventFailed, operation=EvtInfo_Right_Camera_Circuit_Voltage_Out_of_Range_B23C71C.GetEventFailed
        OpEventGetEventFailed_GetEventFailed_Event_Right_Camera_Circuit_Voltage_Out_of_Range_B23C71C: start-on-event=DemSatellite_0InternalBehavior/GetEventFailed, operation=Event_Right_Camera_Circuit_Voltage_Out_of_Range_B23C71C.GetEventFailed
        OpEventGetEventFailed_GetEventFailed_EvtInfo_PTS_Sensor_8_Circuit_Open_B129513: start-on-event=DemSatellite_0InternalBehavior/GetEventFailed, operation=EvtInfo_PTS_Sensor_8_Circuit_Open_B129513.GetEventFailed
        OpEventGetEventFailed_GetEventFailed_Event_PTS_Sensor_8_Circuit_Open_B129513: start-on-event=DemSatellite_0InternalBehavior/GetEventFailed, operation=Event_PTS_Sensor_8_Circuit_Open_B129513.GetEventFailed
        OpEventGetEventFailed_GetEventFailed_EvtInfo_Implausible_Data_Received_from_Radio_U048500: start-on-event=DemSatellite_0InternalBehavior/GetEventFailed, operation=EvtInfo_Implausible_Data_Received_from_Radio_U048500.GetEventFailed
        OpEventGetEventFailed_GetEventFailed_Event_Implausible_Data_Received_from_Radio_U048500: start-on-event=DemSatellite_0InternalBehavior/GetEventFailed, operation=Event_Implausible_Data_Received_from_Radio_U048500.GetEventFailed
        OpEventGetEventFailed_GetEventFailed_EvtInfo_Implausible_Data_received_from_TRSKM_module_U14A000: start-on-event=DemSatellite_0InternalBehavior/GetEventFailed, operation=EvtInfo_Implausible_Data_received_from_TRSKM_module_U14A000.GetEventFailed
        OpEventGetEventFailed_GetEventFailed_Event_Implausible_Data_received_from_TRSKM_module_U14A000: start-on-event=DemSatellite_0InternalBehavior/GetEventFailed, operation=Event_Implausible_Data_received_from_TRSKM_module_U14A000.GetEventFailed
        OpEventGetEventFailed_GetEventFailed_EvtInfo_Front_Camera_Performance_or_Incorrect_Operation_B23C592: start-on-event=DemSatellite_0InternalBehavior/GetEventFailed, operation=EvtInfo_Front_Camera_Performance_or_Incorrect_Operation_B23C592.GetEventFailed
        OpEventGetEventFailed_GetEventFailed_Event_Front_Camera_Performance_or_Incorrect_Operation_B23C592: start-on-event=DemSatellite_0InternalBehavior/GetEventFailed, operation=Event_Front_Camera_Performance_or_Incorrect_Operation_B23C592.GetEventFailed
        OpEventGetEventFailed_GetEventFailed_EvtInfo_Loss_Communication_with_TRS_Knob_Module_U12B900: start-on-event=DemSatellite_0InternalBehavior/GetEventFailed, operation=EvtInfo_Loss_Communication_with_TRS_Knob_Module_U12B900.GetEventFailed
        OpEventGetEventFailed_GetEventFailed_Event_Loss_Communication_with_TRS_Knob_Module_U12B900: start-on-event=DemSatellite_0InternalBehavior/GetEventFailed, operation=Event_Loss_Communication_with_TRS_Knob_Module_U12B900.GetEventFailed
        OpEventGetEventFailed_GetEventFailed_EvtInfo_PTS_Sensor_7_Circuit_Open_B129413: start-on-event=DemSatellite_0InternalBehavior/GetEventFailed, operation=EvtInfo_PTS_Sensor_7_Circuit_Open_B129413.GetEventFailed
        OpEventGetEventFailed_GetEventFailed_Event_PTS_Sensor_7_Circuit_Open_B129413: start-on-event=DemSatellite_0InternalBehavior/GetEventFailed, operation=Event_PTS_Sensor_7_Circuit_Open_B129413.GetEventFailed
        OpEventGetEventFailed_GetEventFailed_EvtInfo_Front_Sensors_PS_Bus_Sig_Msg_Failures_B212A08: start-on-event=DemSatellite_0InternalBehavior/GetEventFailed, operation=EvtInfo_Front_Sensors_PS_Bus_Sig_Msg_Failures_B212A08.GetEventFailed
        OpEventGetEventFailed_GetEventFailed_Event_Front_Sensors_PS_Bus_Sig_Msg_Failures_B212A08: start-on-event=DemSatellite_0InternalBehavior/GetEventFailed, operation=Event_Front_Sensors_PS_Bus_Sig_Msg_Failures_B212A08.GetEventFailed
        OpEventGetEventFailed_GetEventFailed_EvtInfo_Lost_Communication_With_PSC_Module_A_U013100: start-on-event=DemSatellite_0InternalBehavior/GetEventFailed, operation=EvtInfo_Lost_Communication_With_PSC_Module_A_U013100.GetEventFailed
        OpEventGetEventFailed_GetEventFailed_Event_Lost_Communication_With_PSC_Module_A_U013100: start-on-event=DemSatellite_0InternalBehavior/GetEventFailed, operation=Event_Lost_Communication_With_PSC_Module_A_U013100.GetEventFailed
        OpEventGetEventFailed_GetEventFailed_EvtInfo_Lost_Communication_with_Front_Camera_U026500: start-on-event=DemSatellite_0InternalBehavior/GetEventFailed, operation=EvtInfo_Lost_Communication_with_Front_Camera_U026500.GetEventFailed
        OpEventGetEventFailed_GetEventFailed_Event_Lost_Communication_with_Front_Camera_U026500: start-on-event=DemSatellite_0InternalBehavior/GetEventFailed, operation=Event_Lost_Communication_with_Front_Camera_U026500.GetEventFailed
        OpEventGetEventFailed_GetEventFailed_EvtInfo_PTS_Sensor_3_Performance_or_Incorrect_Operation_B129092: start-on-event=DemSatellite_0InternalBehavior/GetEventFailed, operation=EvtInfo_PTS_Sensor_3_Performance_or_Incorrect_Operation_B129092.GetEventFailed
        OpEventGetEventFailed_GetEventFailed_Event_PTS_Sensor_3_Performance_or_Incorrect_Operation_B129092: start-on-event=DemSatellite_0InternalBehavior/GetEventFailed, operation=Event_PTS_Sensor_3_Performance_or_Incorrect_Operation_B129092.GetEventFailed
        OpEventGetEventFailed_GetEventFailed_EvtInfo_PTS_Sensor_8_Performance_or_Incorrect_Operation_B129592: start-on-event=DemSatellite_0InternalBehavior/GetEventFailed, operation=EvtInfo_PTS_Sensor_8_Performance_or_Incorrect_Operation_B129592.GetEventFailed
        OpEventGetEventFailed_GetEventFailed_Event_PTS_Sensor_8_Performance_or_Incorrect_Operation_B129592: start-on-event=DemSatellite_0InternalBehavior/GetEventFailed, operation=Event_PTS_Sensor_8_Performance_or_Incorrect_Operation_B129592.GetEventFailed
        OpEventGetEventFailed_GetEventFailed_EvtInfo_PPP_Assist_Switch_Stuck_B12B22A: start-on-event=DemSatellite_0InternalBehavior/GetEventFailed, operation=EvtInfo_PPP_Assist_Switch_Stuck_B12B22A.GetEventFailed
        OpEventGetEventFailed_GetEventFailed_Event_PPP_Assist_Switch_Stuck_B12B22A: start-on-event=DemSatellite_0InternalBehavior/GetEventFailed, operation=Event_PPP_Assist_Switch_Stuck_B12B22A.GetEventFailed
        OpEventGetEventFailed_GetEventFailed_EvtInfo_Implausible_data_received_from_ECM_U040100: start-on-event=DemSatellite_0InternalBehavior/GetEventFailed, operation=EvtInfo_Implausible_data_received_from_ECM_U040100.GetEventFailed
        OpEventGetEventFailed_GetEventFailed_Event_Implausible_data_received_from_ECM_U040100: start-on-event=DemSatellite_0InternalBehavior/GetEventFailed, operation=Event_Implausible_data_received_from_ECM_U040100.GetEventFailed
        OpEventGetEventFailed_GetEventFailed_EvtInfo_PTS_Sensor_10_Circuit_Open_B129713: start-on-event=DemSatellite_0InternalBehavior/GetEventFailed, operation=EvtInfo_PTS_Sensor_10_Circuit_Open_B129713.GetEventFailed
        OpEventGetEventFailed_GetEventFailed_Event_PTS_Sensor_10_Circuit_Open_B129713: start-on-event=DemSatellite_0InternalBehavior/GetEventFailed, operation=Event_PTS_Sensor_10_Circuit_Open_B129713.GetEventFailed
        OpEventGetEventFailed_GetEventFailed_EvtInfo_Lost_Communication_With_BSC_module_1_U012900: start-on-event=DemSatellite_0InternalBehavior/GetEventFailed, operation=EvtInfo_Lost_Communication_With_BSC_module_1_U012900.GetEventFailed
        OpEventGetEventFailed_GetEventFailed_Event_Lost_Communication_With_BSC_module_1_U012900: start-on-event=DemSatellite_0InternalBehavior/GetEventFailed, operation=Event_Lost_Communication_With_BSC_module_1_U012900.GetEventFailed
        OpEventGetEventFailed_GetEventFailed_EvtInfo_PTS_Sensor_7_Performance_or_Incorrect_Operation_B129492: start-on-event=DemSatellite_0InternalBehavior/GetEventFailed, operation=EvtInfo_PTS_Sensor_7_Performance_or_Incorrect_Operation_B129492.GetEventFailed
        OpEventGetEventFailed_GetEventFailed_Event_PTS_Sensor_7_Performance_or_Incorrect_Operation_B129492: start-on-event=DemSatellite_0InternalBehavior/GetEventFailed, operation=Event_PTS_Sensor_7_Performance_or_Incorrect_Operation_B129492.GetEventFailed
        OpEventGetEventFailed_GetEventFailed_EvtInfo_Left_Camera_Performance_or_Incorrect_Operation_B23C692: start-on-event=DemSatellite_0InternalBehavior/GetEventFailed, operation=EvtInfo_Left_Camera_Performance_or_Incorrect_Operation_B23C692.GetEventFailed
        OpEventGetEventFailed_GetEventFailed_Event_Left_Camera_Performance_or_Incorrect_Operation_B23C692: start-on-event=DemSatellite_0InternalBehavior/GetEventFailed, operation=Event_Left_Camera_Performance_or_Incorrect_Operation_B23C692.GetEventFailed
        OpEventGetEventFailed_GetEventFailed_EvtInfo_Vehicle_Configuration_Mismatch_B223B00: start-on-event=DemSatellite_0InternalBehavior/GetEventFailed, operation=EvtInfo_Vehicle_Configuration_Mismatch_B223B00.GetEventFailed
        OpEventGetEventFailed_GetEventFailed_Event_Vehicle_Configuration_Mismatch_B223B00: start-on-event=DemSatellite_0InternalBehavior/GetEventFailed, operation=Event_Vehicle_Configuration_Mismatch_B223B00.GetEventFailed
        OpEventGetEventFailed_GetEventFailed_EvtInfo_PTS_Sensor_6_Circuit_Open_B129313: start-on-event=DemSatellite_0InternalBehavior/GetEventFailed, operation=EvtInfo_PTS_Sensor_6_Circuit_Open_B129313.GetEventFailed
        OpEventGetEventFailed_GetEventFailed_Event_PTS_Sensor_6_Circuit_Open_B129313: start-on-event=DemSatellite_0InternalBehavior/GetEventFailed, operation=Event_PTS_Sensor_6_Circuit_Open_B129313.GetEventFailed
        OpEventGetEventFailed_GetEventFailed_EvtInfo_Front_Camera_Circuit_Voltage_Out_of_Range_B23C51C: start-on-event=DemSatellite_0InternalBehavior/GetEventFailed, operation=EvtInfo_Front_Camera_Circuit_Voltage_Out_of_Range_B23C51C.GetEventFailed
        OpEventGetEventFailed_GetEventFailed_Event_Front_Camera_Circuit_Voltage_Out_of_Range_B23C51C: start-on-event=DemSatellite_0InternalBehavior/GetEventFailed, operation=Event_Front_Camera_Circuit_Voltage_Out_of_Range_B23C51C.GetEventFailed
        OpEventGetEventFailed_GetEventFailed_EvtInfo_Implausible_Data_From_BSC_Module_1_U041800: start-on-event=DemSatellite_0InternalBehavior/GetEventFailed, operation=EvtInfo_Implausible_Data_From_BSC_Module_1_U041800.GetEventFailed
        OpEventGetEventFailed_GetEventFailed_Event_Implausible_Data_From_BSC_Module_1_U041800: start-on-event=DemSatellite_0InternalBehavior/GetEventFailed, operation=Event_Implausible_Data_From_BSC_Module_1_U041800.GetEventFailed
        OpEventGetEventFailed_GetEventFailed_EvtInfo_PTS_Sensor_10_Performance_or_Incorrect_Operation_B129792: start-on-event=DemSatellite_0InternalBehavior/GetEventFailed, operation=EvtInfo_PTS_Sensor_10_Performance_or_Incorrect_Operation_B129792.GetEventFailed
        OpEventGetEventFailed_GetEventFailed_Event_PTS_Sensor_10_Performance_or_Incorrect_Operation_B129792: start-on-event=DemSatellite_0InternalBehavior/GetEventFailed, operation=Event_PTS_Sensor_10_Performance_or_Incorrect_Operation_B129792.GetEventFailed
        OpEventGetEventFailed_GetEventFailed_EvtInfo_PTS_Sensor_11_Circuit_Open_B129813: start-on-event=DemSatellite_0InternalBehavior/GetEventFailed, operation=EvtInfo_PTS_Sensor_11_Circuit_Open_B129813.GetEventFailed
        OpEventGetEventFailed_GetEventFailed_Event_PTS_Sensor_11_Circuit_Open_B129813: start-on-event=DemSatellite_0InternalBehavior/GetEventFailed, operation=Event_PTS_Sensor_11_Circuit_Open_B129813.GetEventFailed
        OpEventGetEventFailed_GetEventFailed_EvtInfo_ECU_Internal_Performance_B22A900: start-on-event=DemSatellite_0InternalBehavior/GetEventFailed, operation=EvtInfo_ECU_Internal_Performance_B22A900.GetEventFailed
        OpEventGetEventFailed_GetEventFailed_Event_ECU_Internal_Performance_B22A900: start-on-event=DemSatellite_0InternalBehavior/GetEventFailed, operation=Event_ECU_Internal_Performance_B22A900.GetEventFailed
        OpEventGetEventFailed_GetEventFailed_EvtInfo_PTS_Sensor_9_Performance_or_Incorrect_Operation_B129692: start-on-event=DemSatellite_0InternalBehavior/GetEventFailed, operation=EvtInfo_PTS_Sensor_9_Performance_or_Incorrect_Operation_B129692.GetEventFailed
